VERSION ""

NS_ :

BS_:

BU_: HUA FLR2 DACU

BO_ 786 FLR_Obj03_Vic1: 48 FLR2
 SG_ FLRObj03_ObjClass : 216|4@1+ (1,0) [0|0] ""  VCM
 SG_ FLRObj03_LongAccVar : 88|8@1+ (0.01,0) [0|2.55] "NotApplicable"  VCM
 SG_ FLRObj03_LifeTime : 24|16@1+ (0.1,0) [0|6553.5] "s"  VCM
 SG_ FLRObj03_LatExtLeft : 266|7@1+ (0.05,0) [0|6.35] "m"  VCM
 SG_ FLRObj03_ObjDynClass : 278|2@1+ (1,0) [0|0] ""  VCM
 SG_ FLRObj03_LongVel : 240|13@1+ (0.032,-80) [-80|182.112] "m_per_s"  VCM
 SG_ FLRObj03_ObstacleConf : 297|7@1+ (0.01,0) [0|1.27] "NotApplicable"  VCM
 SG_ FLRObj03_LatExtRight : 193|7@1+ (0.05,-5) [-5|1.35] "m"  VCM
 SG_ FLRObj03_CRC : 0|16@1+ (1,0) [0|65535] "NotApplicable"  VCM
 SG_ FLRObj03_Height : 220|4@1+ (0.5,0) [0|7.5] "m"  VCM
 SG_ FLRObj03_LatExtRtVar : 64|8@1+ (0.01,0) [0|2.55] "NotApplicable"  VCM
 SG_ FLRObj03_AsilLvl : 304|2@1+ (1,0) [0|0] ""  VCM
 SG_ FLRObj03_TimeStamp : 200|16@1+ (0.1,0) [0|6553.5] "ms"  VCM
 SG_ FLRObj03_ExistConf : 290|7@1+ (0.01,0) [0|1.27] "NotApplicable"  VCM
 SG_ FLRObj03_LatExtLeftVar : 56|8@1+ (0.01,0) [0|2.55] "NotApplicable"  VCM
 SG_ FLRObj03_ObstacleConfRestricted : 308|7@1+ (0.01,0) [0|1.27] "NotApplicable"  VCM
 SG_ FLRObj03_Heading : 157|11@1+ (0.005818,-4.71) [-4.71|7.199446] "rad"  VCM
 SG_ FLRObj03_LatPosVar : 72|8@1+ (0.01,0) [0|2.55] "NotApplicable"  VCM
 SG_ FLRObj03_LatPos : 128|13@1+ (0.05,-180) [-180|229.55] "m"  VCM
 SG_ FLRObj03_LongExtBkVar : 96|8@1+ (0.01,0) [0|2.55] "NotApplicable"  VCM
 SG_ FLRObj03_CoastIndex : 273|5@1+ (1,0) [0|31] "NotApplicable"  VCM
 SG_ FLRObj03_LatAccVar : 48|8@1+ (0.1,0) [0|25.5] "NotApplicable"  VCM
 SG_ FLRObj03_LongAcc : 184|9@1+ (0.08,-20) [-20|20.88] "m_per_s_squared"  VCM
 SG_ FLRObj03_ObjDynClassRestricted : 306|2@1+ (1,0) [0|0] ""  VCM
 SG_ FLRObj03_ObjClassConf : 177|7@1+ (0.01,0) [0|1.27] "NotApplicable"  VCM
 SG_ FLRObj03_LatVel : 144|13@1+ (0.032,-80) [-80|182.112] "m_per_s"  VCM
 SG_ FLRObj03_LongExtFront : 224|10@1+ (0.05,0) [0|51.15] "m"  VCM
 SG_ FLRObj03_LongVelVar : 120|8@1+ (0.01,0) [0|2.55] "NotApplicable"  VCM
 SG_ FLRObj03_LatVelVar : 80|8@1+ (0.1,0) [0|25.5] "NotApplicable"  VCM
 SG_ FLRObj03_LongExtBack : 280|10@1+ (0.05,-50) [-50|1.15000000000001] "m"  VCM
 SG_ FLRObj03_LongPos : 253|13@1+ (0.05,-180) [-180|229.55] "m"  VCM
 SG_ FLRObj03_HeadingVar : 40|8@1+ (0.001,0) [0|0.255] "NotApplicable"  VCM
 SG_ FLRObj03_LongPosVar : 112|8@1+ (0.01,0) [0|2.55] "NotApplicable"  VCM
 SG_ FLRObj03_ObjID : 234|6@1+ (1,0) [0|63] "NotApplicable"  VCM
 SG_ FLRObj03_LongExtFrVar : 104|8@1+ (0.01,0) [0|2.55] "NotApplicable"  VCM
 SG_ FLRObj03_LatAcc : 168|9@1+ (0.08,-20) [-20|20.88] "m_per_s_squared"  VCM
 SG_ FLRObj03_Counter : 16|8@1+ (1,0) [0|255] "Count"  VCM
 SG_ FLRObj03_TrackStatus : 141|3@1+ (1,0) [0|0] ""  VCM

BO_ 785 FLR_Obj02_Vic1: 48 FLR2
 SG_ FLRObj02_CoastIndex : 273|5@1+ (1,0) [0|31] "NotApplicable"  VCM
 SG_ FLRObj02_LongExtBack : 280|10@1+ (0.05,-50) [-50|1.15000000000001] "m"  VCM
 SG_ FLRObj02_ObstacleConfRestricted : 308|7@1+ (0.01,0) [0|1.27] "NotApplicable"  VCM
 SG_ FLRObj02_LatVel : 144|13@1+ (0.032,-80) [-80|182.112] "m_per_s"  VCM
 SG_ FLRObj02_ObstacleConf : 297|7@1+ (0.01,0) [0|1.27] "NotApplicable"  VCM
 SG_ FLRObj02_AsilLvl : 304|2@1+ (1,0) [0|0] ""  VCM
 SG_ FLRObj02_LatExtLeft : 266|7@1+ (0.05,0) [0|6.35] "m"  VCM
 SG_ FLRObj02_CRC : 0|16@1+ (1,0) [0|65535] "NotApplicable"  VCM
 SG_ FLRObj02_LongVelVar : 120|8@1+ (0.01,0) [0|2.55] "NotApplicable"  VCM
 SG_ FLRObj02_Counter : 16|8@1+ (1,0) [0|255] "Count"  VCM
 SG_ FLRObj02_LongPos : 253|13@1+ (0.05,-180) [-180|229.55] "m"  VCM
 SG_ FLRObj02_LatExtLeftVar : 56|8@1+ (0.01,0) [0|2.55] "NotApplicable"  VCM
 SG_ FLRObj02_LongExtBkVar : 96|8@1+ (0.01,0) [0|2.55] "NotApplicable"  VCM
 SG_ FLRObj02_LongVel : 240|13@1+ (0.032,-80) [-80|182.112] "m_per_s"  VCM
 SG_ FLRObj02_ObjDynClassRestricted : 306|2@1+ (1,0) [0|0] ""  VCM
 SG_ FLRObj02_LongExtFront : 224|10@1+ (0.05,0) [0|51.15] "m"  VCM
 SG_ FLRObj02_LongAccVar : 88|8@1+ (0.01,0) [0|2.55] "NotApplicable"  VCM
 SG_ FLRObj02_LatAccVar : 48|8@1+ (0.1,0) [0|25.5] "NotApplicable"  VCM
 SG_ FLRObj02_LongPosVar : 112|8@1+ (0.01,0) [0|2.55] "NotApplicable"  VCM
 SG_ FLRObj02_LatExtRtVar : 64|8@1+ (0.01,0) [0|2.55] "NotApplicable"  VCM
 SG_ FLRObj02_LatPos : 128|13@1+ (0.05,-180) [-180|229.55] "m"  VCM
 SG_ FLRObj02_ExistConf : 290|7@1+ (0.01,0) [0|1.27] "NotApplicable"  VCM
 SG_ FLRObj02_LongExtFrVar : 104|8@1+ (0.01,0) [0|2.55] "NotApplicable"  VCM
 SG_ FLRObj02_ObjClass : 216|4@1+ (1,0) [0|0] ""  VCM
 SG_ FLRObj02_Heading : 157|11@1+ (0.005818,-4.71) [-4.71|7.199446] "rad"  VCM
 SG_ FLRObj02_TimeStamp : 200|16@1+ (0.1,0) [0|6553.5] "ms"  VCM
 SG_ FLRObj02_ObjClassConf : 177|7@1+ (0.01,0) [0|1.27] "NotApplicable"  VCM
 SG_ FLRObj02_Height : 220|4@1+ (0.5,0) [0|7.5] "m"  VCM
 SG_ FLRObj02_LifeTime : 24|16@1+ (0.1,0) [0|6553.5] "s"  VCM
 SG_ FLRObj02_TrackStatus : 141|3@1+ (1,0) [0|0] ""  VCM
 SG_ FLRObj02_LatAcc : 168|9@1+ (0.08,-20) [-20|20.88] "m_per_s_squared"  VCM
 SG_ FLRObj02_LatVelVar : 80|8@1+ (0.1,0) [0|25.5] "NotApplicable"  VCM
 SG_ FLRObj02_ObjDynClass : 278|2@1+ (1,0) [0|0] ""  VCM
 SG_ FLRObj02_ObjID : 234|6@1+ (1,0) [0|63] "NotApplicable"  VCM
 SG_ FLRObj02_LatExtRight : 193|7@1+ (0.05,-5) [-5|1.35] "m"  VCM
 SG_ FLRObj02_LatPosVar : 72|8@1+ (0.01,0) [0|2.55] "NotApplicable"  VCM
 SG_ FLRObj02_HeadingVar : 40|8@1+ (0.001,0) [0|0.255] "NotApplicable"  VCM
 SG_ FLRObj02_LongAcc : 184|9@1+ (0.08,-20) [-20|20.88] "m_per_s_squared"  VCM

BO_ 784 FLR_Obj01_Vic1: 48 FLR2
 SG_ FLRObj01_LatPos : 128|13@1+ (0.05,-180) [-180|229.55] "m"  VCM
 SG_ FLRObj01_LifeTime : 24|16@1+ (0.1,0) [0|6553.5] "s"  VCM
 SG_ FLRObj01_LongExtBack : 280|10@1+ (0.05,-50) [-50|1.15000000000001] "m"  VCM
 SG_ FLRObj01_TimeStamp : 200|16@1+ (0.1,0) [0|6553.5] "ms"  VCM
 SG_ FLRObj01_LongVelVar : 120|8@1+ (0.01,0) [0|2.55] "NotApplicable"  VCM
 SG_ FLRObj01_LatExtRight : 193|7@1+ (0.05,-5) [-5|1.35] "m"  VCM
 SG_ FLRObj01_ObstacleConfRestricted : 308|7@1+ (0.01,0) [0|1.27] "NotApplicable"  VCM
 SG_ FLRObj01_ObjID : 234|6@1+ (1,0) [0|63] "NotApplicable"  VCM
 SG_ FLRObj01_Counter : 16|8@1+ (1,0) [0|255] "Count"  VCM
 SG_ FLRObj01_LongExtBkVar : 96|8@1+ (0.01,0) [0|2.55] "NotApplicable"  VCM
 SG_ FLRObj01_CRC : 0|16@1+ (1,0) [0|65535] "NotApplicable"  VCM
 SG_ FLRObj01_AsilLvl : 304|2@1+ (1,0) [0|0] ""  VCM
 SG_ FLRObj01_HeadingVar : 40|8@1+ (0.001,0) [0|0.255] "NotApplicable"  VCM
 SG_ FLRObj01_Heading : 157|11@1+ (0.005818,-4.71) [-4.71|7.199446] "rad"  VCM
 SG_ FLRObj01_ObjClass : 216|4@1+ (1,0) [0|0] ""  VCM
 SG_ FLRObj01_LatVelVar : 80|8@1+ (0.1,0) [0|25.5] "NotApplicable"  VCM
 SG_ FLRObj01_LongPos : 253|13@1+ (0.05,-180) [-180|229.55] "m"  VCM
 SG_ FLRObj01_LongAcc : 184|9@1+ (0.08,-20) [-20|20.88] "m_per_s_squared"  VCM
 SG_ FLRObj01_LongPosVar : 112|8@1+ (0.01,0) [0|2.55] "NotApplicable"  VCM
 SG_ FLRObj01_ObjClassConf : 177|7@1+ (0.01,0) [0|1.27] "NotApplicable"  VCM
 SG_ FLRObj01_LatExtLeftVar : 56|8@1+ (0.01,0) [0|2.55] "NotApplicable"  VCM
 SG_ FLRObj01_LatAccVar : 48|8@1+ (0.1,0) [0|25.5] "NotApplicable"  VCM
 SG_ FLRObj01_ObjDynClassRestricted : 306|2@1+ (1,0) [0|0] ""  VCM
 SG_ FLRObj01_ExistConf : 290|7@1+ (0.01,0) [0|1.27] "NotApplicable"  VCM
 SG_ FLRObj01_LatAcc : 168|9@1+ (0.08,-20) [-20|20.88] "m_per_s_squared"  VCM
 SG_ FLRObj01_LongVel : 240|13@1+ (0.032,-80) [-80|182.112] "m_per_s"  VCM
 SG_ FLRObj01_CoastIndex : 273|5@1+ (1,0) [0|31] "NotApplicable"  VCM
 SG_ FLRObj01_LongExtFrVar : 104|8@1+ (0.01,0) [0|2.55] "NotApplicable"  VCM
 SG_ FLRObj01_LatExtRtVar : 64|8@1+ (0.01,0) [0|2.55] "NotApplicable"  VCM
 SG_ FLRObj01_LongExtFront : 224|10@1+ (0.05,0) [0|51.15] "m"  VCM
 SG_ FLRObj01_LatPosVar : 72|8@1+ (0.01,0) [0|2.55] "NotApplicable"  VCM
 SG_ FLRObj01_TrackStatus : 141|3@1+ (1,0) [0|0] ""  VCM
 SG_ FLRObj01_LatExtLeft : 266|7@1+ (0.05,0) [0|6.35] "m"  VCM
 SG_ FLRObj01_ObstacleConf : 297|7@1+ (0.01,0) [0|1.27] "NotApplicable"  VCM
 SG_ FLRObj01_ObjDynClass : 278|2@1+ (1,0) [0|0] ""  VCM
 SG_ FLRObj01_LatVel : 144|13@1+ (0.032,-80) [-80|182.112] "m_per_s"  VCM
 SG_ FLRObj01_Height : 220|4@1+ (0.5,0) [0|7.5] "m"  VCM
 SG_ FLRObj01_LongAccVar : 88|8@1+ (0.01,0) [0|2.55] "NotApplicable"  VCM

BO_ 783 FLR_Obj00_Vic1: 48 FLR2
 SG_ FLRObj00_LongVelVar : 120|8@1+ (0.01,0) [0|2.55] "NotApplicable"  VCM
 SG_ FLRObj00_LongPos : 253|13@1+ (0.05,-180) [-180|229.55] "m"  VCM
 SG_ FLRObj00_LongExtBack : 280|10@1+ (0.05,-50) [-50|1.15000000000001] "m"  VCM
 SG_ FLRObj00_LatPosVar : 72|8@1+ (0.01,0) [0|2.55] "NotApplicable"  VCM
 SG_ FLRObj00_LongExtFront : 224|10@1+ (0.05,0) [0|51.15] "m"  VCM
 SG_ FLRObj00_AsilLvl : 304|2@1+ (1,0) [0|0] ""  VCM
 SG_ FLRObj00_LatExtLeft : 266|7@1+ (0.05,0) [0|6.35] "m"  VCM
 SG_ FLRObj00_LongAccVar : 88|8@1+ (0.01,0) [0|2.55] "NotApplicable"  VCM
 SG_ FLRObj00_LifeTime : 24|16@1+ (0.1,0) [0|6553.5] "s"  VCM
 SG_ FLRObj00_LatExtRight : 193|7@1+ (0.05,-5) [-5|1.35] "m"  VCM
 SG_ FLRObj00_ObjDynClass : 278|2@1+ (1,0) [0|0] ""  VCM
 SG_ FLRObj00_LatAcc : 168|9@1+ (0.08,-20) [-20|20.88] "m_per_s_squared"  VCM
 SG_ FLRObj00_Height : 220|4@1+ (0.5,0) [0|7.5] "m"  VCM
 SG_ FLRObj00_LongExtFrVar : 104|8@1+ (0.01,0) [0|2.55] "NotApplicable"  VCM
 SG_ FLRObj00_LatPos : 128|13@1+ (0.05,-180) [-180|229.55] "m"  VCM
 SG_ FLRObj00_LongVel : 240|13@1+ (0.032,-80) [-80|182.112] "m_per_s"  VCM
 SG_ FLRObj00_ObjClassConf : 177|7@1+ (0.01,0) [0|1.27] "NotApplicable"  VCM
 SG_ FLRObj00_ObjID : 234|6@1+ (1,0) [0|63] "NotApplicable"  VCM
 SG_ FLRObj00_LongPosVar : 112|8@1+ (0.01,0) [0|2.55] "NotApplicable"  VCM
 SG_ FLRObj00_TimeStamp : 200|16@1+ (0.1,0) [0|6553.5] "ms"  VCM
 SG_ FLRObj00_ObstacleConf : 297|7@1+ (0.01,0) [0|1.27] "NotApplicable"  VCM
 SG_ FLRObj00_ObjClass : 216|4@1+ (1,0) [0|0] ""  VCM
 SG_ FLRObj00_LongExtBkVar : 96|8@1+ (0.01,0) [0|2.55] "NotApplicable"  VCM
 SG_ FLRObj00_ExistConf : 290|7@1+ (0.01,0) [0|1.27] "NotApplicable"  VCM
 SG_ FLRObj00_LatVelVar : 80|8@1+ (0.1,0) [0|25.5] "NotApplicable"  VCM
 SG_ FLRObj00_CoastIndex : 273|5@1+ (1,0) [0|31] "NotApplicable"  VCM
 SG_ FLRObj00_ObstacleConfRestricted : 308|7@1+ (0.01,0) [0|1.27] "NotApplicable"  VCM
 SG_ FLRObj00_TrackStatus : 141|3@1+ (1,0) [0|0] ""  VCM
 SG_ FLRObj00_LatVel : 144|13@1+ (0.032,-80) [-80|182.112] "m_per_s"  VCM
 SG_ FLRObj00_LongAcc : 184|9@1+ (0.08,-20) [-20|20.88] "m_per_s_squared"  VCM
 SG_ FLRObj00_CRC : 0|16@1+ (1,0) [0|65535] "NotApplicable"  VCM
 SG_ FLRObj00_Heading : 157|11@1+ (0.005818,-4.71) [-4.71|7.199446] "rad"  VCM
 SG_ FLRObj00_ObjDynClassRestricted : 306|2@1+ (1,0) [0|0] ""  VCM
 SG_ FLRObj00_HeadingVar : 40|8@1+ (0.001,0) [0|0.255] "NotApplicable"  VCM
 SG_ FLRObj00_LatAccVar : 48|8@1+ (0.1,0) [0|25.5] "NotApplicable"  VCM
 SG_ FLRObj00_LatExtRtVar : 64|8@1+ (0.01,0) [0|2.55] "NotApplicable"  VCM
 SG_ FLRObj00_LatExtLeftVar : 56|8@1+ (0.01,0) [0|2.55] "NotApplicable"  VCM
 SG_ FLRObj00_Counter : 16|8@1+ (1,0) [0|255] "Count"  VCM

BO_ 860 FLR_LeftRoadBoundary_Vic1: 20 FLR2
 SG_ LeftRoadBoundary_CoastIndex : 75|5@1+ (1,0) [0|31] "NotApplicable"  VCM
 SG_ LeftRoadBoundary_DxStart : 40|8@1+ (1,0) [0|255] "m"  VCM
 SG_ LeftRoadBoundary_LifeTime : 136|16@1+ (0.1,0) [0|6553.5] "s"  VCM
 SG_ LeftRoadBoundary_TimeStamp : 24|16@1+ (0.1,0) [0|6553.5] "ms"  VCM
 SG_ LeftRoadBoundary_HeadingAngle : 80|13@1+ (0.0005,-1.57) [-1.57|2.5255] "rad"  VCM
 SG_ LeftRoadBoundary_Curvature : 96|18@1+ (1E-006,-0.1310705) [-0.1310705|0.1310725] "per_meter"  VCM
 SG_ LeftRoadBoundary_CRC : 0|16@1+ (1,0) [0|65535] "NotApplicable"  VCM
 SG_ LeftRoadBoundary_CurvatureRate : 64|11@1+ (5.1E-007,-0.000516) [-0.000516|0.00052797] "per_meter_squared"  VCM
 SG_ LeftRoadBoundary_Type : 133|3@1+ (1,0) [0|0] ""  VCM
 SG_ LeftRoadBoundary_LatDistVar : 48|8@1+ (0.001,0) [0|0.255] "NotApplicable"  VCM
 SG_ LeftRoadBoundary_TrackStatus : 93|3@1+ (1,0) [0|0] ""  VCM
 SG_ LeftRoadBoundary_Counter : 16|8@1+ (1,0) [0|255] "Count"  VCM
 SG_ LeftRoadBoundary_LatDist : 114|12@1+ (0.005,-10) [-10|10.475] "m"  VCM
 SG_ LeftRoadBoundary_Confidence : 126|7@1+ (0.01,0) [0|1.27] "NotApplicable"  VCM
 SG_ LeftRoadBoundary_DxEnd : 56|8@1+ (1,0) [0|255] "m"  VCM

BO_ 858 FLR_EgoAssumpt_Vic1: 16 FLR2
 SG_ FLREgoAssumpt_EgoRoadEnd : 72|8@1+ (1,0) [0|255] "m"  VCM
 SG_ FLREgoAssumpt_EgoLongAcc : 16|16@1+ (0.00048828125,-15.6875) [-15.6875|16.31201171875] "m_per_s_squared"  VCM
 SG_ FLREgoAssumpt_VelCorrFactor : 64|8@1+ (0.002,0.75) [0.75|1.26] "NotApplicable"  VCM
 SG_ FLREgoAssumpt_EgoRoadCurvRate : 93|11@1+ (5.1E-007,-0.000516) [-0.000516|0.00052797] "per_meter_squared"  VCM
 SG_ FLREgoAssumpt_TimeStamp : 48|16@1+ (0.1,0) [0|6553.5] "ms"  VCM
 SG_ FLREgoAssumpt_EgoYawRate : 32|16@1+ (0.000122,-3.92) [-3.92|4.07527] "Rad_per_s"  VCM
 SG_ FLREgoAssumpt_EgoRoadHeading : 80|13@1+ (0.0005,-1.57) [-1.57|2.5255] "rad"  VCM
 SG_ FLREgoAssumpt_EgoRoadCurvature : 104|18@1+ (1E-006,-0.1310705) [-0.1310705|0.1310725] "per_meter"  VCM
 SG_ FLREgoAssumpt_EgoLongVel : 0|16@1+ (0.00108507,0) [0|71.11006245] "m_per_s"  VCM

BO_ 512 FLR_01P_Vic1: 12 FLR2
 SG_ FwdSensingRadarStat_CRC : 0|16@1+ (1,0) [0|65535] "NotApplicable"  VCM
 SG_ FwdSensingRadarStat_TimeSynch : 24|8@1+ (1,0) [0|0] ""  VCM
 SG_ FwdRdr_CalibPausedYaw : 57|1@1+ (1,0) [0|0] ""  VCM
 SG_ FwdRadarStatus : 60|4@1+ (1,0) [0|0] ""  VCM
 SG_ FwdRdr_CalibState : 58|2@1+ (1,0) [0|0] ""  VCM
 SG_ FwdRdr_CalibPausedAcc : 55|1@1+ (1,0) [0|0] ""  VCM
 SG_ FwdSensingRadarStat_Counter : 16|8@1+ (1,0) [0|255] "Count"  VCM
 SG_ FwdRadarStatus2_CRC : 64|16@1+ (1,0) [0|65535] "NotApplicable"  VCM
 SG_ FwdRdr_CalibPausedSpeed : 56|1@1+ (1,0) [0|0] ""  VCM
 SG_ FwdRadarStatus2_Status : 88|4@1+ (1,0) [0|0] ""  VCM
 SG_ FwdSensingRadarStat_DecalDetect : 38|3@1+ (1,0) [0|0] ""  VCM
 SG_ FwdRdr_CalibProgress : 48|7@1+ (1,0) [0|127] "Percent"  VCM
 SG_ FwdRadarStatus2_SqC : 80|8@1+ (1,0) [0|255] "NotApplicable"  VCM
 SG_ FwdSensingRadarStat_TargetDetect : 35|3@1+ (1,0) [0|0] ""  VCM
 SG_ FwdSensingRadarStat_BarrierDetec : 32|3@1+ (1,0) [0|0] ""  VCM

BO_ 1959 FLR2_Debug07_Vic1: 64 FLR2
 SG_ Debug_07_FLR2 : 0|512@1+ (1,0) [0|0] "" Vector__XXX

BO_ 1958 FLR2_Debug06_Vic1: 64 FLR2
 SG_ Debug_06_FLR2 : 0|512@1+ (1,0) [0|0] "" Vector__XXX

BO_ 1957 FLR2_Debug05_Vic1: 64 FLR2
 SG_ Debug_05_FLR2 : 0|512@1+ (1,0) [0|0] "" Vector__XXX

BO_ 1956 FLR2_Debug04_Vic1: 64 FLR2
 SG_ Debug_04_FLR2 : 0|512@1+ (1,0) [0|0] "" Vector__XXX

BO_ 1955 FLR2_Debug03_Vic1: 64 FLR2
 SG_ Debug_03_FLR2 : 0|512@1+ (1,0) [0|0] "" Vector__XXX

BO_ 1954 FLR2_Debug02_Vic1: 64 Vector__XXX
 SG_ Debug_02_FLR2 : 0|512@1+ (1,0) [0|0] ""  FLR2

BO_ 1953 FLR2_Debug01_Vic1: 64 Vector__XXX
 SG_ Debug_01_FLR2 : 0|512@1+ (1,0) [0|0] ""  FLR2

BO_ 2671964754 DiagUUDTRespMsg1_F2_52_Vic1: 8 FLR2
 SG_ DiagUUDTRespSig_F2_52 : 0|64@1+ (1,0) [0|0] ""  VCM

BO_ 2671834194 DiagRespMsgIntTGW2_F4_52_Vic1: 8 FLR2
 SG_ InternalTesterDiagSig_F4_52 : 0|64@1+ (1,0) [0|0] ""  VCM

BO_ 2671833938 DiagRespMsgIntHMIIOM_F3_52_Vic1: 8 FLR2
 SG_ InternalTesterDiagSig_F3_52 : 0|64@1+ (1,0) [0|0] ""  VCM

BO_ 2671792884 DiagReqMsgIntTGW2_52_F4_Vic1: 8 DACU
 SG_ InternalTesterDiagSig_52_F4 : 0|64@1+ (1,0) [0|0] ""  FLR2

BO_ 2671792883 DiagReqMsgIntHMIIOM_52_F3_Vic1: 8 DACU
 SG_ InternalTesterDiagSig_52_F3 : 0|64@1+ (1,0) [0|0] ""  FLR2

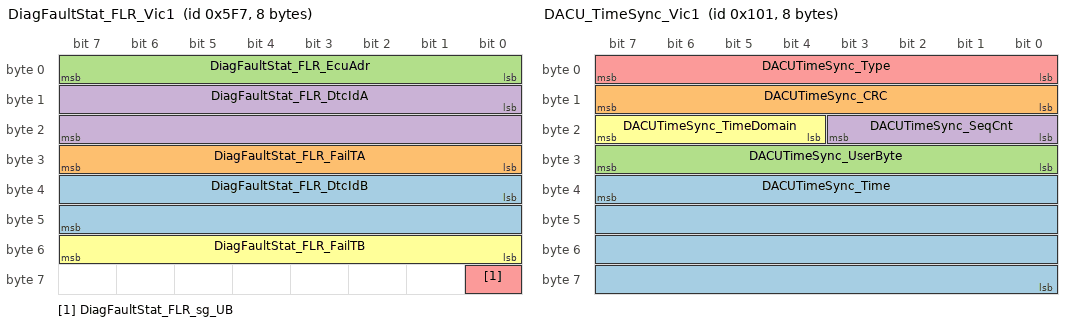
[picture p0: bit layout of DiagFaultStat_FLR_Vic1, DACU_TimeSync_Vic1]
BO_ 1527 DiagFaultStat_FLR_Vic1: 8 FLR2
 SG_ DiagFaultStat_FLR_DtcIdB : 32|16@1+ (1,0) [0|65535] ""  VCM
 SG_ DiagFaultStat_FLR_FailTA : 24|8@1+ (1,0) [0|255] ""  VCM
 SG_ DiagFaultStat_FLR_EcuAdr : 0|8@1+ (1,0) [0|255] ""  VCM
 SG_ DiagFaultStat_FLR_DtcIdA : 8|16@1+ (1,0) [0|65535] ""  VCM
 SG_ DiagFaultStat_FLR_sg_UB : 56|1@1+ (1,0) [0|0] ""  VCM
 SG_ DiagFaultStat_FLR_FailTB : 48|8@1+ (1,0) [0|255] ""  VCM

BO_ 257 DACU_TimeSync_Vic1: 8 DACU
 SG_ DACUTimeSync_Time : 39|32@0+ (1,0) [0|0] ""  FLR2
 SG_ DACUTimeSync_CRC : 15|8@0+ (1,0) [0|0] ""  FLR2
 SG_ DACUTimeSync_UserByte : 31|8@0+ (1,0) [0|0] ""  FLR2
 SG_ DACUTimeSync_SeqCnt : 19|4@0+ (1,0) [0|15] "Count"  FLR2
 SG_ DACUTimeSync_Type : 7|8@0+ (1,0) [0|0] ""  FLR2
 SG_ DACUTimeSync_TimeDomain : 23|4@0+ (1,0) [0|15] "Count"  FLR2

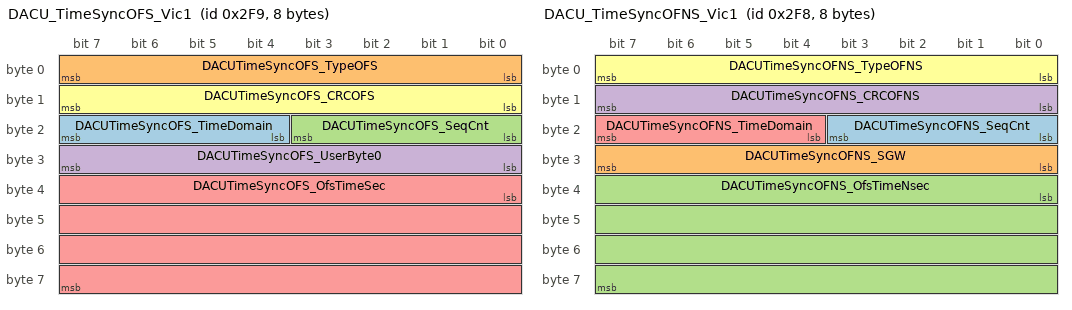
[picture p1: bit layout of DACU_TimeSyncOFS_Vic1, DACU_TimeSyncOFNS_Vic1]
BO_ 761 DACU_TimeSyncOFS_Vic1: 8 DACU
 SG_ DACUTimeSyncOFS_TimeDomain : 20|4@1+ (1,16) [16|31] "NotApplicable"  FLR2
 SG_ DACUTimeSyncOFS_TypeOFS : 0|8@1+ (1,0) [0|0] ""  FLR2
 SG_ DACUTimeSyncOFS_SeqCnt : 16|4@1+ (1,0) [0|15] "Count"  FLR2
 SG_ DACUTimeSyncOFS_UserByte0 : 24|8@1+ (1,0) [0|0] ""  FLR2
 SG_ DACUTimeSyncOFS_OfsTimeSec : 32|32@1+ (1,0) [0|0] ""  FLR2
 SG_ DACUTimeSyncOFS_CRCOFS : 8|8@1+ (1,0) [0|0] ""  FLR2

BO_ 760 DACU_TimeSyncOFNS_Vic1: 8 DACU
 SG_ DACUTimeSyncOFNS_SeqCnt : 16|4@1+ (1,0) [0|15] "Count"  FLR2
 SG_ DACUTimeSyncOFNS_SGW : 24|8@1+ (1,0) [0|0] ""  FLR2
 SG_ DACUTimeSyncOFNS_OfsTimeNsec : 32|32@1+ (1,0) [0|0] ""  FLR2
 SG_ DACUTimeSyncOFNS_CRCOFNS : 8|8@1+ (1,0) [0|0] ""  FLR2
 SG_ DACUTimeSyncOFNS_TimeDomain : 20|4@1+ (1,16) [16|31] "NotApplicable"  FLR2
 SG_ DACUTimeSyncOFNS_TypeOFNS : 0|8@1+ (1,0) [0|0] ""  FLR2

BO_ 279 DACU_EgoPathPrediction_Vic1: 16 DACU
 SG_ EgoPathPrediction_Curvature : 96|18@1+ (1E-006,-0.1310705) [-0.1310705|0.1310725] "per_meter"  FLR2
 SG_ EgoPathPrediction_HeadingAngle : 72|13@1+ (0.0005,-1.57) [-1.57|2.5255] "rad"  FLR2
 SG_ EgoPathPrediction_CurvatureRate : 85|11@1+ (5.1E-007,-0.000516) [-0.000516|0.00052797] "per_meter_squared"  FLR2
 SG_ EgoPathPrediction_ConfCoeffA1 : 40|16@1+ (0.001,-30) [-30|35.535] "NotApplicable"  FLR2
 SG_ EgoPathPrediction_DxEnd : 0|8@1+ (1,-126) [-126|129] "m"  FLR2
 SG_ EgoPathPrediction_ConfCoeffA3 : 56|16@1+ (0.001,-30) [-30|35.535] "NotApplicable"  FLR2
 SG_ EgoPathPrediction_ConfCoeffA0 : 8|16@1+ (0.001,-30) [-30|35.535] "NotApplicable"  FLR2
 SG_ EgoPathPrediction_ConfCoeffA2 : 24|16@1+ (0.001,-30) [-30|35.535] "NotApplicable"  FLR2

BO_ 275 DACU_EgoMotion_Vic1: 32 DACU
 SG_ EgoMotionXYplane_LongMotDirConf : 190|4@1+ (1,0) [0|0] ""  FLR2
 SG_ EgoMotionXYplane_LongSpeed : 104|16@1+ (0.00108507,0) [0|71.11006245] "m_per_s"  FLR2
 SG_ EgoMotionXYplane_EffectiveWheelB : 224|10@1+ (10,2000) [2000|12230] "mm"  FLR2
 SG_ EgoMotionXYplane_LatAccVariance : 194|6@1+ (0.1,0) [0|6.3] "NotApplicable"  FLR2
 SG_ EgoMotionXYplane_YawRateVariance : 120|16@1+ (3.846154E-005,0) [0|2.5205770239] "NotApplicable"  FLR2
 SG_ EgoMotionXYplane_LateralSpeed : 152|16@1+ (0.00108507,-35) [-35|36.11006245] "m_per_s"  FLR2
 SG_ EgoMotionXYplane_LongSpeedVar : 72|16@1+ (0.00115384616,0) [0|75.6173080956] "NotApplicable"  FLR2
 SG_ EgoMotionXYplane_LateralAcc : 56|16@1+ (0.00048828125,-15.687) [-15.687|16.31251171875] "m_per_s_squared"  FLR2
 SG_ EgoMotionXYplane_LongMotionDir : 221|3@1+ (1,0) [0|0] ""  FLR2
 SG_ EgoMotionXYplane_LatencyEst : 176|8@1+ (1,0) [0|255] "ms"  FLR2
 SG_ EgoMotionXYplane_LongAcc : 24|16@1+ (0.00048828125,-15.687) [-15.687|16.31251171875] "m_per_s_squared"  FLR2
 SG_ EgoMotionXYplane_Counter : 16|8@1+ (1,0) [0|255] "Count"  FLR2
 SG_ EgoMotionXYplane_Curvature : 200|21@1+ (1E-006,-1.0486) [-1.0486|1.048551] "per_meter"  FLR2
 SG_ EgoMotionXYplane_CRC : 0|16@1+ (1,0) [0|65535] "NotApplicable"  FLR2
 SG_ EgoMotionXYplane_ReferencePointX : 40|16@1+ (0.001,-32) [-32|33.535] "m"  FLR2
 SG_ EgoMotionXYplane_LongAccVariance : 184|6@1+ (0.1,0) [0|6.3] "NotApplicable"  FLR2
 SG_ EgoMotionXYplane_YawRateComp : 136|16@1+ (0.000122,-3.92) [-3.92|4.07527] "Rad_per_s"  FLR2
 SG_ EgoMotionXYplane_ChassisDynPitch : 168|8@1+ (0.001,-0.126) [-0.126|0.129] "rad"  FLR2
 SG_ EgoMotionXYplane_LatSpeedVar : 88|16@1+ (0.00153846154,0) [0|100.8230770239] "NotApplicable"  FLR2

BO_ 277 DACU_EgoMotionRaw_Vic1: 32 DACU
 SG_ EgoMotionRaw_YCEngineActive : 142|2@1+ (1,0) [0|0] ""  FLR2
 SG_ EgoMotionRaw_ASREngineA : 152|2@1+ (1,0) [0|0] ""  FLR2
 SG_ EgoMotionRaw_ASRBrakeA : 156|2@1+ (1,0) [0|0] ""  FLR2
 SG_ EgoMotionRaw_RelLvlRrAxleRight : 176|16@1+ (0.1,-3200) [-3200|3353.5] "mm"  FLR2
 SG_ EgoMotionRaw_ROPBrakeActive : 150|2@1+ (1,0) [0|0] ""  FLR2
 SG_ EgoMotionRaw_Counter : 16|8@1+ (1,0) [0|255] "Count"  FLR2
 SG_ EgoMotionRaw_RelLvlRrAxleLeft : 160|16@1+ (0.1,-3200) [-3200|3353.5] "mm"  FLR2
 SG_ EgoMotionRaw_AccKckDwn : 158|2@1+ (1,0) [0|0] ""  FLR2
 SG_ EgoMotionRaw_VDCFullyOperational : 146|2@1+ (1,0) [0|0] ""  FLR2
 SG_ EgoMotionRaw_FrontWheelAngle : 56|16@1+ (5E-005,-1.6) [-1.6|1.67675] "rad"  FLR2
 SG_ EgoMotionRaw_BrakePedalPosition : 120|8@1+ (0.4,0) [0|102] "Percent"  FLR2
 SG_ EgoMotionRaw_ABSOp : 244|2@1+ (1,0) [0|0] ""  FLR2
 SG_ EgoMotionRaw_RAxleRightWSpeed : 88|16@1+ (0.00390625,0) [0|255.99609375] "Km_per_h"  FLR2
 SG_ EgoMotionRaw_GrossCombVehWeight : 224|16@1+ (10,0) [0|655350] "kg"  FLR2
 SG_ EgoMotionRaw_CRC : 0|16@1+ (1,0) [0|65535] "NotApplicable"  FLR2
 SG_ EgoMotionRaw_FrAxleRightWSpeed : 40|16@1+ (0.00390625,0) [0|255.99609375] "Km_per_h"  FLR2
 SG_ EgoMotionRaw_ABSActive : 144|2@1+ (1,0) [0|0] ""  FLR2
 SG_ EgoMotionRaw_SteeringWheelAngle : 104|16@1+ (0.0009765625,-31.374) [-31.374|32.6250234375] "rad"  FLR2
 SG_ EgoMotionRaw_RelLvlFrAxleLeft : 192|16@1+ (0.1,-3200) [-3200|3353.5] "mm"  FLR2
 SG_ EgoMotionRaw_ROPEngineActive : 148|2@1+ (1,0) [0|0] ""  FLR2
 SG_ EgoMotionRaw_FrAxleLeftWSpeed : 24|16@1+ (0.00390625,0) [0|255.99609375] "Km_per_h"  FLR2
 SG_ EgoMotionRaw_YCBrakeActive : 154|2@1+ (1,0) [0|0] ""  FLR2
 SG_ EgoMotionRaw_SteeringWheelRatio : 136|6@1+ (1,0) [0|63] "NotApplicable"  FLR2
 SG_ EgoMotionRaw_AccPedalPos : 128|8@1+ (0.4,0) [0|102] "Percent"  FLR2
 SG_ EgoMotionRaw_RelLvlFrAxleRight : 208|16@1+ (0.1,-3200) [-3200|3353.5] "mm"  FLR2
 SG_ EgoMotionRaw_RAxleLeftWSpeed : 72|16@1+ (0.00390625,0) [0|255.99609375] "Km_per_h"  FLR2
 SG_ EgoMotionRaw_TrailerConStatus : 240|4@1+ (1,0) [0|0] ""  FLR2

BO_ 1976 DACU_Debug21_Vic1: 64 DACU
 SG_ Debug_21_DACU : 0|512@1+ (1,0) [0|0] "" Vector__XXX

BO_ 1975 DACU_Debug20_Vic1: 64 DACU
 SG_ Debug_20_DACU : 0|512@1+ (1,0) [0|0] "" Vector__XXX

BO_ 1974 DACU_Debug19_Vic1: 64 DACU
 SG_ Debug_19_DACU : 0|512@1+ (1,0) [0|0] "" Vector__XXX

BO_ 1973 DACU_Debug18_Vic1: 64 DACU
 SG_ Debug_18_DACU : 0|512@1+ (1,0) [0|0] "" Vector__XXX

BO_ 1972 DACU_Debug17_Vic1: 64 DACU
 SG_ Debug_17_DACU : 0|512@1+ (1,0) [0|0] "" Vector__XXX

BO_ 1971 DACU_Debug16_Vic1: 64 DACU
 SG_ Debug_16_DACU : 0|512@1+ (1,0) [0|0] "" Vector__XXX

BO_ 1970 DACU_Debug15_Vic1: 64 DACU
 SG_ Debug_15_DACU : 0|512@1+ (1,0) [0|0] "" Vector__XXX

BO_ 1969 DACU_Debug14_Vic1: 64 DACU
 SG_ Debug_14_DACU : 0|512@1+ (1,0) [0|0] "" Vector__XXX

BO_ 333 DACU_06P_Vic1: 20 DACU
 SG_ HUALEDCtrl06_Orange : 104|8@1+ (1,0) [0|0] ""  HUA
 SG_ HUALEDCtrl04_Orange : 72|8@1+ (1,0) [0|0] ""  HUA
 SG_ HUALEDCtrl04_Red : 64|8@1+ (1,0) [0|0] ""  HUA
 SG_ HUALEDCtrl03_Orange : 56|8@1+ (1,0) [0|0] ""  HUA
 SG_ HUASelfTestCtrl : 141|2@1+ (1,0) [0|0] ""  HUA
 SG_ HUALEDCtrl03_Red : 48|8@1+ (1,0) [0|0] ""  HUA
 SG_ HUALEDCtrl02_Orange : 40|8@1+ (1,0) [0|0] ""  HUA
 SG_ HUALEDCtrl02_Red : 32|8@1+ (1,0) [0|0] ""  HUA
 SG_ HUALEDCtrl01_Orange : 24|8@1+ (1,0) [0|0] ""  HUA
 SG_ HUALEDCtrl00_Red : 0|8@1+ (1,0) [0|0] ""  HUA
 SG_ HUALEDCtrl00_Orange : 8|8@1+ (1,0) [0|0] ""  HUA
 SG_ HUALEDCtrl01_Red : 16|8@1+ (1,0) [0|0] ""  HUA
 SG_ HUAFading_Fadingtime : 128|8@1+ (10,0) [0|2550] "ms"  HUA
 SG_ HUAFlashingFrequency : 137|4@1+ (1,0) [0|0] ""  HUA
 SG_ HUABrightnessMode : 143|4@1+ (1,0) [0|15] ""  HUA
 SG_ HUAFading_FadingCtrl : 136|1@1+ (1,0) [0|0] ""  HUA
 SG_ HUALEDCtrl05_Red : 80|8@1+ (1,0) [0|0] ""  HUA
 SG_ HUALEDCtrl05_Orange : 88|8@1+ (1,0) [0|0] ""  HUA
 SG_ HUALEDCtrl06_Red : 96|8@1+ (1,0) [0|0] ""  HUA

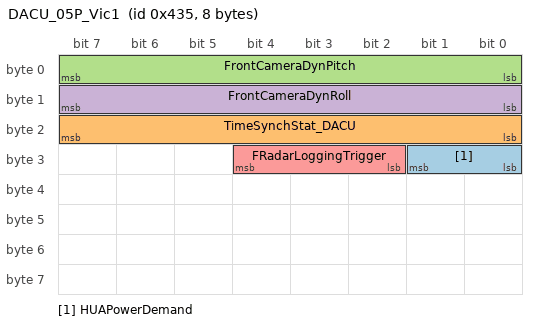
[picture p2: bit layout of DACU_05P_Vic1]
BO_ 1077 DACU_05P_Vic1: 8 DACU
 SG_ HUAPowerDemand : 24|2@1+ (1,0) [0|0] ""  HUA
 SG_ TimeSynchStat_DACU : 16|8@1+ (1,0) [0|0] ""  FLR2
 SG_ FrontCameraDynPitch : 0|8@1+ (0.0013,-0.12) [-0.12|0.2115] "rad"  FLR2
 SG_ FrontCameraDynRoll : 8|8@1+ (0.0013,-0.12) [-0.12|0.2115] "rad"  FLR2
 SG_ FRadarLoggingTrigger : 26|3@1+ (1,0) [0|0] ""  FLR2

BO_ 1543 DACU_04P_Vic1: 20 DACU
 SG_ VIN_DACU_Byte02 : 16|8@1+ (1,0) [0|0] ""  FLR2
 SG_ VIN_DACU_Byte09 : 72|8@1+ (1,0) [0|0] ""  FLR2
 SG_ VIN_DACU_Byte04 : 32|8@1+ (1,0) [0|0] ""  FLR2
 SG_ VIN_DACU_Byte07 : 56|8@1+ (1,0) [0|0] ""  FLR2
 SG_ VIN_DACU_Byte11 : 88|8@1+ (1,0) [0|0] ""  FLR2
 SG_ VIN_DACU_Byte06 : 48|8@1+ (1,0) [0|0] ""  FLR2
 SG_ VIN_DACU_Byte08 : 64|8@1+ (1,0) [0|0] ""  FLR2
 SG_ VIN_DACU_Byte15 : 120|8@1+ (1,0) [0|0] ""  FLR2
 SG_ VIN_DACU_Byte14 : 112|8@1+ (1,0) [0|0] ""  FLR2
 SG_ VIN_DACU_Byte16 : 128|8@1+ (1,0) [0|0] ""  FLR2
 SG_ VIN_DACU_Byte12 : 96|8@1+ (1,0) [0|0] ""  FLR2
 SG_ VIN_DACU_Byte01 : 8|8@1+ (1,0) [0|0] ""  FLR2
 SG_ VIN_DACU_Byte10 : 80|8@1+ (1,0) [0|0] ""  FLR2
 SG_ VIN_DACU_Byte03 : 24|8@1+ (1,0) [0|0] ""  FLR2
 SG_ VIN_DACU_Byte00 : 0|8@1+ (1,0) [0|0] ""  FLR2
 SG_ VIN_DACU_Byte05 : 40|8@1+ (1,0) [0|0] ""  FLR2
 SG_ VIN_DACU_Byte13 : 104|8@1+ (1,0) [0|0] ""  FLR2

BO_ 1265 DACU_03P_Vic1: 20 DACU
 SG_ TachographLocalHourOffset : 19|8@1+ (1,-125) [-125|130] "h"  FLR2
 SG_ VehicleMode : 4|4@1+ (1,0) [0|0] ""  HUA,FLR2
 SG_ AmbientAirTemperature : 107|16@1+ (0.03125,-273) [-273|1774.96875] "DegreeC"  FLR2
 SG_ DayUTC : 43|8@1+ (0.25,0) [0|63.75] "Days"  FLR2
 SG_ TotalVehicleDistanceHighRes : 75|32@1+ (5,0) [0|21474836475] "m"  FLR2
 SG_ TachographLocalMinuteOffset : 67|8@1+ (1,-125) [-125|130] "min"  FLR2
 SG_ VehicleMode_UB : 18|1@1+ (1,0) [0|0] ""  HUA,FLR2
 SG_ SecondsUTC : 59|8@1+ (0.25,0) [0|63.75] "s"  FLR2
 SG_ YearUTC : 27|8@1+ (1,1985) [1985|2240] "Years"  FLR2
 SG_ TrailerConnected : 16|2@1+ (1,0) [0|0] ""  FLR2
 SG_ MonthUTC : 51|8@1+ (1,0) [0|255] "Months"  FLR2
 SG_ HoursUTC : 123|8@1+ (1,0) [0|255] "h"  FLR2
 SG_ PloughLampModeStatus : 14|2@1+ (1,0) [0|0] ""  FLR2
 SG_ LaneChangeStatus : 0|4@1+ (1,0) [0|0] ""  FLR2
 SG_ WiperModeStatus : 8|3@1+ (1,0) [0|0] ""  FLR2
 SG_ MinutesUTC : 35|8@1+ (1,0) [0|255] "min"  FLR2
 SG_ FLRPowerDemand : 11|2@1+ (1,0) [0|0] ""  FLR2

BO_ 1552 DACUSwVersion_Vic1: 64 DACU
 SG_ DACUSwVersion_Substring0 : 0|64@1+ (1,0) [0|0] ""  FLR2
 SG_ DACUSwVersion_Substring6 : 384|64@1+ (1,0) [0|0] ""  FLR2
 SG_ DACUSwVersion_Substring2 : 128|64@1+ (1,0) [0|0] ""  FLR2
 SG_ DACUSwVersion_Substring5 : 320|64@1+ (1,0) [0|0] ""  FLR2
 SG_ DACUSwVersion_Substring7 : 448|64@1+ (1,0) [0|0] ""  FLR2
 SG_ DACUSwVersion_Substring1 : 64|64@1+ (1,0) [0|0] ""  FLR2
 SG_ DACUSwVersion_Substring3 : 192|64@1+ (1,0) [0|0] ""  FLR2
 SG_ DACUSwVersion_Substring4 : 256|64@1+ (1,0) [0|0] ""  FLR2

CM_ BO_ 275 "Default 20 msec. TriggeredBy Application";
CM_ BO_ 277 "Default 20 msec. TriggeredBy Application";
CM_ SG_ 1265 TachographLocalHourOffset "254 Error ; 255 Not available";
CM_ SG_ 1265 AmbientAirTemperature "65024 - 65279 Error ; 65280 - 65535 Not available";
CM_ SG_ 1265 DayUTC "254 Error ; 255 Not available";
CM_ SG_ 1265 TotalVehicleDistanceHighRes "4261412864 - 4278190079 Error ; 4278190080 - 4294967295 Not available";
CM_ SG_ 1265 TachographLocalMinuteOffset "254 Error ; 255 Not available";
CM_ SG_ 1265 SecondsUTC "254 Error ; 255 Not available";
CM_ SG_ 1265 YearUTC "254 Error ; 255 Not available";
CM_ SG_ 1265 MonthUTC "254 Error ; 255 Not available";
CM_ SG_ 1265 HoursUTC "254 Error ; 255 Not available";
CM_ SG_ 1265 MinutesUTC "254 Error ; 255 Not available";
BA_DEF_ BO_  "GenMsgStartDelayTime" INT 0 0;
BA_DEF_ BO_  "GenMsgDelayTime" INT 0 0;
BA_DEF_ BO_  "GenMsgCycleTime" INT 0 0;
BA_DEF_ BO_  "GenMsgSendType" ENUM  "Cyclic","NotUsed","NotUsed","NotUsed","NotUsed","NotUsed","NotUsed","IfActive","NoMsgSendType","NotUsed";
BA_DEF_ SG_  "GenSigStartValue" INT 0 0;
BA_DEF_ SG_  "GenSigCycleTimeActive" INT 0 0;
BA_DEF_ SG_  "GenSigCycleTime" INT 0 0;
BA_DEF_ SG_  "GenSigSendType" ENUM  "Cyclic","OnWrite","OnWriteWithRepetition","OnChange","OnChangeWithRepetition","IfActive","IfActiveWithRepetition","NoSigSendType","NotUsed","NotUsed","NotUsed","NotUsed","NotUsed";
BA_DEF_ BO_  "VFrameFormat" ENUM  "StandardCAN","ExtendedCAN","reserved","J1939PG","reserved","reserved","reserved","reserved","reserved","reserved","reserved","reserved","reserved","reserved","StandardCAN_FD","ExtendedCAN_FD";
BA_DEF_ SG_  "SigType" ENUM  "Default","Range","RangeSigned","ASCII","Discrete","Control","ReferencePGN","DTC","StringDelimiter","StringLength","StringLengthControl";
BA_DEF_ SG_  "SeToolVersion_SIGNAL" STRING ;
BA_DEF_ SG_  "SeToolUniqueID_SIGNAL" STRING ;
BA_DEF_ SG_  "SeToolName_SIGNAL" STRING ;
BA_DEF_ SG_  "SeToolItemID_SIGNAL" STRING ;
BA_DEF_ SG_  "SeToolAncestorID_SIGNAL" STRING ;
BA_DEF_ SG_  "NeedsUpdateBit" ENUM  "No","Yes";
BA_DEF_ SG_  "GenSigILSupport" ENUM  "Yes","No";
BA_DEF_ BO_  "GenMsgILSupport" ENUM  "No","Yes";
BA_DEF_ SG_  "E2EProfile" STRING ;
BA_DEF_ SG_  "E2EDataLength" INT 0 65535;
BA_DEF_ SG_  "E2EDataId" INT 0 65535;
BA_DEF_ BO_  "DiagUUDTResponse" ENUM  "No","Yes";
BA_DEF_ BO_  "DiagState" ENUM  "No","Yes";
BA_DEF_ BO_  "DiagResponse" ENUM  "No","Yes";
BA_DEF_ BO_  "DiagRequest" ENUM  "No","Yes";
BA_DEF_ BO_  "DiagConnection" HEX 0 65535;
BA_DEF_ BO_  "CanTpFcFrameId" HEX 0 2147483647;
BA_DEF_ BO_  "CanTpBs" INT 0 255;
BA_DEF_ BO_  "CANFD_BRS" ENUM  "0","1";
BA_DEF_REL_ BU_SG_REL_  "GenSigTimeoutTime" INT 0 65535;
BA_DEF_REL_ BU_SG_REL_  "GenSigFirstTimeoutTime" INT 0 65535;
BA_DEF_DEF_  "GenMsgStartDelayTime" 0;
BA_DEF_DEF_  "GenMsgDelayTime" 0;
BA_DEF_DEF_  "GenMsgCycleTime" 0;
BA_DEF_DEF_  "GenMsgSendType" "Cyclic";
BA_DEF_DEF_  "GenSigStartValue" 0;
BA_DEF_DEF_  "GenSigCycleTimeActive" 0;
BA_DEF_DEF_  "GenSigCycleTime" 0;
BA_DEF_DEF_  "GenSigSendType" "Cyclic";
BA_DEF_DEF_  "VFrameFormat" "ExtendedCAN";
BA_DEF_DEF_  "SigType" "Default";
BA_DEF_DEF_  "SeToolVersion_SIGNAL" "";
BA_DEF_DEF_  "SeToolUniqueID_SIGNAL" "";
BA_DEF_DEF_  "SeToolName_SIGNAL" "";
BA_DEF_DEF_  "SeToolItemID_SIGNAL" "";
BA_DEF_DEF_  "SeToolAncestorID_SIGNAL" "";
BA_DEF_DEF_  "NeedsUpdateBit" "No";
BA_DEF_DEF_  "GenSigILSupport" "Yes";
BA_DEF_DEF_  "GenMsgILSupport" "Yes";
BA_DEF_DEF_  "E2EProfile" "none";
BA_DEF_DEF_  "E2EDataLength" 0;
BA_DEF_DEF_  "E2EDataId" 0;
BA_DEF_DEF_  "DiagUUDTResponse" "No";
BA_DEF_DEF_  "DiagState" "No";
BA_DEF_DEF_  "DiagResponse" "No";
BA_DEF_DEF_  "DiagRequest" "No";
BA_DEF_DEF_  "DiagConnection" 0;
BA_DEF_DEF_  "CanTpFcFrameId" 2147483647;
BA_DEF_DEF_  "CanTpBs" 255;
BA_DEF_DEF_  "CANFD_BRS" "0";
BA_DEF_DEF_REL_ "GenSigTimeoutTime" 0;
BA_DEF_DEF_REL_ "GenSigFirstTimeoutTime" 0;
BA_ "CANFD_BRS" BO_ 786 1;
BA_ "GenMsgSendType" BO_ 786 8;
BA_ "VFrameFormat" BO_ 786 14;
BA_ "CANFD_BRS" BO_ 785 1;
BA_ "GenMsgSendType" BO_ 785 8;
BA_ "VFrameFormat" BO_ 785 14;
BA_ "CANFD_BRS" BO_ 784 1;
BA_ "GenMsgSendType" BO_ 784 8;
BA_ "VFrameFormat" BO_ 784 14;
BA_ "CANFD_BRS" BO_ 783 1;
BA_ "GenMsgSendType" BO_ 783 8;
BA_ "VFrameFormat" BO_ 783 14;
BA_ "CANFD_BRS" BO_ 860 1;
BA_ "GenMsgSendType" BO_ 860 8;
BA_ "VFrameFormat" BO_ 860 14;
BA_ "CANFD_BRS" BO_ 858 1;
BA_ "GenMsgCycleTime" BO_ 858 100;
BA_ "VFrameFormat" BO_ 858 14;
BA_ "CANFD_BRS" BO_ 512 1;
BA_ "GenMsgCycleTime" BO_ 512 200;
BA_ "VFrameFormat" BO_ 512 14;
BA_ "CANFD_BRS" BO_ 1959 1;
BA_ "GenMsgSendType" BO_ 1959 8;
BA_ "GenMsgDelayTime" BO_ 1959 10;
BA_ "VFrameFormat" BO_ 1959 14;
BA_ "CANFD_BRS" BO_ 1958 1;
BA_ "GenMsgSendType" BO_ 1958 8;
BA_ "GenMsgDelayTime" BO_ 1958 10;
BA_ "VFrameFormat" BO_ 1958 14;
BA_ "CANFD_BRS" BO_ 1957 1;
BA_ "GenMsgSendType" BO_ 1957 8;
BA_ "GenMsgDelayTime" BO_ 1957 10;
BA_ "VFrameFormat" BO_ 1957 14;
BA_ "CANFD_BRS" BO_ 1956 1;
BA_ "GenMsgSendType" BO_ 1956 8;
BA_ "GenMsgDelayTime" BO_ 1956 10;
BA_ "VFrameFormat" BO_ 1956 14;
BA_ "CANFD_BRS" BO_ 1955 1;
BA_ "GenMsgSendType" BO_ 1955 8;
BA_ "GenMsgDelayTime" BO_ 1955 10;
BA_ "VFrameFormat" BO_ 1955 14;
BA_ "CANFD_BRS" BO_ 1954 1;
BA_ "VFrameFormat" BO_ 1954 14;
BA_ "CANFD_BRS" BO_ 1953 1;
BA_ "VFrameFormat" BO_ 1953 14;
BA_ "DiagConnection" BO_ 2671964754 62034;
BA_ "DiagUUDTResponse" BO_ 2671964754 1;
BA_ "GenMsgILSupport" BO_ 2671964754 0;
BA_ "GenMsgSendType" BO_ 2671964754 8;
BA_ "DiagConnection" BO_ 2671834194 62546;
BA_ "DiagResponse" BO_ 2671834194 1;
BA_ "GenMsgILSupport" BO_ 2671834194 0;
BA_ "GenMsgSendType" BO_ 2671834194 8;
BA_ "DiagConnection" BO_ 2671833938 62290;
BA_ "DiagResponse" BO_ 2671833938 1;
BA_ "GenMsgILSupport" BO_ 2671833938 0;
BA_ "GenMsgSendType" BO_ 2671833938 8;
BA_ "DiagConnection" BO_ 2671792884 62546;
BA_ "DiagRequest" BO_ 2671792884 1;
BA_ "GenMsgILSupport" BO_ 2671792884 0;
BA_ "GenMsgSendType" BO_ 2671792884 8;
BA_ "DiagConnection" BO_ 2671792883 62290;
BA_ "DiagRequest" BO_ 2671792883 1;
BA_ "GenMsgILSupport" BO_ 2671792883 0;
BA_ "GenMsgSendType" BO_ 2671792883 8;
BA_ "CANFD_BRS" BO_ 1527 1;
BA_ "GenMsgCycleTime" BO_ 1527 1000;
BA_ "GenMsgDelayTime" BO_ 1527 80;
BA_ "VFrameFormat" BO_ 1527 14;
BA_ "CANFD_BRS" BO_ 257 1;
BA_ "GenMsgSendType" BO_ 257 8;
BA_ "VFrameFormat" BO_ 257 14;
BA_ "CANFD_BRS" BO_ 761 1;
BA_ "GenMsgSendType" BO_ 761 8;
BA_ "VFrameFormat" BO_ 761 14;
BA_ "CANFD_BRS" BO_ 760 1;
BA_ "GenMsgSendType" BO_ 760 8;
BA_ "VFrameFormat" BO_ 760 14;
BA_ "CANFD_BRS" BO_ 279 1;
BA_ "GenMsgCycleTime" BO_ 279 20;
BA_ "GenMsgStartDelayTime" BO_ 279 15;
BA_ "VFrameFormat" BO_ 279 14;
BA_ "CANFD_BRS" BO_ 275 1;
BA_ "GenMsgSendType" BO_ 275 8;
BA_ "VFrameFormat" BO_ 275 14;
BA_ "CANFD_BRS" BO_ 277 1;
BA_ "GenMsgSendType" BO_ 277 8;
BA_ "GenMsgStartDelayTime" BO_ 277 5;
BA_ "VFrameFormat" BO_ 277 14;
BA_ "CANFD_BRS" BO_ 1976 1;
BA_ "GenMsgSendType" BO_ 1976 8;
BA_ "GenMsgDelayTime" BO_ 1976 10;
BA_ "VFrameFormat" BO_ 1976 14;
BA_ "CANFD_BRS" BO_ 1975 1;
BA_ "GenMsgSendType" BO_ 1975 8;
BA_ "GenMsgDelayTime" BO_ 1975 10;
BA_ "VFrameFormat" BO_ 1975 14;
BA_ "CANFD_BRS" BO_ 1974 1;
BA_ "GenMsgSendType" BO_ 1974 8;
BA_ "GenMsgDelayTime" BO_ 1974 10;
BA_ "VFrameFormat" BO_ 1974 14;
BA_ "CANFD_BRS" BO_ 1973 1;
BA_ "GenMsgSendType" BO_ 1973 8;
BA_ "GenMsgDelayTime" BO_ 1973 10;
BA_ "VFrameFormat" BO_ 1973 14;
BA_ "CANFD_BRS" BO_ 1972 1;
BA_ "GenMsgSendType" BO_ 1972 8;
BA_ "GenMsgDelayTime" BO_ 1972 10;
BA_ "VFrameFormat" BO_ 1972 14;
BA_ "CANFD_BRS" BO_ 1971 1;
BA_ "GenMsgSendType" BO_ 1971 8;
BA_ "GenMsgDelayTime" BO_ 1971 10;
BA_ "VFrameFormat" BO_ 1971 14;
BA_ "CANFD_BRS" BO_ 1970 1;
BA_ "GenMsgSendType" BO_ 1970 8;
BA_ "GenMsgDelayTime" BO_ 1970 10;
BA_ "VFrameFormat" BO_ 1970 14;
BA_ "CANFD_BRS" BO_ 1969 1;
BA_ "GenMsgSendType" BO_ 1969 8;
BA_ "GenMsgDelayTime" BO_ 1969 10;
BA_ "VFrameFormat" BO_ 1969 14;
BA_ "CANFD_BRS" BO_ 333 1;
BA_ "GenMsgCycleTime" BO_ 333 10;
BA_ "GenMsgStartDelayTime" BO_ 333 5;
BA_ "VFrameFormat" BO_ 333 14;
BA_ "CANFD_BRS" BO_ 1077 1;
BA_ "GenMsgCycleTime" BO_ 1077 50;
BA_ "GenMsgStartDelayTime" BO_ 1077 10;
BA_ "VFrameFormat" BO_ 1077 14;
BA_ "CANFD_BRS" BO_ 1543 1;
BA_ "GenMsgCycleTime" BO_ 1543 5000;
BA_ "GenMsgStartDelayTime" BO_ 1543 115;
BA_ "VFrameFormat" BO_ 1543 14;
BA_ "CANFD_BRS" BO_ 1265 1;
BA_ "GenMsgCycleTime" BO_ 1265 250;
BA_ "GenMsgStartDelayTime" BO_ 1265 30;
BA_ "VFrameFormat" BO_ 1265 14;
BA_ "CANFD_BRS" BO_ 1552 1;
BA_ "GenMsgCycleTime" BO_ 1552 10000;
BA_ "GenMsgStartDelayTime" BO_ 1552 220;
BA_ "VFrameFormat" BO_ 1552 14;
BA_ "GenSigSendType" SG_ 786 FLRObj03_ObjClass 1;
BA_ "GenSigStartValue" SG_ 786 FLRObj03_ObjClass 15;
BA_ "GenSigSendType" SG_ 786 FLRObj03_LongAccVar 1;
BA_ "GenSigStartValue" SG_ 786 FLRObj03_LongAccVar 255;
BA_ "GenSigSendType" SG_ 786 FLRObj03_LifeTime 1;
BA_ "GenSigStartValue" SG_ 786 FLRObj03_LifeTime 65535;
BA_ "GenSigSendType" SG_ 786 FLRObj03_LatExtLeft 1;
BA_ "GenSigStartValue" SG_ 786 FLRObj03_LatExtLeft 127;
BA_ "GenSigSendType" SG_ 786 FLRObj03_ObjDynClass 1;
BA_ "GenSigStartValue" SG_ 786 FLRObj03_ObjDynClass 3;
BA_ "GenSigSendType" SG_ 786 FLRObj03_LongVel 1;
BA_ "GenSigStartValue" SG_ 786 FLRObj03_LongVel 8191;
BA_ "GenSigSendType" SG_ 786 FLRObj03_ObstacleConf 1;
BA_ "GenSigStartValue" SG_ 786 FLRObj03_ObstacleConf 127;
BA_ "GenSigSendType" SG_ 786 FLRObj03_LatExtRight 1;
BA_ "GenSigStartValue" SG_ 786 FLRObj03_LatExtRight 127;
BA_ "GenSigSendType" SG_ 786 FLRObj03_CRC 1;
BA_ "GenSigStartValue" SG_ 786 FLRObj03_CRC 65535;
BA_ "E2EDataId" SG_ 786 FLRObj03_CRC 94;
BA_ "E2EDataLength" SG_ 786 FLRObj03_CRC 320;
BA_ "E2EProfile" SG_ 786 FLRObj03_CRC "P05";
BA_ "GenSigSendType" SG_ 786 FLRObj03_Height 1;
BA_ "GenSigStartValue" SG_ 786 FLRObj03_Height 15;
BA_ "GenSigSendType" SG_ 786 FLRObj03_LatExtRtVar 1;
BA_ "GenSigStartValue" SG_ 786 FLRObj03_LatExtRtVar 255;
BA_ "GenSigSendType" SG_ 786 FLRObj03_AsilLvl 1;
BA_ "GenSigStartValue" SG_ 786 FLRObj03_AsilLvl 3;
BA_ "GenSigSendType" SG_ 786 FLRObj03_TimeStamp 1;
BA_ "GenSigStartValue" SG_ 786 FLRObj03_TimeStamp 65535;
BA_ "GenSigSendType" SG_ 786 FLRObj03_ExistConf 1;
BA_ "GenSigStartValue" SG_ 786 FLRObj03_ExistConf 127;
BA_ "GenSigSendType" SG_ 786 FLRObj03_LatExtLeftVar 1;
BA_ "GenSigStartValue" SG_ 786 FLRObj03_LatExtLeftVar 255;
BA_ "GenSigSendType" SG_ 786 FLRObj03_ObstacleConfRestricted 1;
BA_ "GenSigStartValue" SG_ 786 FLRObj03_ObstacleConfRestricted 127;
BA_ "GenSigSendType" SG_ 786 FLRObj03_Heading 1;
BA_ "GenSigStartValue" SG_ 786 FLRObj03_Heading 2047;
BA_ "GenSigSendType" SG_ 786 FLRObj03_LatPosVar 1;
BA_ "GenSigStartValue" SG_ 786 FLRObj03_LatPosVar 255;
BA_ "GenSigSendType" SG_ 786 FLRObj03_LatPos 1;
BA_ "GenSigStartValue" SG_ 786 FLRObj03_LatPos 8191;
BA_ "GenSigSendType" SG_ 786 FLRObj03_LongExtBkVar 1;
BA_ "GenSigStartValue" SG_ 786 FLRObj03_LongExtBkVar 255;
BA_ "GenSigSendType" SG_ 786 FLRObj03_CoastIndex 1;
BA_ "GenSigStartValue" SG_ 786 FLRObj03_CoastIndex 31;
BA_ "GenSigSendType" SG_ 786 FLRObj03_LatAccVar 1;
BA_ "GenSigStartValue" SG_ 786 FLRObj03_LatAccVar 255;
BA_ "GenSigSendType" SG_ 786 FLRObj03_LongAcc 1;
BA_ "GenSigStartValue" SG_ 786 FLRObj03_LongAcc 511;
BA_ "GenSigSendType" SG_ 786 FLRObj03_ObjDynClassRestricted 1;
BA_ "GenSigStartValue" SG_ 786 FLRObj03_ObjDynClassRestricted 3;
BA_ "GenSigSendType" SG_ 786 FLRObj03_ObjClassConf 1;
BA_ "GenSigStartValue" SG_ 786 FLRObj03_ObjClassConf 127;
BA_ "GenSigSendType" SG_ 786 FLRObj03_LatVel 1;
BA_ "GenSigStartValue" SG_ 786 FLRObj03_LatVel 8191;
BA_ "GenSigSendType" SG_ 786 FLRObj03_LongExtFront 1;
BA_ "GenSigStartValue" SG_ 786 FLRObj03_LongExtFront 1023;
BA_ "GenSigSendType" SG_ 786 FLRObj03_LongVelVar 1;
BA_ "GenSigStartValue" SG_ 786 FLRObj03_LongVelVar 255;
BA_ "GenSigSendType" SG_ 786 FLRObj03_LatVelVar 1;
BA_ "GenSigStartValue" SG_ 786 FLRObj03_LatVelVar 255;
BA_ "GenSigSendType" SG_ 786 FLRObj03_LongExtBack 1;
BA_ "GenSigStartValue" SG_ 786 FLRObj03_LongExtBack 1023;
BA_ "GenSigSendType" SG_ 786 FLRObj03_LongPos 1;
BA_ "GenSigStartValue" SG_ 786 FLRObj03_LongPos 8191;
BA_ "GenSigSendType" SG_ 786 FLRObj03_HeadingVar 1;
BA_ "GenSigStartValue" SG_ 786 FLRObj03_HeadingVar 255;
BA_ "GenSigSendType" SG_ 786 FLRObj03_LongPosVar 1;
BA_ "GenSigStartValue" SG_ 786 FLRObj03_LongPosVar 255;
BA_ "GenSigSendType" SG_ 786 FLRObj03_ObjID 1;
BA_ "GenSigStartValue" SG_ 786 FLRObj03_ObjID 63;
BA_ "GenSigSendType" SG_ 786 FLRObj03_LongExtFrVar 1;
BA_ "GenSigStartValue" SG_ 786 FLRObj03_LongExtFrVar 255;
BA_ "GenSigSendType" SG_ 786 FLRObj03_LatAcc 1;
BA_ "GenSigStartValue" SG_ 786 FLRObj03_LatAcc 511;
BA_ "GenSigSendType" SG_ 786 FLRObj03_Counter 1;
BA_ "GenSigStartValue" SG_ 786 FLRObj03_Counter 255;
BA_ "GenSigSendType" SG_ 786 FLRObj03_TrackStatus 1;
BA_ "GenSigStartValue" SG_ 786 FLRObj03_TrackStatus 7;
BA_ "GenSigSendType" SG_ 785 FLRObj02_CoastIndex 1;
BA_ "GenSigStartValue" SG_ 785 FLRObj02_CoastIndex 31;
BA_ "GenSigSendType" SG_ 785 FLRObj02_LongExtBack 1;
BA_ "GenSigStartValue" SG_ 785 FLRObj02_LongExtBack 1023;
BA_ "GenSigSendType" SG_ 785 FLRObj02_ObstacleConfRestricted 1;
BA_ "GenSigStartValue" SG_ 785 FLRObj02_ObstacleConfRestricted 127;
BA_ "GenSigSendType" SG_ 785 FLRObj02_LatVel 1;
BA_ "GenSigStartValue" SG_ 785 FLRObj02_LatVel 8191;
BA_ "GenSigSendType" SG_ 785 FLRObj02_ObstacleConf 1;
BA_ "GenSigStartValue" SG_ 785 FLRObj02_ObstacleConf 127;
BA_ "GenSigSendType" SG_ 785 FLRObj02_AsilLvl 1;
BA_ "GenSigStartValue" SG_ 785 FLRObj02_AsilLvl 3;
BA_ "GenSigSendType" SG_ 785 FLRObj02_LatExtLeft 1;
BA_ "GenSigStartValue" SG_ 785 FLRObj02_LatExtLeft 127;
BA_ "GenSigSendType" SG_ 785 FLRObj02_CRC 1;
BA_ "GenSigStartValue" SG_ 785 FLRObj02_CRC 65535;
BA_ "E2EDataId" SG_ 785 FLRObj02_CRC 93;
BA_ "E2EDataLength" SG_ 785 FLRObj02_CRC 320;
BA_ "E2EProfile" SG_ 785 FLRObj02_CRC "P05";
BA_ "GenSigSendType" SG_ 785 FLRObj02_LongVelVar 1;
BA_ "GenSigStartValue" SG_ 785 FLRObj02_LongVelVar 255;
BA_ "GenSigSendType" SG_ 785 FLRObj02_Counter 1;
BA_ "GenSigStartValue" SG_ 785 FLRObj02_Counter 255;
BA_ "GenSigSendType" SG_ 785 FLRObj02_LongPos 1;
BA_ "GenSigStartValue" SG_ 785 FLRObj02_LongPos 8191;
BA_ "GenSigSendType" SG_ 785 FLRObj02_LatExtLeftVar 1;
BA_ "GenSigStartValue" SG_ 785 FLRObj02_LatExtLeftVar 255;
BA_ "GenSigSendType" SG_ 785 FLRObj02_LongExtBkVar 1;
BA_ "GenSigStartValue" SG_ 785 FLRObj02_LongExtBkVar 255;
BA_ "GenSigSendType" SG_ 785 FLRObj02_LongVel 1;
BA_ "GenSigStartValue" SG_ 785 FLRObj02_LongVel 8191;
BA_ "GenSigSendType" SG_ 785 FLRObj02_ObjDynClassRestricted 1;
BA_ "GenSigStartValue" SG_ 785 FLRObj02_ObjDynClassRestricted 3;
BA_ "GenSigSendType" SG_ 785 FLRObj02_LongExtFront 1;
BA_ "GenSigStartValue" SG_ 785 FLRObj02_LongExtFront 1023;
BA_ "GenSigSendType" SG_ 785 FLRObj02_LongAccVar 1;
BA_ "GenSigStartValue" SG_ 785 FLRObj02_LongAccVar 255;
BA_ "GenSigSendType" SG_ 785 FLRObj02_LatAccVar 1;
BA_ "GenSigStartValue" SG_ 785 FLRObj02_LatAccVar 255;
BA_ "GenSigSendType" SG_ 785 FLRObj02_LongPosVar 1;
BA_ "GenSigStartValue" SG_ 785 FLRObj02_LongPosVar 255;
BA_ "GenSigSendType" SG_ 785 FLRObj02_LatExtRtVar 1;
BA_ "GenSigStartValue" SG_ 785 FLRObj02_LatExtRtVar 255;
BA_ "GenSigSendType" SG_ 785 FLRObj02_LatPos 1;
BA_ "GenSigStartValue" SG_ 785 FLRObj02_LatPos 8191;
BA_ "GenSigSendType" SG_ 785 FLRObj02_ExistConf 1;
BA_ "GenSigStartValue" SG_ 785 FLRObj02_ExistConf 127;
BA_ "GenSigSendType" SG_ 785 FLRObj02_LongExtFrVar 1;
BA_ "GenSigStartValue" SG_ 785 FLRObj02_LongExtFrVar 255;
BA_ "GenSigSendType" SG_ 785 FLRObj02_ObjClass 1;
BA_ "GenSigStartValue" SG_ 785 FLRObj02_ObjClass 15;
BA_ "GenSigSendType" SG_ 785 FLRObj02_Heading 1;
BA_ "GenSigStartValue" SG_ 785 FLRObj02_Heading 2047;
BA_ "GenSigSendType" SG_ 785 FLRObj02_TimeStamp 1;
BA_ "GenSigStartValue" SG_ 785 FLRObj02_TimeStamp 65535;
BA_ "GenSigSendType" SG_ 785 FLRObj02_ObjClassConf 1;
BA_ "GenSigStartValue" SG_ 785 FLRObj02_ObjClassConf 127;
BA_ "GenSigSendType" SG_ 785 FLRObj02_Height 1;
BA_ "GenSigStartValue" SG_ 785 FLRObj02_Height 15;
BA_ "GenSigSendType" SG_ 785 FLRObj02_LifeTime 1;
BA_ "GenSigStartValue" SG_ 785 FLRObj02_LifeTime 65535;
BA_ "GenSigSendType" SG_ 785 FLRObj02_TrackStatus 1;
BA_ "GenSigStartValue" SG_ 785 FLRObj02_TrackStatus 7;
BA_ "GenSigSendType" SG_ 785 FLRObj02_LatAcc 1;
BA_ "GenSigStartValue" SG_ 785 FLRObj02_LatAcc 511;
BA_ "GenSigSendType" SG_ 785 FLRObj02_LatVelVar 1;
BA_ "GenSigStartValue" SG_ 785 FLRObj02_LatVelVar 255;
BA_ "GenSigSendType" SG_ 785 FLRObj02_ObjDynClass 1;
BA_ "GenSigStartValue" SG_ 785 FLRObj02_ObjDynClass 3;
BA_ "GenSigSendType" SG_ 785 FLRObj02_ObjID 1;
BA_ "GenSigStartValue" SG_ 785 FLRObj02_ObjID 63;
BA_ "GenSigSendType" SG_ 785 FLRObj02_LatExtRight 1;
BA_ "GenSigStartValue" SG_ 785 FLRObj02_LatExtRight 127;
BA_ "GenSigSendType" SG_ 785 FLRObj02_LatPosVar 1;
BA_ "GenSigStartValue" SG_ 785 FLRObj02_LatPosVar 255;
BA_ "GenSigSendType" SG_ 785 FLRObj02_HeadingVar 1;
BA_ "GenSigStartValue" SG_ 785 FLRObj02_HeadingVar 255;
BA_ "GenSigSendType" SG_ 785 FLRObj02_LongAcc 1;
BA_ "GenSigStartValue" SG_ 785 FLRObj02_LongAcc 511;
BA_ "GenSigSendType" SG_ 784 FLRObj01_LatPos 1;
BA_ "GenSigStartValue" SG_ 784 FLRObj01_LatPos 8191;
BA_ "GenSigSendType" SG_ 784 FLRObj01_LifeTime 1;
BA_ "GenSigStartValue" SG_ 784 FLRObj01_LifeTime 65535;
BA_ "GenSigSendType" SG_ 784 FLRObj01_LongExtBack 1;
BA_ "GenSigStartValue" SG_ 784 FLRObj01_LongExtBack 1023;
BA_ "GenSigSendType" SG_ 784 FLRObj01_TimeStamp 1;
BA_ "GenSigStartValue" SG_ 784 FLRObj01_TimeStamp 65535;
BA_ "GenSigSendType" SG_ 784 FLRObj01_LongVelVar 1;
BA_ "GenSigStartValue" SG_ 784 FLRObj01_LongVelVar 255;
BA_ "GenSigSendType" SG_ 784 FLRObj01_LatExtRight 1;
BA_ "GenSigStartValue" SG_ 784 FLRObj01_LatExtRight 127;
BA_ "GenSigSendType" SG_ 784 FLRObj01_ObstacleConfRestricted 1;
BA_ "GenSigStartValue" SG_ 784 FLRObj01_ObstacleConfRestricted 127;
BA_ "GenSigSendType" SG_ 784 FLRObj01_ObjID 1;
BA_ "GenSigStartValue" SG_ 784 FLRObj01_ObjID 63;
BA_ "GenSigSendType" SG_ 784 FLRObj01_Counter 1;
BA_ "GenSigStartValue" SG_ 784 FLRObj01_Counter 255;
BA_ "GenSigSendType" SG_ 784 FLRObj01_LongExtBkVar 1;
BA_ "GenSigStartValue" SG_ 784 FLRObj01_LongExtBkVar 255;
BA_ "GenSigSendType" SG_ 784 FLRObj01_CRC 1;
BA_ "GenSigStartValue" SG_ 784 FLRObj01_CRC 65535;
BA_ "E2EDataId" SG_ 784 FLRObj01_CRC 92;
BA_ "E2EDataLength" SG_ 784 FLRObj01_CRC 320;
BA_ "E2EProfile" SG_ 784 FLRObj01_CRC "P05";
BA_ "GenSigSendType" SG_ 784 FLRObj01_AsilLvl 1;
BA_ "GenSigStartValue" SG_ 784 FLRObj01_AsilLvl 3;
BA_ "GenSigSendType" SG_ 784 FLRObj01_HeadingVar 1;
BA_ "GenSigStartValue" SG_ 784 FLRObj01_HeadingVar 255;
BA_ "GenSigSendType" SG_ 784 FLRObj01_Heading 1;
BA_ "GenSigStartValue" SG_ 784 FLRObj01_Heading 2047;
BA_ "GenSigSendType" SG_ 784 FLRObj01_ObjClass 1;
BA_ "GenSigStartValue" SG_ 784 FLRObj01_ObjClass 15;
BA_ "GenSigSendType" SG_ 784 FLRObj01_LatVelVar 1;
BA_ "GenSigStartValue" SG_ 784 FLRObj01_LatVelVar 255;
BA_ "GenSigSendType" SG_ 784 FLRObj01_LongPos 1;
BA_ "GenSigStartValue" SG_ 784 FLRObj01_LongPos 8191;
BA_ "GenSigSendType" SG_ 784 FLRObj01_LongAcc 1;
BA_ "GenSigStartValue" SG_ 784 FLRObj01_LongAcc 511;
BA_ "GenSigSendType" SG_ 784 FLRObj01_LongPosVar 1;
BA_ "GenSigStartValue" SG_ 784 FLRObj01_LongPosVar 255;
BA_ "GenSigSendType" SG_ 784 FLRObj01_ObjClassConf 1;
BA_ "GenSigStartValue" SG_ 784 FLRObj01_ObjClassConf 127;
BA_ "GenSigSendType" SG_ 784 FLRObj01_LatExtLeftVar 1;
BA_ "GenSigStartValue" SG_ 784 FLRObj01_LatExtLeftVar 255;
BA_ "GenSigSendType" SG_ 784 FLRObj01_LatAccVar 1;
BA_ "GenSigStartValue" SG_ 784 FLRObj01_LatAccVar 255;
BA_ "GenSigSendType" SG_ 784 FLRObj01_ObjDynClassRestricted 1;
BA_ "GenSigStartValue" SG_ 784 FLRObj01_ObjDynClassRestricted 3;
BA_ "GenSigSendType" SG_ 784 FLRObj01_ExistConf 1;
BA_ "GenSigStartValue" SG_ 784 FLRObj01_ExistConf 127;
BA_ "GenSigSendType" SG_ 784 FLRObj01_LatAcc 1;
BA_ "GenSigStartValue" SG_ 784 FLRObj01_LatAcc 511;
BA_ "GenSigSendType" SG_ 784 FLRObj01_LongVel 1;
BA_ "GenSigStartValue" SG_ 784 FLRObj01_LongVel 8191;
BA_ "GenSigSendType" SG_ 784 FLRObj01_CoastIndex 1;
BA_ "GenSigStartValue" SG_ 784 FLRObj01_CoastIndex 31;
BA_ "GenSigSendType" SG_ 784 FLRObj01_LongExtFrVar 1;
BA_ "GenSigStartValue" SG_ 784 FLRObj01_LongExtFrVar 255;
BA_ "GenSigSendType" SG_ 784 FLRObj01_LatExtRtVar 1;
BA_ "GenSigStartValue" SG_ 784 FLRObj01_LatExtRtVar 255;
BA_ "GenSigSendType" SG_ 784 FLRObj01_LongExtFront 1;
BA_ "GenSigStartValue" SG_ 784 FLRObj01_LongExtFront 1023;
BA_ "GenSigSendType" SG_ 784 FLRObj01_LatPosVar 1;
BA_ "GenSigStartValue" SG_ 784 FLRObj01_LatPosVar 255;
BA_ "GenSigSendType" SG_ 784 FLRObj01_TrackStatus 1;
BA_ "GenSigStartValue" SG_ 784 FLRObj01_TrackStatus 7;
BA_ "GenSigSendType" SG_ 784 FLRObj01_LatExtLeft 1;
BA_ "GenSigStartValue" SG_ 784 FLRObj01_LatExtLeft 127;
BA_ "GenSigSendType" SG_ 784 FLRObj01_ObstacleConf 1;
BA_ "GenSigStartValue" SG_ 784 FLRObj01_ObstacleConf 127;
BA_ "GenSigSendType" SG_ 784 FLRObj01_ObjDynClass 1;
BA_ "GenSigStartValue" SG_ 784 FLRObj01_ObjDynClass 3;
BA_ "GenSigSendType" SG_ 784 FLRObj01_LatVel 1;
BA_ "GenSigStartValue" SG_ 784 FLRObj01_LatVel 8191;
BA_ "GenSigSendType" SG_ 784 FLRObj01_Height 1;
BA_ "GenSigStartValue" SG_ 784 FLRObj01_Height 15;
BA_ "GenSigSendType" SG_ 784 FLRObj01_LongAccVar 1;
BA_ "GenSigStartValue" SG_ 784 FLRObj01_LongAccVar 255;
BA_ "GenSigSendType" SG_ 783 FLRObj00_LongVelVar 1;
BA_ "GenSigStartValue" SG_ 783 FLRObj00_LongVelVar 255;
BA_ "GenSigSendType" SG_ 783 FLRObj00_LongPos 1;
BA_ "GenSigStartValue" SG_ 783 FLRObj00_LongPos 8191;
BA_ "GenSigSendType" SG_ 783 FLRObj00_LongExtBack 1;
BA_ "GenSigStartValue" SG_ 783 FLRObj00_LongExtBack 1023;
BA_ "GenSigSendType" SG_ 783 FLRObj00_LatPosVar 1;
BA_ "GenSigStartValue" SG_ 783 FLRObj00_LatPosVar 255;
BA_ "GenSigSendType" SG_ 783 FLRObj00_LongExtFront 1;
BA_ "GenSigStartValue" SG_ 783 FLRObj00_LongExtFront 1023;
BA_ "GenSigSendType" SG_ 783 FLRObj00_AsilLvl 1;
BA_ "GenSigStartValue" SG_ 783 FLRObj00_AsilLvl 3;
BA_ "GenSigSendType" SG_ 783 FLRObj00_LatExtLeft 1;
BA_ "GenSigStartValue" SG_ 783 FLRObj00_LatExtLeft 127;
BA_ "GenSigSendType" SG_ 783 FLRObj00_LongAccVar 1;
BA_ "GenSigStartValue" SG_ 783 FLRObj00_LongAccVar 255;
BA_ "GenSigSendType" SG_ 783 FLRObj00_LifeTime 1;
BA_ "GenSigStartValue" SG_ 783 FLRObj00_LifeTime 65535;
BA_ "GenSigSendType" SG_ 783 FLRObj00_LatExtRight 1;
BA_ "GenSigStartValue" SG_ 783 FLRObj00_LatExtRight 127;
BA_ "GenSigSendType" SG_ 783 FLRObj00_ObjDynClass 1;
BA_ "GenSigStartValue" SG_ 783 FLRObj00_ObjDynClass 3;
BA_ "GenSigSendType" SG_ 783 FLRObj00_LatAcc 1;
BA_ "GenSigStartValue" SG_ 783 FLRObj00_LatAcc 511;
BA_ "GenSigSendType" SG_ 783 FLRObj00_Height 1;
BA_ "GenSigStartValue" SG_ 783 FLRObj00_Height 15;
BA_ "GenSigSendType" SG_ 783 FLRObj00_LongExtFrVar 1;
BA_ "GenSigStartValue" SG_ 783 FLRObj00_LongExtFrVar 255;
BA_ "GenSigSendType" SG_ 783 FLRObj00_LatPos 1;
BA_ "GenSigStartValue" SG_ 783 FLRObj00_LatPos 8191;
BA_ "GenSigSendType" SG_ 783 FLRObj00_LongVel 1;
BA_ "GenSigStartValue" SG_ 783 FLRObj00_LongVel 8191;
BA_ "GenSigSendType" SG_ 783 FLRObj00_ObjClassConf 1;
BA_ "GenSigStartValue" SG_ 783 FLRObj00_ObjClassConf 127;
BA_ "GenSigSendType" SG_ 783 FLRObj00_ObjID 1;
BA_ "GenSigStartValue" SG_ 783 FLRObj00_ObjID 63;
BA_ "GenSigSendType" SG_ 783 FLRObj00_LongPosVar 1;
BA_ "GenSigStartValue" SG_ 783 FLRObj00_LongPosVar 255;
BA_ "GenSigSendType" SG_ 783 FLRObj00_TimeStamp 1;
BA_ "GenSigStartValue" SG_ 783 FLRObj00_TimeStamp 65535;
BA_ "GenSigSendType" SG_ 783 FLRObj00_ObstacleConf 1;
BA_ "GenSigStartValue" SG_ 783 FLRObj00_ObstacleConf 127;
BA_ "GenSigSendType" SG_ 783 FLRObj00_ObjClass 1;
BA_ "GenSigStartValue" SG_ 783 FLRObj00_ObjClass 15;
BA_ "GenSigSendType" SG_ 783 FLRObj00_LongExtBkVar 1;
BA_ "GenSigStartValue" SG_ 783 FLRObj00_LongExtBkVar 255;
BA_ "GenSigSendType" SG_ 783 FLRObj00_ExistConf 1;
BA_ "GenSigStartValue" SG_ 783 FLRObj00_ExistConf 127;
BA_ "GenSigSendType" SG_ 783 FLRObj00_LatVelVar 1;
BA_ "GenSigStartValue" SG_ 783 FLRObj00_LatVelVar 255;
BA_ "GenSigSendType" SG_ 783 FLRObj00_CoastIndex 1;
BA_ "GenSigStartValue" SG_ 783 FLRObj00_CoastIndex 31;
BA_ "GenSigSendType" SG_ 783 FLRObj00_ObstacleConfRestricted 1;
BA_ "GenSigStartValue" SG_ 783 FLRObj00_ObstacleConfRestricted 127;
BA_ "GenSigSendType" SG_ 783 FLRObj00_TrackStatus 1;
BA_ "GenSigStartValue" SG_ 783 FLRObj00_TrackStatus 7;
BA_ "GenSigSendType" SG_ 783 FLRObj00_LatVel 1;
BA_ "GenSigStartValue" SG_ 783 FLRObj00_LatVel 8191;
BA_ "GenSigSendType" SG_ 783 FLRObj00_LongAcc 1;
BA_ "GenSigStartValue" SG_ 783 FLRObj00_LongAcc 511;
BA_ "GenSigSendType" SG_ 783 FLRObj00_CRC 1;
BA_ "GenSigStartValue" SG_ 783 FLRObj00_CRC 65535;
BA_ "E2EDataId" SG_ 783 FLRObj00_CRC 91;
BA_ "E2EDataLength" SG_ 783 FLRObj00_CRC 320;
BA_ "E2EProfile" SG_ 783 FLRObj00_CRC "P05";
BA_ "GenSigSendType" SG_ 783 FLRObj00_Heading 1;
BA_ "GenSigStartValue" SG_ 783 FLRObj00_Heading 2047;
BA_ "GenSigSendType" SG_ 783 FLRObj00_ObjDynClassRestricted 1;
BA_ "GenSigStartValue" SG_ 783 FLRObj00_ObjDynClassRestricted 3;
BA_ "GenSigSendType" SG_ 783 FLRObj00_HeadingVar 1;
BA_ "GenSigStartValue" SG_ 783 FLRObj00_HeadingVar 255;
BA_ "GenSigSendType" SG_ 783 FLRObj00_LatAccVar 1;
BA_ "GenSigStartValue" SG_ 783 FLRObj00_LatAccVar 255;
BA_ "GenSigSendType" SG_ 783 FLRObj00_LatExtRtVar 1;
BA_ "GenSigStartValue" SG_ 783 FLRObj00_LatExtRtVar 255;
BA_ "GenSigSendType" SG_ 783 FLRObj00_LatExtLeftVar 1;
BA_ "GenSigStartValue" SG_ 783 FLRObj00_LatExtLeftVar 255;
BA_ "GenSigSendType" SG_ 783 FLRObj00_Counter 1;
BA_ "GenSigStartValue" SG_ 783 FLRObj00_Counter 255;
BA_ "GenSigSendType" SG_ 860 LeftRoadBoundary_CoastIndex 1;
BA_ "GenSigStartValue" SG_ 860 LeftRoadBoundary_CoastIndex 31;
BA_ "GenSigSendType" SG_ 860 LeftRoadBoundary_DxStart 1;
BA_ "GenSigStartValue" SG_ 860 LeftRoadBoundary_DxStart 255;
BA_ "GenSigSendType" SG_ 860 LeftRoadBoundary_LifeTime 1;
BA_ "GenSigStartValue" SG_ 860 LeftRoadBoundary_LifeTime 65535;
BA_ "GenSigSendType" SG_ 860 LeftRoadBoundary_TimeStamp 1;
BA_ "GenSigStartValue" SG_ 860 LeftRoadBoundary_TimeStamp 65535;
BA_ "GenSigSendType" SG_ 860 LeftRoadBoundary_HeadingAngle 1;
BA_ "GenSigStartValue" SG_ 860 LeftRoadBoundary_HeadingAngle 8191;
BA_ "GenSigSendType" SG_ 860 LeftRoadBoundary_Curvature 1;
BA_ "GenSigStartValue" SG_ 860 LeftRoadBoundary_Curvature 262143;
BA_ "GenSigSendType" SG_ 860 LeftRoadBoundary_CRC 1;
BA_ "GenSigStartValue" SG_ 860 LeftRoadBoundary_CRC 65535;
BA_ "E2EDataId" SG_ 860 LeftRoadBoundary_CRC 110;
BA_ "E2EDataLength" SG_ 860 LeftRoadBoundary_CRC 152;
BA_ "E2EProfile" SG_ 860 LeftRoadBoundary_CRC "P05";
BA_ "GenSigSendType" SG_ 860 LeftRoadBoundary_CurvatureRate 1;
BA_ "GenSigStartValue" SG_ 860 LeftRoadBoundary_CurvatureRate 2047;
BA_ "GenSigSendType" SG_ 860 LeftRoadBoundary_Type 1;
BA_ "GenSigStartValue" SG_ 860 LeftRoadBoundary_Type 7;
BA_ "GenSigSendType" SG_ 860 LeftRoadBoundary_LatDistVar 1;
BA_ "GenSigStartValue" SG_ 860 LeftRoadBoundary_LatDistVar 255;
BA_ "GenSigSendType" SG_ 860 LeftRoadBoundary_TrackStatus 1;
BA_ "GenSigStartValue" SG_ 860 LeftRoadBoundary_TrackStatus 7;
BA_ "GenSigSendType" SG_ 860 LeftRoadBoundary_Counter 1;
BA_ "GenSigStartValue" SG_ 860 LeftRoadBoundary_Counter 255;
BA_ "GenSigSendType" SG_ 860 LeftRoadBoundary_LatDist 1;
BA_ "GenSigStartValue" SG_ 860 LeftRoadBoundary_LatDist 4095;
BA_ "GenSigSendType" SG_ 860 LeftRoadBoundary_Confidence 1;
BA_ "GenSigStartValue" SG_ 860 LeftRoadBoundary_Confidence 127;
BA_ "GenSigSendType" SG_ 860 LeftRoadBoundary_DxEnd 1;
BA_ "GenSigStartValue" SG_ 860 LeftRoadBoundary_DxEnd 255;
BA_ "GenSigSendType" SG_ 858 FLREgoAssumpt_EgoRoadEnd 1;
BA_ "GenSigStartValue" SG_ 858 FLREgoAssumpt_EgoRoadEnd 255;
BA_ "GenSigSendType" SG_ 858 FLREgoAssumpt_EgoLongAcc 1;
BA_ "GenSigStartValue" SG_ 858 FLREgoAssumpt_EgoLongAcc 65535;
BA_ "GenSigSendType" SG_ 858 FLREgoAssumpt_VelCorrFactor 1;
BA_ "GenSigStartValue" SG_ 858 FLREgoAssumpt_VelCorrFactor 255;
BA_ "GenSigSendType" SG_ 858 FLREgoAssumpt_EgoRoadCurvRate 1;
BA_ "GenSigStartValue" SG_ 858 FLREgoAssumpt_EgoRoadCurvRate 2047;
BA_ "GenSigSendType" SG_ 858 FLREgoAssumpt_TimeStamp 1;
BA_ "GenSigStartValue" SG_ 858 FLREgoAssumpt_TimeStamp 65535;
BA_ "GenSigSendType" SG_ 858 FLREgoAssumpt_EgoYawRate 1;
BA_ "GenSigStartValue" SG_ 858 FLREgoAssumpt_EgoYawRate 65535;
BA_ "GenSigSendType" SG_ 858 FLREgoAssumpt_EgoRoadHeading 1;
BA_ "GenSigStartValue" SG_ 858 FLREgoAssumpt_EgoRoadHeading 8191;
BA_ "GenSigSendType" SG_ 858 FLREgoAssumpt_EgoRoadCurvature 1;
BA_ "GenSigStartValue" SG_ 858 FLREgoAssumpt_EgoRoadCurvature 262143;
BA_ "GenSigSendType" SG_ 858 FLREgoAssumpt_EgoLongVel 1;
BA_ "GenSigStartValue" SG_ 858 FLREgoAssumpt_EgoLongVel 65535;
BA_ "GenSigSendType" SG_ 512 FwdSensingRadarStat_CRC 1;
BA_ "GenSigStartValue" SG_ 512 FwdSensingRadarStat_CRC 65535;
BA_ "E2EDataId" SG_ 512 FwdSensingRadarStat_CRC 148;
BA_ "E2EDataLength" SG_ 512 FwdSensingRadarStat_CRC 48;
BA_ "E2EProfile" SG_ 512 FwdSensingRadarStat_CRC "P05";
BA_ "GenSigSendType" SG_ 512 FwdSensingRadarStat_TimeSynch 1;
BA_ "GenSigCycleTime" SG_ 512 FwdRdr_CalibPausedYaw 100;
BA_ "GenSigCycleTimeActive" SG_ 512 FwdRdr_CalibPausedYaw 100;
BA_ "GenSigSendType" SG_ 512 FwdRadarStatus 1;
BA_ "GenSigStartValue" SG_ 512 FwdRadarStatus 15;
BA_ "GenSigCycleTime" SG_ 512 FwdRdr_CalibState 100;
BA_ "GenSigCycleTimeActive" SG_ 512 FwdRdr_CalibState 100;
BA_ "GenSigStartValue" SG_ 512 FwdRdr_CalibState 3;
BA_ "GenSigCycleTime" SG_ 512 FwdRdr_CalibPausedAcc 100;
BA_ "GenSigCycleTimeActive" SG_ 512 FwdRdr_CalibPausedAcc 100;
BA_ "GenSigSendType" SG_ 512 FwdSensingRadarStat_Counter 1;
BA_ "GenSigStartValue" SG_ 512 FwdSensingRadarStat_Counter 255;
BA_ "GenSigSendType" SG_ 512 FwdRadarStatus2_CRC 1;
BA_ "E2EDataId" SG_ 512 FwdRadarStatus2_CRC 262;
BA_ "E2EDataLength" SG_ 512 FwdRadarStatus2_CRC 32;
BA_ "E2EProfile" SG_ 512 FwdRadarStatus2_CRC "P05";
BA_ "GenSigCycleTime" SG_ 512 FwdRdr_CalibPausedSpeed 100;
BA_ "GenSigCycleTimeActive" SG_ 512 FwdRdr_CalibPausedSpeed 100;
BA_ "GenSigSendType" SG_ 512 FwdRadarStatus2_Status 1;
BA_ "GenSigStartValue" SG_ 512 FwdRadarStatus2_Status 15;
BA_ "GenSigSendType" SG_ 512 FwdSensingRadarStat_DecalDetect 1;
BA_ "GenSigStartValue" SG_ 512 FwdSensingRadarStat_DecalDetect 7;
BA_ "GenSigCycleTime" SG_ 512 FwdRdr_CalibProgress 100;
BA_ "GenSigCycleTimeActive" SG_ 512 FwdRdr_CalibProgress 100;
BA_ "GenSigStartValue" SG_ 512 FwdRdr_CalibProgress 127;
BA_ "GenSigSendType" SG_ 512 FwdRadarStatus2_SqC 1;
BA_ "GenSigSendType" SG_ 512 FwdSensingRadarStat_TargetDetect 1;
BA_ "GenSigStartValue" SG_ 512 FwdSensingRadarStat_TargetDetect 7;
BA_ "GenSigSendType" SG_ 512 FwdSensingRadarStat_BarrierDetec 1;
BA_ "GenSigStartValue" SG_ 512 FwdSensingRadarStat_BarrierDetec 7;
BA_ "GenSigSendType" SG_ 1959 Debug_07_FLR2 1;
BA_ "GenSigSendType" SG_ 1958 Debug_06_FLR2 1;
BA_ "GenSigSendType" SG_ 1957 Debug_05_FLR2 1;
BA_ "GenSigSendType" SG_ 1956 Debug_04_FLR2 1;
BA_ "GenSigSendType" SG_ 1955 Debug_03_FLR2 1;
BA_ "GenSigSendType" SG_ 1954 Debug_02_FLR2 1;
BA_ "GenSigSendType" SG_ 1953 Debug_01_FLR2 1;
BA_ "GenSigSendType" SG_ 2671964754 DiagUUDTRespSig_F2_52 7;
BA_ "GenSigSendType" SG_ 2671834194 InternalTesterDiagSig_F4_52 7;
BA_ "GenSigSendType" SG_ 2671833938 InternalTesterDiagSig_F3_52 7;
BA_ "GenSigSendType" SG_ 2671792884 InternalTesterDiagSig_52_F4 7;
BA_ "GenSigSendType" SG_ 2671792883 InternalTesterDiagSig_52_F3 7;
BA_ "GenSigSendType" SG_ 1527 DiagFaultStat_FLR_DtcIdB 3;
BA_ "NeedsUpdateBit" SG_ 1527 DiagFaultStat_FLR_DtcIdB 1;
BA_ "GenSigSendType" SG_ 1527 DiagFaultStat_FLR_FailTA 3;
BA_ "NeedsUpdateBit" SG_ 1527 DiagFaultStat_FLR_FailTA 1;
BA_ "GenSigSendType" SG_ 1527 DiagFaultStat_FLR_EcuAdr 3;
BA_ "GenSigStartValue" SG_ 1527 DiagFaultStat_FLR_EcuAdr 255;
BA_ "NeedsUpdateBit" SG_ 1527 DiagFaultStat_FLR_EcuAdr 1;
BA_ "GenSigSendType" SG_ 1527 DiagFaultStat_FLR_DtcIdA 3;
BA_ "NeedsUpdateBit" SG_ 1527 DiagFaultStat_FLR_DtcIdA 1;
BA_ "GenSigSendType" SG_ 1527 DiagFaultStat_FLR_sg_UB 7;
BA_ "GenSigSendType" SG_ 1527 DiagFaultStat_FLR_FailTB 3;
BA_ "NeedsUpdateBit" SG_ 1527 DiagFaultStat_FLR_FailTB 1;
BA_ "GenSigSendType" SG_ 257 DACUTimeSync_Time 1;
BA_ "GenSigSendType" SG_ 257 DACUTimeSync_CRC 1;
BA_ "GenSigSendType" SG_ 257 DACUTimeSync_UserByte 1;
BA_ "GenSigSendType" SG_ 257 DACUTimeSync_SeqCnt 1;
BA_ "GenSigStartValue" SG_ 257 DACUTimeSync_SeqCnt 15;
BA_ "GenSigSendType" SG_ 257 DACUTimeSync_Type 1;
BA_ "GenSigSendType" SG_ 257 DACUTimeSync_TimeDomain 1;
BA_ "GenSigStartValue" SG_ 257 DACUTimeSync_TimeDomain 15;
BA_ "GenSigSendType" SG_ 761 DACUTimeSyncOFS_TimeDomain 1;
BA_ "GenSigStartValue" SG_ 761 DACUTimeSyncOFS_TimeDomain 15;
BA_ "GenSigSendType" SG_ 761 DACUTimeSyncOFS_TypeOFS 1;
BA_ "GenSigSendType" SG_ 761 DACUTimeSyncOFS_SeqCnt 1;
BA_ "GenSigStartValue" SG_ 761 DACUTimeSyncOFS_SeqCnt 15;
BA_ "GenSigSendType" SG_ 761 DACUTimeSyncOFS_UserByte0 1;
BA_ "GenSigSendType" SG_ 761 DACUTimeSyncOFS_OfsTimeSec 1;
BA_ "GenSigSendType" SG_ 761 DACUTimeSyncOFS_CRCOFS 1;
BA_ "GenSigSendType" SG_ 760 DACUTimeSyncOFNS_SeqCnt 1;
BA_ "GenSigStartValue" SG_ 760 DACUTimeSyncOFNS_SeqCnt 15;
BA_ "GenSigSendType" SG_ 760 DACUTimeSyncOFNS_SGW 1;
BA_ "GenSigSendType" SG_ 760 DACUTimeSyncOFNS_OfsTimeNsec 1;
BA_ "GenSigSendType" SG_ 760 DACUTimeSyncOFNS_CRCOFNS 1;
BA_ "GenSigSendType" SG_ 760 DACUTimeSyncOFNS_TimeDomain 1;
BA_ "GenSigStartValue" SG_ 760 DACUTimeSyncOFNS_TimeDomain 15;
BA_ "GenSigSendType" SG_ 760 DACUTimeSyncOFNS_TypeOFNS 1;
BA_ "GenSigCycleTime" SG_ 279 EgoPathPrediction_Curvature 100;
BA_ "GenSigCycleTimeActive" SG_ 279 EgoPathPrediction_Curvature 100;
BA_ "GenSigStartValue" SG_ 279 EgoPathPrediction_Curvature 262143;
BA_ "GenSigCycleTime" SG_ 279 EgoPathPrediction_HeadingAngle 100;
BA_ "GenSigCycleTimeActive" SG_ 279 EgoPathPrediction_HeadingAngle 100;
BA_ "GenSigStartValue" SG_ 279 EgoPathPrediction_HeadingAngle 8191;
BA_ "GenSigCycleTime" SG_ 279 EgoPathPrediction_CurvatureRate 100;
BA_ "GenSigCycleTimeActive" SG_ 279 EgoPathPrediction_CurvatureRate 100;
BA_ "GenSigStartValue" SG_ 279 EgoPathPrediction_CurvatureRate 2047;
BA_ "GenSigCycleTime" SG_ 279 EgoPathPrediction_ConfCoeffA1 100;
BA_ "GenSigCycleTimeActive" SG_ 279 EgoPathPrediction_ConfCoeffA1 100;
BA_ "GenSigStartValue" SG_ 279 EgoPathPrediction_ConfCoeffA1 65535;
BA_ "GenSigCycleTime" SG_ 279 EgoPathPrediction_DxEnd 100;
BA_ "GenSigCycleTimeActive" SG_ 279 EgoPathPrediction_DxEnd 100;
BA_ "GenSigStartValue" SG_ 279 EgoPathPrediction_DxEnd 255;
BA_ "GenSigCycleTime" SG_ 279 EgoPathPrediction_ConfCoeffA3 100;
BA_ "GenSigCycleTimeActive" SG_ 279 EgoPathPrediction_ConfCoeffA3 100;
BA_ "GenSigStartValue" SG_ 279 EgoPathPrediction_ConfCoeffA3 65535;
BA_ "GenSigCycleTime" SG_ 279 EgoPathPrediction_ConfCoeffA0 100;
BA_ "GenSigCycleTimeActive" SG_ 279 EgoPathPrediction_ConfCoeffA0 100;
BA_ "GenSigStartValue" SG_ 279 EgoPathPrediction_ConfCoeffA0 65535;
BA_ "GenSigCycleTime" SG_ 279 EgoPathPrediction_ConfCoeffA2 100;
BA_ "GenSigCycleTimeActive" SG_ 279 EgoPathPrediction_ConfCoeffA2 100;
BA_ "GenSigStartValue" SG_ 279 EgoPathPrediction_ConfCoeffA2 65535;
BA_ "GenSigSendType" SG_ 275 EgoMotionXYplane_LongMotDirConf 1;
BA_ "GenSigStartValue" SG_ 275 EgoMotionXYplane_LongMotDirConf 15;
BA_ "GenSigSendType" SG_ 275 EgoMotionXYplane_LongSpeed 1;
BA_ "GenSigStartValue" SG_ 275 EgoMotionXYplane_LongSpeed 65535;
BA_ "GenSigSendType" SG_ 275 EgoMotionXYplane_EffectiveWheelB 1;
BA_ "GenSigStartValue" SG_ 275 EgoMotionXYplane_EffectiveWheelB 1023;
BA_ "GenSigSendType" SG_ 275 EgoMotionXYplane_LatAccVariance 1;
BA_ "GenSigStartValue" SG_ 275 EgoMotionXYplane_LatAccVariance 63;
BA_ "GenSigSendType" SG_ 275 EgoMotionXYplane_YawRateVariance 1;
BA_ "GenSigStartValue" SG_ 275 EgoMotionXYplane_YawRateVariance 65535;
BA_ "GenSigSendType" SG_ 275 EgoMotionXYplane_LateralSpeed 1;
BA_ "GenSigStartValue" SG_ 275 EgoMotionXYplane_LateralSpeed 65535;
BA_ "GenSigSendType" SG_ 275 EgoMotionXYplane_LongSpeedVar 1;
BA_ "GenSigStartValue" SG_ 275 EgoMotionXYplane_LongSpeedVar 65535;
BA_ "GenSigSendType" SG_ 275 EgoMotionXYplane_LateralAcc 1;
BA_ "GenSigStartValue" SG_ 275 EgoMotionXYplane_LateralAcc 65535;
BA_ "GenSigSendType" SG_ 275 EgoMotionXYplane_LongMotionDir 1;
BA_ "GenSigStartValue" SG_ 275 EgoMotionXYplane_LongMotionDir 7;
BA_ "GenSigSendType" SG_ 275 EgoMotionXYplane_LatencyEst 1;
BA_ "GenSigStartValue" SG_ 275 EgoMotionXYplane_LatencyEst 255;
BA_ "GenSigSendType" SG_ 275 EgoMotionXYplane_LongAcc 1;
BA_ "GenSigStartValue" SG_ 275 EgoMotionXYplane_LongAcc 65535;
BA_ "GenSigSendType" SG_ 275 EgoMotionXYplane_Counter 1;
BA_ "GenSigStartValue" SG_ 275 EgoMotionXYplane_Counter 255;
BA_ "GenSigSendType" SG_ 275 EgoMotionXYplane_Curvature 1;
BA_ "GenSigStartValue" SG_ 275 EgoMotionXYplane_Curvature 2097151;
BA_ "GenSigSendType" SG_ 275 EgoMotionXYplane_CRC 1;
BA_ "GenSigStartValue" SG_ 275 EgoMotionXYplane_CRC 65535;
BA_ "E2EDataId" SG_ 275 EgoMotionXYplane_CRC 17;
BA_ "E2EDataLength" SG_ 275 EgoMotionXYplane_CRC 240;
BA_ "E2EProfile" SG_ 275 EgoMotionXYplane_CRC "P05";
BA_ "GenSigSendType" SG_ 275 EgoMotionXYplane_ReferencePointX 1;
BA_ "GenSigStartValue" SG_ 275 EgoMotionXYplane_ReferencePointX 65535;
BA_ "GenSigSendType" SG_ 275 EgoMotionXYplane_LongAccVariance 1;
BA_ "GenSigStartValue" SG_ 275 EgoMotionXYplane_LongAccVariance 63;
BA_ "GenSigSendType" SG_ 275 EgoMotionXYplane_YawRateComp 1;
BA_ "GenSigStartValue" SG_ 275 EgoMotionXYplane_YawRateComp 65535;
BA_ "GenSigSendType" SG_ 275 EgoMotionXYplane_ChassisDynPitch 1;
BA_ "GenSigStartValue" SG_ 275 EgoMotionXYplane_ChassisDynPitch 255;
BA_ "GenSigSendType" SG_ 275 EgoMotionXYplane_LatSpeedVar 1;
BA_ "GenSigStartValue" SG_ 275 EgoMotionXYplane_LatSpeedVar 65535;
BA_ "GenSigSendType" SG_ 277 EgoMotionRaw_YCEngineActive 1;
BA_ "GenSigStartValue" SG_ 277 EgoMotionRaw_YCEngineActive 3;
BA_ "GenSigSendType" SG_ 277 EgoMotionRaw_ASREngineA 1;
BA_ "GenSigStartValue" SG_ 277 EgoMotionRaw_ASREngineA 3;
BA_ "GenSigSendType" SG_ 277 EgoMotionRaw_ASRBrakeA 1;
BA_ "GenSigStartValue" SG_ 277 EgoMotionRaw_ASRBrakeA 3;
BA_ "GenSigSendType" SG_ 277 EgoMotionRaw_RelLvlRrAxleRight 1;
BA_ "GenSigStartValue" SG_ 277 EgoMotionRaw_RelLvlRrAxleRight 65535;
BA_ "GenSigSendType" SG_ 277 EgoMotionRaw_ROPBrakeActive 1;
BA_ "GenSigStartValue" SG_ 277 EgoMotionRaw_ROPBrakeActive 3;
BA_ "GenSigSendType" SG_ 277 EgoMotionRaw_Counter 1;
BA_ "GenSigStartValue" SG_ 277 EgoMotionRaw_Counter 255;
BA_ "GenSigSendType" SG_ 277 EgoMotionRaw_RelLvlRrAxleLeft 1;
BA_ "GenSigStartValue" SG_ 277 EgoMotionRaw_RelLvlRrAxleLeft 65535;
BA_ "GenSigSendType" SG_ 277 EgoMotionRaw_AccKckDwn 1;
BA_ "GenSigStartValue" SG_ 277 EgoMotionRaw_AccKckDwn 3;
BA_ "GenSigSendType" SG_ 277 EgoMotionRaw_VDCFullyOperational 1;
BA_ "GenSigStartValue" SG_ 277 EgoMotionRaw_VDCFullyOperational 3;
BA_ "GenSigSendType" SG_ 277 EgoMotionRaw_FrontWheelAngle 1;
BA_ "GenSigStartValue" SG_ 277 EgoMotionRaw_FrontWheelAngle 65535;
BA_ "GenSigSendType" SG_ 277 EgoMotionRaw_BrakePedalPosition 1;
BA_ "GenSigStartValue" SG_ 277 EgoMotionRaw_BrakePedalPosition 255;
BA_ "GenSigSendType" SG_ 277 EgoMotionRaw_ABSOp 1;
BA_ "GenSigStartValue" SG_ 277 EgoMotionRaw_ABSOp 3;
BA_ "GenSigSendType" SG_ 277 EgoMotionRaw_RAxleRightWSpeed 1;
BA_ "GenSigStartValue" SG_ 277 EgoMotionRaw_RAxleRightWSpeed 65535;
BA_ "GenSigSendType" SG_ 277 EgoMotionRaw_GrossCombVehWeight 1;
BA_ "GenSigStartValue" SG_ 277 EgoMotionRaw_GrossCombVehWeight 65535;
BA_ "GenSigSendType" SG_ 277 EgoMotionRaw_CRC 1;
BA_ "GenSigStartValue" SG_ 277 EgoMotionRaw_CRC 65535;
BA_ "E2EDataId" SG_ 277 EgoMotionRaw_CRC 74;
BA_ "E2EDataLength" SG_ 277 EgoMotionRaw_CRC 248;
BA_ "E2EProfile" SG_ 277 EgoMotionRaw_CRC "P05";
BA_ "GenSigSendType" SG_ 277 EgoMotionRaw_FrAxleRightWSpeed 1;
BA_ "GenSigStartValue" SG_ 277 EgoMotionRaw_FrAxleRightWSpeed 65535;
BA_ "GenSigSendType" SG_ 277 EgoMotionRaw_ABSActive 1;
BA_ "GenSigStartValue" SG_ 277 EgoMotionRaw_ABSActive 3;
BA_ "GenSigSendType" SG_ 277 EgoMotionRaw_SteeringWheelAngle 1;
BA_ "GenSigStartValue" SG_ 277 EgoMotionRaw_SteeringWheelAngle 65535;
BA_ "GenSigSendType" SG_ 277 EgoMotionRaw_RelLvlFrAxleLeft 1;
BA_ "GenSigStartValue" SG_ 277 EgoMotionRaw_RelLvlFrAxleLeft 65535;
BA_ "GenSigSendType" SG_ 277 EgoMotionRaw_ROPEngineActive 1;
BA_ "GenSigStartValue" SG_ 277 EgoMotionRaw_ROPEngineActive 3;
BA_ "GenSigSendType" SG_ 277 EgoMotionRaw_FrAxleLeftWSpeed 1;
BA_ "GenSigStartValue" SG_ 277 EgoMotionRaw_FrAxleLeftWSpeed 65535;
BA_ "GenSigSendType" SG_ 277 EgoMotionRaw_YCBrakeActive 1;
BA_ "GenSigStartValue" SG_ 277 EgoMotionRaw_YCBrakeActive 3;
BA_ "GenSigSendType" SG_ 277 EgoMotionRaw_SteeringWheelRatio 1;
BA_ "GenSigStartValue" SG_ 277 EgoMotionRaw_SteeringWheelRatio 63;
BA_ "GenSigSendType" SG_ 277 EgoMotionRaw_AccPedalPos 1;
BA_ "GenSigStartValue" SG_ 277 EgoMotionRaw_AccPedalPos 255;
BA_ "GenSigSendType" SG_ 277 EgoMotionRaw_RelLvlFrAxleRight 1;
BA_ "GenSigStartValue" SG_ 277 EgoMotionRaw_RelLvlFrAxleRight 65535;
BA_ "GenSigSendType" SG_ 277 EgoMotionRaw_RAxleLeftWSpeed 1;
BA_ "GenSigStartValue" SG_ 277 EgoMotionRaw_RAxleLeftWSpeed 65535;
BA_ "GenSigSendType" SG_ 277 EgoMotionRaw_TrailerConStatus 1;
BA_ "GenSigStartValue" SG_ 277 EgoMotionRaw_TrailerConStatus 15;
BA_ "GenSigSendType" SG_ 1976 Debug_21_DACU 1;
BA_ "GenSigSendType" SG_ 1975 Debug_20_DACU 1;
BA_ "GenSigSendType" SG_ 1974 Debug_19_DACU 1;
BA_ "GenSigSendType" SG_ 1973 Debug_18_DACU 1;
BA_ "GenSigSendType" SG_ 1972 Debug_17_DACU 1;
BA_ "GenSigSendType" SG_ 1971 Debug_16_DACU 1;
BA_ "GenSigSendType" SG_ 1970 Debug_15_DACU 1;
BA_ "GenSigSendType" SG_ 1969 Debug_14_DACU 1;
BA_ "GenSigCycleTime" SG_ 333 HUALEDCtrl06_Orange 100;
BA_ "GenSigCycleTimeActive" SG_ 333 HUALEDCtrl06_Orange 100;
BA_ "GenSigStartValue" SG_ 333 HUALEDCtrl06_Orange 255;
BA_ "GenSigCycleTime" SG_ 333 HUALEDCtrl04_Orange 100;
BA_ "GenSigCycleTimeActive" SG_ 333 HUALEDCtrl04_Orange 100;
BA_ "GenSigStartValue" SG_ 333 HUALEDCtrl04_Orange 255;
BA_ "GenSigCycleTime" SG_ 333 HUALEDCtrl04_Red 100;
BA_ "GenSigCycleTimeActive" SG_ 333 HUALEDCtrl04_Red 100;
BA_ "GenSigStartValue" SG_ 333 HUALEDCtrl04_Red 255;
BA_ "GenSigCycleTime" SG_ 333 HUALEDCtrl03_Orange 100;
BA_ "GenSigCycleTimeActive" SG_ 333 HUALEDCtrl03_Orange 100;
BA_ "GenSigStartValue" SG_ 333 HUALEDCtrl03_Orange 255;
BA_ "GenSigCycleTime" SG_ 333 HUASelfTestCtrl 100;
BA_ "GenSigCycleTimeActive" SG_ 333 HUASelfTestCtrl 100;
BA_ "GenSigStartValue" SG_ 333 HUASelfTestCtrl 3;
BA_ "GenSigCycleTime" SG_ 333 HUALEDCtrl03_Red 100;
BA_ "GenSigCycleTimeActive" SG_ 333 HUALEDCtrl03_Red 100;
BA_ "GenSigStartValue" SG_ 333 HUALEDCtrl03_Red 255;
BA_ "GenSigCycleTime" SG_ 333 HUALEDCtrl02_Orange 100;
BA_ "GenSigCycleTimeActive" SG_ 333 HUALEDCtrl02_Orange 100;
BA_ "GenSigStartValue" SG_ 333 HUALEDCtrl02_Orange 255;
BA_ "GenSigCycleTime" SG_ 333 HUALEDCtrl02_Red 100;
BA_ "GenSigCycleTimeActive" SG_ 333 HUALEDCtrl02_Red 100;
BA_ "GenSigStartValue" SG_ 333 HUALEDCtrl02_Red 255;
BA_ "GenSigCycleTime" SG_ 333 HUALEDCtrl01_Orange 100;
BA_ "GenSigCycleTimeActive" SG_ 333 HUALEDCtrl01_Orange 100;
BA_ "GenSigStartValue" SG_ 333 HUALEDCtrl01_Orange 255;
BA_ "GenSigCycleTime" SG_ 333 HUALEDCtrl00_Red 100;
BA_ "GenSigCycleTimeActive" SG_ 333 HUALEDCtrl00_Red 100;
BA_ "GenSigStartValue" SG_ 333 HUALEDCtrl00_Red 255;
BA_ "GenSigCycleTime" SG_ 333 HUALEDCtrl00_Orange 100;
BA_ "GenSigCycleTimeActive" SG_ 333 HUALEDCtrl00_Orange 100;
BA_ "GenSigStartValue" SG_ 333 HUALEDCtrl00_Orange 255;
BA_ "GenSigCycleTime" SG_ 333 HUALEDCtrl01_Red 100;
BA_ "GenSigCycleTimeActive" SG_ 333 HUALEDCtrl01_Red 100;
BA_ "GenSigStartValue" SG_ 333 HUALEDCtrl01_Red 255;
BA_ "GenSigCycleTime" SG_ 333 HUAFading_Fadingtime 100;
BA_ "GenSigCycleTimeActive" SG_ 333 HUAFading_Fadingtime 100;
BA_ "GenSigStartValue" SG_ 333 HUAFading_Fadingtime 255;
BA_ "GenSigCycleTime" SG_ 333 HUAFlashingFrequency 100;
BA_ "GenSigCycleTimeActive" SG_ 333 HUAFlashingFrequency 100;
BA_ "GenSigStartValue" SG_ 333 HUAFlashingFrequency 15;
BA_ "GenSigCycleTime" SG_ 333 HUABrightnessMode 100;
BA_ "GenSigCycleTimeActive" SG_ 333 HUABrightnessMode 100;
BA_ "GenSigStartValue" SG_ 333 HUABrightnessMode 15;
BA_ "GenSigCycleTime" SG_ 333 HUAFading_FadingCtrl 100;
BA_ "GenSigCycleTimeActive" SG_ 333 HUAFading_FadingCtrl 100;
BA_ "GenSigCycleTime" SG_ 333 HUALEDCtrl05_Red 100;
BA_ "GenSigCycleTimeActive" SG_ 333 HUALEDCtrl05_Red 100;
BA_ "GenSigStartValue" SG_ 333 HUALEDCtrl05_Red 255;
BA_ "GenSigCycleTime" SG_ 333 HUALEDCtrl05_Orange 100;
BA_ "GenSigCycleTimeActive" SG_ 333 HUALEDCtrl05_Orange 100;
BA_ "GenSigStartValue" SG_ 333 HUALEDCtrl05_Orange 255;
BA_ "GenSigCycleTime" SG_ 333 HUALEDCtrl06_Red 100;
BA_ "GenSigCycleTimeActive" SG_ 333 HUALEDCtrl06_Red 100;
BA_ "GenSigStartValue" SG_ 333 HUALEDCtrl06_Red 255;
BA_ "GenSigCycleTime" SG_ 1077 HUAPowerDemand 100;
BA_ "GenSigCycleTimeActive" SG_ 1077 HUAPowerDemand 100;
BA_ "GenSigStartValue" SG_ 1077 HUAPowerDemand 3;
BA_ "GenSigCycleTime" SG_ 1077 TimeSynchStat_DACU 100;
BA_ "GenSigCycleTimeActive" SG_ 1077 TimeSynchStat_DACU 100;
BA_ "GenSigCycleTime" SG_ 1077 FrontCameraDynPitch 100;
BA_ "GenSigCycleTimeActive" SG_ 1077 FrontCameraDynPitch 100;
BA_ "GenSigStartValue" SG_ 1077 FrontCameraDynPitch 255;
BA_ "GenSigCycleTime" SG_ 1077 FrontCameraDynRoll 100;
BA_ "GenSigCycleTimeActive" SG_ 1077 FrontCameraDynRoll 100;
BA_ "GenSigStartValue" SG_ 1077 FrontCameraDynRoll 255;
BA_ "GenSigCycleTime" SG_ 1077 FRadarLoggingTrigger 100;
BA_ "GenSigCycleTimeActive" SG_ 1077 FRadarLoggingTrigger 100;
BA_ "GenSigStartValue" SG_ 1077 FRadarLoggingTrigger 7;
BA_ "GenSigCycleTime" SG_ 1543 VIN_DACU_Byte02 100;
BA_ "GenSigCycleTimeActive" SG_ 1543 VIN_DACU_Byte02 100;
BA_ "GenSigCycleTime" SG_ 1543 VIN_DACU_Byte09 100;
BA_ "GenSigCycleTimeActive" SG_ 1543 VIN_DACU_Byte09 100;
BA_ "GenSigCycleTime" SG_ 1543 VIN_DACU_Byte04 100;
BA_ "GenSigCycleTimeActive" SG_ 1543 VIN_DACU_Byte04 100;
BA_ "GenSigCycleTime" SG_ 1543 VIN_DACU_Byte07 100;
BA_ "GenSigCycleTimeActive" SG_ 1543 VIN_DACU_Byte07 100;
BA_ "GenSigCycleTime" SG_ 1543 VIN_DACU_Byte11 100;
BA_ "GenSigCycleTimeActive" SG_ 1543 VIN_DACU_Byte11 100;
BA_ "GenSigCycleTime" SG_ 1543 VIN_DACU_Byte06 100;
BA_ "GenSigCycleTimeActive" SG_ 1543 VIN_DACU_Byte06 100;
BA_ "GenSigCycleTime" SG_ 1543 VIN_DACU_Byte08 100;
BA_ "GenSigCycleTimeActive" SG_ 1543 VIN_DACU_Byte08 100;
BA_ "GenSigCycleTime" SG_ 1543 VIN_DACU_Byte15 100;
BA_ "GenSigCycleTimeActive" SG_ 1543 VIN_DACU_Byte15 100;
BA_ "GenSigCycleTime" SG_ 1543 VIN_DACU_Byte14 100;
BA_ "GenSigCycleTimeActive" SG_ 1543 VIN_DACU_Byte14 100;
BA_ "GenSigCycleTime" SG_ 1543 VIN_DACU_Byte16 100;
BA_ "GenSigCycleTimeActive" SG_ 1543 VIN_DACU_Byte16 100;
BA_ "GenSigCycleTime" SG_ 1543 VIN_DACU_Byte12 100;
BA_ "GenSigCycleTimeActive" SG_ 1543 VIN_DACU_Byte12 100;
BA_ "GenSigCycleTime" SG_ 1543 VIN_DACU_Byte01 100;
BA_ "GenSigCycleTimeActive" SG_ 1543 VIN_DACU_Byte01 100;
BA_ "GenSigCycleTime" SG_ 1543 VIN_DACU_Byte10 100;
BA_ "GenSigCycleTimeActive" SG_ 1543 VIN_DACU_Byte10 100;
BA_ "GenSigCycleTime" SG_ 1543 VIN_DACU_Byte03 100;
BA_ "GenSigCycleTimeActive" SG_ 1543 VIN_DACU_Byte03 100;
BA_ "GenSigCycleTime" SG_ 1543 VIN_DACU_Byte00 100;
BA_ "GenSigCycleTimeActive" SG_ 1543 VIN_DACU_Byte00 100;
BA_ "GenSigCycleTime" SG_ 1543 VIN_DACU_Byte05 100;
BA_ "GenSigCycleTimeActive" SG_ 1543 VIN_DACU_Byte05 100;
BA_ "GenSigCycleTime" SG_ 1543 VIN_DACU_Byte13 100;
BA_ "GenSigCycleTimeActive" SG_ 1543 VIN_DACU_Byte13 100;
BA_ "GenSigCycleTime" SG_ 1265 TachographLocalHourOffset 100;
BA_ "GenSigCycleTimeActive" SG_ 1265 TachographLocalHourOffset 100;
BA_ "GenSigStartValue" SG_ 1265 TachographLocalHourOffset 255;
BA_ "GenSigCycleTime" SG_ 1265 VehicleMode 100;
BA_ "GenSigCycleTimeActive" SG_ 1265 VehicleMode 100;
BA_ "GenSigStartValue" SG_ 1265 VehicleMode 15;
BA_ "NeedsUpdateBit" SG_ 1265 VehicleMode 1;
BA_ "GenSigCycleTime" SG_ 1265 AmbientAirTemperature 100;
BA_ "GenSigCycleTimeActive" SG_ 1265 AmbientAirTemperature 100;
BA_ "GenSigStartValue" SG_ 1265 AmbientAirTemperature 65535;
BA_ "SeToolAncestorID_SIGNAL" SG_ 1265 AmbientAirTemperature "x0000001D040FEBC8";
BA_ "SeToolItemID_SIGNAL" SG_ 1265 AmbientAirTemperature "x0000001D040FEBC8";
BA_ "SeToolName_SIGNAL" SG_ 1265 AmbientAirTemperature "AmbientAirTemperature";
BA_ "SeToolVersion_SIGNAL" SG_ 1265 AmbientAirTemperature "1";
BA_ "GenSigCycleTime" SG_ 1265 DayUTC 100;
BA_ "GenSigCycleTimeActive" SG_ 1265 DayUTC 100;
BA_ "GenSigStartValue" SG_ 1265 DayUTC 255;
BA_ "SeToolAncestorID_SIGNAL" SG_ 1265 DayUTC "x0000001D0412FAC4";
BA_ "SeToolItemID_SIGNAL" SG_ 1265 DayUTC "x0000001D041EBD81";
BA_ "SeToolName_SIGNAL" SG_ 1265 DayUTC "DayUTC";
BA_ "SeToolVersion_SIGNAL" SG_ 1265 DayUTC "2";
BA_ "GenSigCycleTime" SG_ 1265 TotalVehicleDistanceHighRes 100;
BA_ "GenSigCycleTimeActive" SG_ 1265 TotalVehicleDistanceHighRes 100;
BA_ "GenSigStartValue" SG_ 1265 TotalVehicleDistanceHighRes 4294967295;
BA_ "SeToolAncestorID_SIGNAL" SG_ 1265 TotalVehicleDistanceHighRes "x0000001D04109E2B";
BA_ "SeToolItemID_SIGNAL" SG_ 1265 TotalVehicleDistanceHighRes "x0000001D04109E2B";
BA_ "SeToolName_SIGNAL" SG_ 1265 TotalVehicleDistanceHighRes "HighResolutionTotalVehicleDistance";
BA_ "SeToolVersion_SIGNAL" SG_ 1265 TotalVehicleDistanceHighRes "1";
BA_ "GenSigCycleTime" SG_ 1265 TachographLocalMinuteOffset 100;
BA_ "GenSigCycleTimeActive" SG_ 1265 TachographLocalMinuteOffset 100;
BA_ "GenSigStartValue" SG_ 1265 TachographLocalMinuteOffset 255;
BA_ "GenSigSendType" SG_ 1265 VehicleMode_UB 7;
BA_ "GenSigCycleTime" SG_ 1265 SecondsUTC 100;
BA_ "GenSigCycleTimeActive" SG_ 1265 SecondsUTC 100;
BA_ "GenSigStartValue" SG_ 1265 SecondsUTC 255;
BA_ "SeToolAncestorID_SIGNAL" SG_ 1265 SecondsUTC "x0000001D0412FABE";
BA_ "SeToolItemID_SIGNAL" SG_ 1265 SecondsUTC "x0000001D041EBD32";
BA_ "SeToolName_SIGNAL" SG_ 1265 SecondsUTC "SecondsUTC";
BA_ "SeToolVersion_SIGNAL" SG_ 1265 SecondsUTC "2";
BA_ "GenSigCycleTime" SG_ 1265 YearUTC 100;
BA_ "GenSigCycleTimeActive" SG_ 1265 YearUTC 100;
BA_ "GenSigStartValue" SG_ 1265 YearUTC 255;
BA_ "SeToolAncestorID_SIGNAL" SG_ 1265 YearUTC "x0000001D0412FACB";
BA_ "SeToolItemID_SIGNAL" SG_ 1265 YearUTC "x0000001D041EBCEF";
BA_ "SeToolName_SIGNAL" SG_ 1265 YearUTC "YearUTC";
BA_ "SeToolVersion_SIGNAL" SG_ 1265 YearUTC "2";
BA_ "GenSigCycleTime" SG_ 1265 TrailerConnected 100;
BA_ "GenSigCycleTimeActive" SG_ 1265 TrailerConnected 100;
BA_ "GenSigStartValue" SG_ 1265 TrailerConnected 3;
BA_ "GenSigCycleTime" SG_ 1265 MonthUTC 100;
BA_ "GenSigCycleTimeActive" SG_ 1265 MonthUTC 100;
BA_ "GenSigStartValue" SG_ 1265 MonthUTC 255;
BA_ "SeToolAncestorID_SIGNAL" SG_ 1265 MonthUTC "x0000001D0412FAC9";
BA_ "SeToolItemID_SIGNAL" SG_ 1265 MonthUTC "x0000001D041EBD16";
BA_ "SeToolName_SIGNAL" SG_ 1265 MonthUTC "MonthUTC";
BA_ "SeToolVersion_SIGNAL" SG_ 1265 MonthUTC "2";
BA_ "GenSigCycleTime" SG_ 1265 HoursUTC 100;
BA_ "GenSigCycleTimeActive" SG_ 1265 HoursUTC 100;
BA_ "GenSigStartValue" SG_ 1265 HoursUTC 255;
BA_ "SeToolAncestorID_SIGNAL" SG_ 1265 HoursUTC "x0000001D0412FAC2";
BA_ "SeToolItemID_SIGNAL" SG_ 1265 HoursUTC "x0000001D041EBD20";
BA_ "SeToolName_SIGNAL" SG_ 1265 HoursUTC "HoursUTC";
BA_ "SeToolVersion_SIGNAL" SG_ 1265 HoursUTC "2";
BA_ "GenSigCycleTime" SG_ 1265 PloughLampModeStatus 100;
BA_ "GenSigCycleTimeActive" SG_ 1265 PloughLampModeStatus 100;
BA_ "GenSigStartValue" SG_ 1265 PloughLampModeStatus 3;
BA_ "GenSigCycleTime" SG_ 1265 LaneChangeStatus 100;
BA_ "GenSigCycleTimeActive" SG_ 1265 LaneChangeStatus 100;
BA_ "GenSigStartValue" SG_ 1265 LaneChangeStatus 15;
BA_ "GenSigCycleTime" SG_ 1265 WiperModeStatus 100;
BA_ "GenSigCycleTimeActive" SG_ 1265 WiperModeStatus 100;
BA_ "GenSigStartValue" SG_ 1265 WiperModeStatus 7;
BA_ "SeToolAncestorID_SIGNAL" SG_ 1265 WiperModeStatus "x0000001D0410D271";
BA_ "SeToolItemID_SIGNAL" SG_ 1265 WiperModeStatus "x0000001D0410D271";
BA_ "SeToolName_SIGNAL" SG_ 1265 WiperModeStatus "WiperModeStatus";
BA_ "SeToolVersion_SIGNAL" SG_ 1265 WiperModeStatus "1";
BA_ "GenSigCycleTime" SG_ 1265 MinutesUTC 100;
BA_ "GenSigCycleTimeActive" SG_ 1265 MinutesUTC 100;
BA_ "GenSigStartValue" SG_ 1265 MinutesUTC 255;
BA_ "SeToolAncestorID_SIGNAL" SG_ 1265 MinutesUTC "x0000001D0412FAC0";
BA_ "SeToolItemID_SIGNAL" SG_ 1265 MinutesUTC "x0000001D041EBD29";
BA_ "SeToolName_SIGNAL" SG_ 1265 MinutesUTC "MinutesUTC";
BA_ "SeToolVersion_SIGNAL" SG_ 1265 MinutesUTC "2";
BA_ "GenSigCycleTime" SG_ 1265 FLRPowerDemand 100;
BA_ "GenSigCycleTimeActive" SG_ 1265 FLRPowerDemand 100;
BA_ "GenSigStartValue" SG_ 1265 FLRPowerDemand 3;
BA_ "GenSigCycleTime" SG_ 1552 DACUSwVersion_Substring0 100;
BA_ "GenSigCycleTimeActive" SG_ 1552 DACUSwVersion_Substring0 100;
BA_ "GenSigCycleTime" SG_ 1552 DACUSwVersion_Substring6 100;
BA_ "GenSigCycleTimeActive" SG_ 1552 DACUSwVersion_Substring6 100;
BA_ "GenSigCycleTime" SG_ 1552 DACUSwVersion_Substring2 100;
BA_ "GenSigCycleTimeActive" SG_ 1552 DACUSwVersion_Substring2 100;
BA_ "GenSigCycleTime" SG_ 1552 DACUSwVersion_Substring5 100;
BA_ "GenSigCycleTimeActive" SG_ 1552 DACUSwVersion_Substring5 100;
BA_ "GenSigCycleTime" SG_ 1552 DACUSwVersion_Substring7 100;
BA_ "GenSigCycleTimeActive" SG_ 1552 DACUSwVersion_Substring7 100;
BA_ "GenSigCycleTime" SG_ 1552 DACUSwVersion_Substring1 100;
BA_ "GenSigCycleTimeActive" SG_ 1552 DACUSwVersion_Substring1 100;
BA_ "GenSigCycleTime" SG_ 1552 DACUSwVersion_Substring3 100;
BA_ "GenSigCycleTimeActive" SG_ 1552 DACUSwVersion_Substring3 100;
BA_ "GenSigCycleTime" SG_ 1552 DACUSwVersion_Substring4 100;
BA_ "GenSigCycleTimeActive" SG_ 1552 DACUSwVersion_Substring4 100;
BA_REL_ "GenSigFirstTimeoutTime" BU_SG_REL_ DACU SG_ 786 FLRObj03_ObjClass 3000;
BA_REL_ "GenSigTimeoutTime" BU_SG_REL_ DACU SG_ 786 FLRObj03_ObjClass 100;
BA_REL_ "GenSigFirstTimeoutTime" BU_SG_REL_ DACU SG_ 786 FLRObj03_LongAccVar 3000;
BA_REL_ "GenSigTimeoutTime" BU_SG_REL_ DACU SG_ 786 FLRObj03_LongAccVar 100;
BA_REL_ "GenSigFirstTimeoutTime" BU_SG_REL_ DACU SG_ 786 FLRObj03_LifeTime 3000;
BA_REL_ "GenSigTimeoutTime" BU_SG_REL_ DACU SG_ 786 FLRObj03_LifeTime 100;
BA_REL_ "GenSigFirstTimeoutTime" BU_SG_REL_ DACU SG_ 786 FLRObj03_LatExtLeft 3000;
BA_REL_ "GenSigTimeoutTime" BU_SG_REL_ DACU SG_ 786 FLRObj03_LatExtLeft 100;
BA_REL_ "GenSigFirstTimeoutTime" BU_SG_REL_ DACU SG_ 786 FLRObj03_ObjDynClass 3000;
BA_REL_ "GenSigTimeoutTime" BU_SG_REL_ DACU SG_ 786 FLRObj03_ObjDynClass 100;
BA_REL_ "GenSigFirstTimeoutTime" BU_SG_REL_ DACU SG_ 786 FLRObj03_LongVel 3000;
BA_REL_ "GenSigTimeoutTime" BU_SG_REL_ DACU SG_ 786 FLRObj03_LongVel 100;
BA_REL_ "GenSigFirstTimeoutTime" BU_SG_REL_ DACU SG_ 786 FLRObj03_ObstacleConf 3000;
BA_REL_ "GenSigTimeoutTime" BU_SG_REL_ DACU SG_ 786 FLRObj03_ObstacleConf 100;
BA_REL_ "GenSigFirstTimeoutTime" BU_SG_REL_ DACU SG_ 786 FLRObj03_LatExtRight 3000;
BA_REL_ "GenSigTimeoutTime" BU_SG_REL_ DACU SG_ 786 FLRObj03_LatExtRight 100;
BA_REL_ "GenSigFirstTimeoutTime" BU_SG_REL_ DACU SG_ 786 FLRObj03_CRC 3000;
BA_REL_ "GenSigTimeoutTime" BU_SG_REL_ DACU SG_ 786 FLRObj03_CRC 100;
BA_REL_ "GenSigFirstTimeoutTime" BU_SG_REL_ DACU SG_ 786 FLRObj03_Height 3000;
BA_REL_ "GenSigTimeoutTime" BU_SG_REL_ DACU SG_ 786 FLRObj03_Height 100;
BA_REL_ "GenSigFirstTimeoutTime" BU_SG_REL_ DACU SG_ 786 FLRObj03_LatExtRtVar 3000;
BA_REL_ "GenSigTimeoutTime" BU_SG_REL_ DACU SG_ 786 FLRObj03_LatExtRtVar 100;
BA_REL_ "GenSigFirstTimeoutTime" BU_SG_REL_ DACU SG_ 786 FLRObj03_AsilLvl 3000;
BA_REL_ "GenSigTimeoutTime" BU_SG_REL_ DACU SG_ 786 FLRObj03_AsilLvl 100;
BA_REL_ "GenSigFirstTimeoutTime" BU_SG_REL_ DACU SG_ 786 FLRObj03_TimeStamp 3000;
BA_REL_ "GenSigTimeoutTime" BU_SG_REL_ DACU SG_ 786 FLRObj03_TimeStamp 100;
BA_REL_ "GenSigFirstTimeoutTime" BU_SG_REL_ DACU SG_ 786 FLRObj03_ExistConf 3000;
BA_REL_ "GenSigTimeoutTime" BU_SG_REL_ DACU SG_ 786 FLRObj03_ExistConf 100;
BA_REL_ "GenSigFirstTimeoutTime" BU_SG_REL_ DACU SG_ 786 FLRObj03_LatExtLeftVar 3000;
BA_REL_ "GenSigTimeoutTime" BU_SG_REL_ DACU SG_ 786 FLRObj03_LatExtLeftVar 100;
BA_REL_ "GenSigFirstTimeoutTime" BU_SG_REL_ DACU SG_ 786 FLRObj03_ObstacleConfRestricted 3000;
BA_REL_ "GenSigTimeoutTime" BU_SG_REL_ DACU SG_ 786 FLRObj03_ObstacleConfRestricted 100;
BA_REL_ "GenSigFirstTimeoutTime" BU_SG_REL_ DACU SG_ 786 FLRObj03_Heading 3000;
BA_REL_ "GenSigTimeoutTime" BU_SG_REL_ DACU SG_ 786 FLRObj03_Heading 100;
BA_REL_ "GenSigFirstTimeoutTime" BU_SG_REL_ DACU SG_ 786 FLRObj03_LatPosVar 3000;
BA_REL_ "GenSigTimeoutTime" BU_SG_REL_ DACU SG_ 786 FLRObj03_LatPosVar 100;
BA_REL_ "GenSigFirstTimeoutTime" BU_SG_REL_ DACU SG_ 786 FLRObj03_LatPos 3000;
BA_REL_ "GenSigTimeoutTime" BU_SG_REL_ DACU SG_ 786 FLRObj03_LatPos 100;
BA_REL_ "GenSigFirstTimeoutTime" BU_SG_REL_ DACU SG_ 786 FLRObj03_LongExtBkVar 3000;
BA_REL_ "GenSigTimeoutTime" BU_SG_REL_ DACU SG_ 786 FLRObj03_LongExtBkVar 100;
BA_REL_ "GenSigFirstTimeoutTime" BU_SG_REL_ DACU SG_ 786 FLRObj03_CoastIndex 3000;
BA_REL_ "GenSigTimeoutTime" BU_SG_REL_ DACU SG_ 786 FLRObj03_CoastIndex 100;
BA_REL_ "GenSigFirstTimeoutTime" BU_SG_REL_ DACU SG_ 786 FLRObj03_LatAccVar 3000;
BA_REL_ "GenSigTimeoutTime" BU_SG_REL_ DACU SG_ 786 FLRObj03_LatAccVar 100;
BA_REL_ "GenSigFirstTimeoutTime" BU_SG_REL_ DACU SG_ 786 FLRObj03_LongAcc 3000;
BA_REL_ "GenSigTimeoutTime" BU_SG_REL_ DACU SG_ 786 FLRObj03_LongAcc 100;
BA_REL_ "GenSigFirstTimeoutTime" BU_SG_REL_ DACU SG_ 786 FLRObj03_ObjDynClassRestricted 3000;
BA_REL_ "GenSigTimeoutTime" BU_SG_REL_ DACU SG_ 786 FLRObj03_ObjDynClassRestricted 100;
BA_REL_ "GenSigFirstTimeoutTime" BU_SG_REL_ DACU SG_ 786 FLRObj03_ObjClassConf 3000;
BA_REL_ "GenSigTimeoutTime" BU_SG_REL_ DACU SG_ 786 FLRObj03_ObjClassConf 100;
BA_REL_ "GenSigFirstTimeoutTime" BU_SG_REL_ DACU SG_ 786 FLRObj03_LatVel 3000;
BA_REL_ "GenSigTimeoutTime" BU_SG_REL_ DACU SG_ 786 FLRObj03_LatVel 100;
BA_REL_ "GenSigFirstTimeoutTime" BU_SG_REL_ DACU SG_ 786 FLRObj03_LongExtFront 3000;
BA_REL_ "GenSigTimeoutTime" BU_SG_REL_ DACU SG_ 786 FLRObj03_LongExtFront 100;
BA_REL_ "GenSigFirstTimeoutTime" BU_SG_REL_ DACU SG_ 786 FLRObj03_LongVelVar 3000;
BA_REL_ "GenSigTimeoutTime" BU_SG_REL_ DACU SG_ 786 FLRObj03_LongVelVar 100;
BA_REL_ "GenSigFirstTimeoutTime" BU_SG_REL_ DACU SG_ 786 FLRObj03_LatVelVar 3000;
BA_REL_ "GenSigTimeoutTime" BU_SG_REL_ DACU SG_ 786 FLRObj03_LatVelVar 100;
BA_REL_ "GenSigFirstTimeoutTime" BU_SG_REL_ DACU SG_ 786 FLRObj03_LongExtBack 3000;
BA_REL_ "GenSigTimeoutTime" BU_SG_REL_ DACU SG_ 786 FLRObj03_LongExtBack 100;
BA_REL_ "GenSigFirstTimeoutTime" BU_SG_REL_ DACU SG_ 786 FLRObj03_LongPos 3000;
BA_REL_ "GenSigTimeoutTime" BU_SG_REL_ DACU SG_ 786 FLRObj03_LongPos 100;
BA_REL_ "GenSigFirstTimeoutTime" BU_SG_REL_ DACU SG_ 786 FLRObj03_HeadingVar 3000;
BA_REL_ "GenSigTimeoutTime" BU_SG_REL_ DACU SG_ 786 FLRObj03_HeadingVar 100;
BA_REL_ "GenSigFirstTimeoutTime" BU_SG_REL_ DACU SG_ 786 FLRObj03_LongPosVar 3000;
BA_REL_ "GenSigTimeoutTime" BU_SG_REL_ DACU SG_ 786 FLRObj03_LongPosVar 100;
BA_REL_ "GenSigFirstTimeoutTime" BU_SG_REL_ DACU SG_ 786 FLRObj03_ObjID 3000;
BA_REL_ "GenSigTimeoutTime" BU_SG_REL_ DACU SG_ 786 FLRObj03_ObjID 100;
BA_REL_ "GenSigFirstTimeoutTime" BU_SG_REL_ DACU SG_ 786 FLRObj03_LongExtFrVar 3000;
BA_REL_ "GenSigTimeoutTime" BU_SG_REL_ DACU SG_ 786 FLRObj03_LongExtFrVar 100;
BA_REL_ "GenSigFirstTimeoutTime" BU_SG_REL_ DACU SG_ 786 FLRObj03_LatAcc 3000;
BA_REL_ "GenSigTimeoutTime" BU_SG_REL_ DACU SG_ 786 FLRObj03_LatAcc 100;
BA_REL_ "GenSigFirstTimeoutTime" BU_SG_REL_ DACU SG_ 786 FLRObj03_Counter 3000;
BA_REL_ "GenSigTimeoutTime" BU_SG_REL_ DACU SG_ 786 FLRObj03_Counter 100;
BA_REL_ "GenSigFirstTimeoutTime" BU_SG_REL_ DACU SG_ 786 FLRObj03_TrackStatus 3000;
BA_REL_ "GenSigTimeoutTime" BU_SG_REL_ DACU SG_ 786 FLRObj03_TrackStatus 100;
BA_REL_ "GenSigFirstTimeoutTime" BU_SG_REL_ DACU SG_ 785 FLRObj02_CoastIndex 3000;
BA_REL_ "GenSigTimeoutTime" BU_SG_REL_ DACU SG_ 785 FLRObj02_CoastIndex 100;
BA_REL_ "GenSigFirstTimeoutTime" BU_SG_REL_ DACU SG_ 785 FLRObj02_LongExtBack 3000;
BA_REL_ "GenSigTimeoutTime" BU_SG_REL_ DACU SG_ 785 FLRObj02_LongExtBack 100;
BA_REL_ "GenSigFirstTimeoutTime" BU_SG_REL_ DACU SG_ 785 FLRObj02_ObstacleConfRestricted 3000;
BA_REL_ "GenSigTimeoutTime" BU_SG_REL_ DACU SG_ 785 FLRObj02_ObstacleConfRestricted 100;
BA_REL_ "GenSigFirstTimeoutTime" BU_SG_REL_ DACU SG_ 785 FLRObj02_LatVel 3000;
BA_REL_ "GenSigTimeoutTime" BU_SG_REL_ DACU SG_ 785 FLRObj02_LatVel 100;
BA_REL_ "GenSigFirstTimeoutTime" BU_SG_REL_ DACU SG_ 785 FLRObj02_ObstacleConf 3000;
BA_REL_ "GenSigTimeoutTime" BU_SG_REL_ DACU SG_ 785 FLRObj02_ObstacleConf 100;
BA_REL_ "GenSigFirstTimeoutTime" BU_SG_REL_ DACU SG_ 785 FLRObj02_AsilLvl 3000;
BA_REL_ "GenSigTimeoutTime" BU_SG_REL_ DACU SG_ 785 FLRObj02_AsilLvl 100;
BA_REL_ "GenSigFirstTimeoutTime" BU_SG_REL_ DACU SG_ 785 FLRObj02_LatExtLeft 3000;
BA_REL_ "GenSigTimeoutTime" BU_SG_REL_ DACU SG_ 785 FLRObj02_LatExtLeft 100;
BA_REL_ "GenSigFirstTimeoutTime" BU_SG_REL_ DACU SG_ 785 FLRObj02_CRC 3000;
BA_REL_ "GenSigTimeoutTime" BU_SG_REL_ DACU SG_ 785 FLRObj02_CRC 100;
BA_REL_ "GenSigFirstTimeoutTime" BU_SG_REL_ DACU SG_ 785 FLRObj02_LongVelVar 3000;
BA_REL_ "GenSigTimeoutTime" BU_SG_REL_ DACU SG_ 785 FLRObj02_LongVelVar 100;
BA_REL_ "GenSigFirstTimeoutTime" BU_SG_REL_ DACU SG_ 785 FLRObj02_Counter 3000;
BA_REL_ "GenSigTimeoutTime" BU_SG_REL_ DACU SG_ 785 FLRObj02_Counter 100;
BA_REL_ "GenSigFirstTimeoutTime" BU_SG_REL_ DACU SG_ 785 FLRObj02_LongPos 3000;
BA_REL_ "GenSigTimeoutTime" BU_SG_REL_ DACU SG_ 785 FLRObj02_LongPos 100;
BA_REL_ "GenSigFirstTimeoutTime" BU_SG_REL_ DACU SG_ 785 FLRObj02_LatExtLeftVar 3000;
BA_REL_ "GenSigTimeoutTime" BU_SG_REL_ DACU SG_ 785 FLRObj02_LatExtLeftVar 100;
BA_REL_ "GenSigFirstTimeoutTime" BU_SG_REL_ DACU SG_ 785 FLRObj02_LongExtBkVar 3000;
BA_REL_ "GenSigTimeoutTime" BU_SG_REL_ DACU SG_ 785 FLRObj02_LongExtBkVar 100;
BA_REL_ "GenSigFirstTimeoutTime" BU_SG_REL_ DACU SG_ 785 FLRObj02_LongVel 3000;
BA_REL_ "GenSigTimeoutTime" BU_SG_REL_ DACU SG_ 785 FLRObj02_LongVel 100;
BA_REL_ "GenSigFirstTimeoutTime" BU_SG_REL_ DACU SG_ 785 FLRObj02_ObjDynClassRestricted 3000;
BA_REL_ "GenSigTimeoutTime" BU_SG_REL_ DACU SG_ 785 FLRObj02_ObjDynClassRestricted 100;
BA_REL_ "GenSigFirstTimeoutTime" BU_SG_REL_ DACU SG_ 785 FLRObj02_LongExtFront 3000;
BA_REL_ "GenSigTimeoutTime" BU_SG_REL_ DACU SG_ 785 FLRObj02_LongExtFront 100;
BA_REL_ "GenSigFirstTimeoutTime" BU_SG_REL_ DACU SG_ 785 FLRObj02_LongAccVar 3000;
BA_REL_ "GenSigTimeoutTime" BU_SG_REL_ DACU SG_ 785 FLRObj02_LongAccVar 100;
BA_REL_ "GenSigFirstTimeoutTime" BU_SG_REL_ DACU SG_ 785 FLRObj02_LatAccVar 3000;
BA_REL_ "GenSigTimeoutTime" BU_SG_REL_ DACU SG_ 785 FLRObj02_LatAccVar 100;
BA_REL_ "GenSigFirstTimeoutTime" BU_SG_REL_ DACU SG_ 785 FLRObj02_LongPosVar 3000;
BA_REL_ "GenSigTimeoutTime" BU_SG_REL_ DACU SG_ 785 FLRObj02_LongPosVar 100;
BA_REL_ "GenSigFirstTimeoutTime" BU_SG_REL_ DACU SG_ 785 FLRObj02_LatExtRtVar 3000;
BA_REL_ "GenSigTimeoutTime" BU_SG_REL_ DACU SG_ 785 FLRObj02_LatExtRtVar 100;
BA_REL_ "GenSigFirstTimeoutTime" BU_SG_REL_ DACU SG_ 785 FLRObj02_LatPos 3000;
BA_REL_ "GenSigTimeoutTime" BU_SG_REL_ DACU SG_ 785 FLRObj02_LatPos 100;
BA_REL_ "GenSigFirstTimeoutTime" BU_SG_REL_ DACU SG_ 785 FLRObj02_ExistConf 3000;
BA_REL_ "GenSigTimeoutTime" BU_SG_REL_ DACU SG_ 785 FLRObj02_ExistConf 100;
BA_REL_ "GenSigFirstTimeoutTime" BU_SG_REL_ DACU SG_ 785 FLRObj02_LongExtFrVar 3000;
BA_REL_ "GenSigTimeoutTime" BU_SG_REL_ DACU SG_ 785 FLRObj02_LongExtFrVar 100;
BA_REL_ "GenSigFirstTimeoutTime" BU_SG_REL_ DACU SG_ 785 FLRObj02_ObjClass 3000;
BA_REL_ "GenSigTimeoutTime" BU_SG_REL_ DACU SG_ 785 FLRObj02_ObjClass 100;
BA_REL_ "GenSigFirstTimeoutTime" BU_SG_REL_ DACU SG_ 785 FLRObj02_Heading 3000;
BA_REL_ "GenSigTimeoutTime" BU_SG_REL_ DACU SG_ 785 FLRObj02_Heading 100;
BA_REL_ "GenSigFirstTimeoutTime" BU_SG_REL_ DACU SG_ 785 FLRObj02_TimeStamp 3000;
BA_REL_ "GenSigTimeoutTime" BU_SG_REL_ DACU SG_ 785 FLRObj02_TimeStamp 100;
BA_REL_ "GenSigFirstTimeoutTime" BU_SG_REL_ DACU SG_ 785 FLRObj02_ObjClassConf 3000;
BA_REL_ "GenSigTimeoutTime" BU_SG_REL_ DACU SG_ 785 FLRObj02_ObjClassConf 100;
BA_REL_ "GenSigFirstTimeoutTime" BU_SG_REL_ DACU SG_ 785 FLRObj02_Height 3000;
BA_REL_ "GenSigTimeoutTime" BU_SG_REL_ DACU SG_ 785 FLRObj02_Height 100;
BA_REL_ "GenSigFirstTimeoutTime" BU_SG_REL_ DACU SG_ 785 FLRObj02_LifeTime 3000;
BA_REL_ "GenSigTimeoutTime" BU_SG_REL_ DACU SG_ 785 FLRObj02_LifeTime 100;
BA_REL_ "GenSigFirstTimeoutTime" BU_SG_REL_ DACU SG_ 785 FLRObj02_TrackStatus 3000;
BA_REL_ "GenSigTimeoutTime" BU_SG_REL_ DACU SG_ 785 FLRObj02_TrackStatus 100;
BA_REL_ "GenSigFirstTimeoutTime" BU_SG_REL_ DACU SG_ 785 FLRObj02_LatAcc 3000;
BA_REL_ "GenSigTimeoutTime" BU_SG_REL_ DACU SG_ 785 FLRObj02_LatAcc 100;
BA_REL_ "GenSigFirstTimeoutTime" BU_SG_REL_ DACU SG_ 785 FLRObj02_LatVelVar 3000;
BA_REL_ "GenSigTimeoutTime" BU_SG_REL_ DACU SG_ 785 FLRObj02_LatVelVar 100;
BA_REL_ "GenSigFirstTimeoutTime" BU_SG_REL_ DACU SG_ 785 FLRObj02_ObjDynClass 3000;
BA_REL_ "GenSigTimeoutTime" BU_SG_REL_ DACU SG_ 785 FLRObj02_ObjDynClass 100;
BA_REL_ "GenSigFirstTimeoutTime" BU_SG_REL_ DACU SG_ 785 FLRObj02_ObjID 3000;
BA_REL_ "GenSigTimeoutTime" BU_SG_REL_ DACU SG_ 785 FLRObj02_ObjID 100;
BA_REL_ "GenSigFirstTimeoutTime" BU_SG_REL_ DACU SG_ 785 FLRObj02_LatExtRight 3000;
BA_REL_ "GenSigTimeoutTime" BU_SG_REL_ DACU SG_ 785 FLRObj02_LatExtRight 100;
BA_REL_ "GenSigFirstTimeoutTime" BU_SG_REL_ DACU SG_ 785 FLRObj02_LatPosVar 3000;
BA_REL_ "GenSigTimeoutTime" BU_SG_REL_ DACU SG_ 785 FLRObj02_LatPosVar 100;
BA_REL_ "GenSigFirstTimeoutTime" BU_SG_REL_ DACU SG_ 785 FLRObj02_HeadingVar 3000;
BA_REL_ "GenSigTimeoutTime" BU_SG_REL_ DACU SG_ 785 FLRObj02_HeadingVar 100;
BA_REL_ "GenSigFirstTimeoutTime" BU_SG_REL_ DACU SG_ 785 FLRObj02_LongAcc 3000;
BA_REL_ "GenSigTimeoutTime" BU_SG_REL_ DACU SG_ 785 FLRObj02_LongAcc 100;
BA_REL_ "GenSigFirstTimeoutTime" BU_SG_REL_ DACU SG_ 784 FLRObj01_LatPos 3000;
BA_REL_ "GenSigTimeoutTime" BU_SG_REL_ DACU SG_ 784 FLRObj01_LatPos 100;
BA_REL_ "GenSigFirstTimeoutTime" BU_SG_REL_ DACU SG_ 784 FLRObj01_LifeTime 3000;
BA_REL_ "GenSigTimeoutTime" BU_SG_REL_ DACU SG_ 784 FLRObj01_LifeTime 100;
BA_REL_ "GenSigFirstTimeoutTime" BU_SG_REL_ DACU SG_ 784 FLRObj01_LongExtBack 3000;
BA_REL_ "GenSigTimeoutTime" BU_SG_REL_ DACU SG_ 784 FLRObj01_LongExtBack 100;
BA_REL_ "GenSigFirstTimeoutTime" BU_SG_REL_ DACU SG_ 784 FLRObj01_TimeStamp 3000;
BA_REL_ "GenSigTimeoutTime" BU_SG_REL_ DACU SG_ 784 FLRObj01_TimeStamp 100;
BA_REL_ "GenSigFirstTimeoutTime" BU_SG_REL_ DACU SG_ 784 FLRObj01_LongVelVar 3000;
BA_REL_ "GenSigTimeoutTime" BU_SG_REL_ DACU SG_ 784 FLRObj01_LongVelVar 100;
BA_REL_ "GenSigFirstTimeoutTime" BU_SG_REL_ DACU SG_ 784 FLRObj01_LatExtRight 3000;
BA_REL_ "GenSigTimeoutTime" BU_SG_REL_ DACU SG_ 784 FLRObj01_LatExtRight 100;
BA_REL_ "GenSigFirstTimeoutTime" BU_SG_REL_ DACU SG_ 784 FLRObj01_ObstacleConfRestricted 3000;
BA_REL_ "GenSigTimeoutTime" BU_SG_REL_ DACU SG_ 784 FLRObj01_ObstacleConfRestricted 100;
BA_REL_ "GenSigFirstTimeoutTime" BU_SG_REL_ DACU SG_ 784 FLRObj01_ObjID 3000;
BA_REL_ "GenSigTimeoutTime" BU_SG_REL_ DACU SG_ 784 FLRObj01_ObjID 100;
BA_REL_ "GenSigFirstTimeoutTime" BU_SG_REL_ DACU SG_ 784 FLRObj01_Counter 3000;
BA_REL_ "GenSigTimeoutTime" BU_SG_REL_ DACU SG_ 784 FLRObj01_Counter 100;
BA_REL_ "GenSigFirstTimeoutTime" BU_SG_REL_ DACU SG_ 784 FLRObj01_LongExtBkVar 3000;
BA_REL_ "GenSigTimeoutTime" BU_SG_REL_ DACU SG_ 784 FLRObj01_LongExtBkVar 100;
BA_REL_ "GenSigFirstTimeoutTime" BU_SG_REL_ DACU SG_ 784 FLRObj01_CRC 3000;
BA_REL_ "GenSigTimeoutTime" BU_SG_REL_ DACU SG_ 784 FLRObj01_CRC 100;
BA_REL_ "GenSigFirstTimeoutTime" BU_SG_REL_ DACU SG_ 784 FLRObj01_AsilLvl 3000;
BA_REL_ "GenSigTimeoutTime" BU_SG_REL_ DACU SG_ 784 FLRObj01_AsilLvl 100;
BA_REL_ "GenSigFirstTimeoutTime" BU_SG_REL_ DACU SG_ 784 FLRObj01_HeadingVar 3000;
BA_REL_ "GenSigTimeoutTime" BU_SG_REL_ DACU SG_ 784 FLRObj01_HeadingVar 100;
BA_REL_ "GenSigFirstTimeoutTime" BU_SG_REL_ DACU SG_ 784 FLRObj01_Heading 3000;
BA_REL_ "GenSigTimeoutTime" BU_SG_REL_ DACU SG_ 784 FLRObj01_Heading 100;
BA_REL_ "GenSigFirstTimeoutTime" BU_SG_REL_ DACU SG_ 784 FLRObj01_ObjClass 3000;
BA_REL_ "GenSigTimeoutTime" BU_SG_REL_ DACU SG_ 784 FLRObj01_ObjClass 100;
BA_REL_ "GenSigFirstTimeoutTime" BU_SG_REL_ DACU SG_ 784 FLRObj01_LatVelVar 3000;
BA_REL_ "GenSigTimeoutTime" BU_SG_REL_ DACU SG_ 784 FLRObj01_LatVelVar 100;
BA_REL_ "GenSigFirstTimeoutTime" BU_SG_REL_ DACU SG_ 784 FLRObj01_LongPos 3000;
BA_REL_ "GenSigTimeoutTime" BU_SG_REL_ DACU SG_ 784 FLRObj01_LongPos 100;
BA_REL_ "GenSigFirstTimeoutTime" BU_SG_REL_ DACU SG_ 784 FLRObj01_LongAcc 3000;
BA_REL_ "GenSigTimeoutTime" BU_SG_REL_ DACU SG_ 784 FLRObj01_LongAcc 100;
BA_REL_ "GenSigFirstTimeoutTime" BU_SG_REL_ DACU SG_ 784 FLRObj01_LongPosVar 3000;
BA_REL_ "GenSigTimeoutTime" BU_SG_REL_ DACU SG_ 784 FLRObj01_LongPosVar 100;
BA_REL_ "GenSigFirstTimeoutTime" BU_SG_REL_ DACU SG_ 784 FLRObj01_ObjClassConf 3000;
BA_REL_ "GenSigTimeoutTime" BU_SG_REL_ DACU SG_ 784 FLRObj01_ObjClassConf 100;
BA_REL_ "GenSigFirstTimeoutTime" BU_SG_REL_ DACU SG_ 784 FLRObj01_LatExtLeftVar 3000;
BA_REL_ "GenSigTimeoutTime" BU_SG_REL_ DACU SG_ 784 FLRObj01_LatExtLeftVar 100;
BA_REL_ "GenSigFirstTimeoutTime" BU_SG_REL_ DACU SG_ 784 FLRObj01_LatAccVar 3000;
BA_REL_ "GenSigTimeoutTime" BU_SG_REL_ DACU SG_ 784 FLRObj01_LatAccVar 100;
BA_REL_ "GenSigFirstTimeoutTime" BU_SG_REL_ DACU SG_ 784 FLRObj01_ObjDynClassRestricted 3000;
BA_REL_ "GenSigTimeoutTime" BU_SG_REL_ DACU SG_ 784 FLRObj01_ObjDynClassRestricted 100;
BA_REL_ "GenSigFirstTimeoutTime" BU_SG_REL_ DACU SG_ 784 FLRObj01_ExistConf 3000;
BA_REL_ "GenSigTimeoutTime" BU_SG_REL_ DACU SG_ 784 FLRObj01_ExistConf 100;
BA_REL_ "GenSigFirstTimeoutTime" BU_SG_REL_ DACU SG_ 784 FLRObj01_LatAcc 3000;
BA_REL_ "GenSigTimeoutTime" BU_SG_REL_ DACU SG_ 784 FLRObj01_LatAcc 100;
BA_REL_ "GenSigFirstTimeoutTime" BU_SG_REL_ DACU SG_ 784 FLRObj01_LongVel 3000;
BA_REL_ "GenSigTimeoutTime" BU_SG_REL_ DACU SG_ 784 FLRObj01_LongVel 100;
BA_REL_ "GenSigFirstTimeoutTime" BU_SG_REL_ DACU SG_ 784 FLRObj01_CoastIndex 3000;
BA_REL_ "GenSigTimeoutTime" BU_SG_REL_ DACU SG_ 784 FLRObj01_CoastIndex 100;
BA_REL_ "GenSigFirstTimeoutTime" BU_SG_REL_ DACU SG_ 784 FLRObj01_LongExtFrVar 3000;
BA_REL_ "GenSigTimeoutTime" BU_SG_REL_ DACU SG_ 784 FLRObj01_LongExtFrVar 100;
BA_REL_ "GenSigFirstTimeoutTime" BU_SG_REL_ DACU SG_ 784 FLRObj01_LatExtRtVar 3000;
BA_REL_ "GenSigTimeoutTime" BU_SG_REL_ DACU SG_ 784 FLRObj01_LatExtRtVar 100;
BA_REL_ "GenSigFirstTimeoutTime" BU_SG_REL_ DACU SG_ 784 FLRObj01_LongExtFront 3000;
BA_REL_ "GenSigTimeoutTime" BU_SG_REL_ DACU SG_ 784 FLRObj01_LongExtFront 100;
BA_REL_ "GenSigFirstTimeoutTime" BU_SG_REL_ DACU SG_ 784 FLRObj01_LatPosVar 3000;
BA_REL_ "GenSigTimeoutTime" BU_SG_REL_ DACU SG_ 784 FLRObj01_LatPosVar 100;
BA_REL_ "GenSigFirstTimeoutTime" BU_SG_REL_ DACU SG_ 784 FLRObj01_TrackStatus 3000;
BA_REL_ "GenSigTimeoutTime" BU_SG_REL_ DACU SG_ 784 FLRObj01_TrackStatus 100;
BA_REL_ "GenSigFirstTimeoutTime" BU_SG_REL_ DACU SG_ 784 FLRObj01_LatExtLeft 3000;
BA_REL_ "GenSigTimeoutTime" BU_SG_REL_ DACU SG_ 784 FLRObj01_LatExtLeft 100;
BA_REL_ "GenSigFirstTimeoutTime" BU_SG_REL_ DACU SG_ 784 FLRObj01_ObstacleConf 3000;
BA_REL_ "GenSigTimeoutTime" BU_SG_REL_ DACU SG_ 784 FLRObj01_ObstacleConf 100;
BA_REL_ "GenSigFirstTimeoutTime" BU_SG_REL_ DACU SG_ 784 FLRObj01_ObjDynClass 3000;
BA_REL_ "GenSigTimeoutTime" BU_SG_REL_ DACU SG_ 784 FLRObj01_ObjDynClass 100;
BA_REL_ "GenSigFirstTimeoutTime" BU_SG_REL_ DACU SG_ 784 FLRObj01_LatVel 3000;
BA_REL_ "GenSigTimeoutTime" BU_SG_REL_ DACU SG_ 784 FLRObj01_LatVel 100;
BA_REL_ "GenSigFirstTimeoutTime" BU_SG_REL_ DACU SG_ 784 FLRObj01_Height 3000;
BA_REL_ "GenSigTimeoutTime" BU_SG_REL_ DACU SG_ 784 FLRObj01_Height 100;
BA_REL_ "GenSigFirstTimeoutTime" BU_SG_REL_ DACU SG_ 784 FLRObj01_LongAccVar 3000;
BA_REL_ "GenSigTimeoutTime" BU_SG_REL_ DACU SG_ 784 FLRObj01_LongAccVar 100;
BA_REL_ "GenSigFirstTimeoutTime" BU_SG_REL_ DACU SG_ 783 FLRObj00_LongVelVar 3000;
BA_REL_ "GenSigTimeoutTime" BU_SG_REL_ DACU SG_ 783 FLRObj00_LongVelVar 100;
BA_REL_ "GenSigFirstTimeoutTime" BU_SG_REL_ DACU SG_ 783 FLRObj00_LongPos 3000;
BA_REL_ "GenSigTimeoutTime" BU_SG_REL_ DACU SG_ 783 FLRObj00_LongPos 100;
BA_REL_ "GenSigFirstTimeoutTime" BU_SG_REL_ DACU SG_ 783 FLRObj00_LongExtBack 3000;
BA_REL_ "GenSigTimeoutTime" BU_SG_REL_ DACU SG_ 783 FLRObj00_LongExtBack 100;
BA_REL_ "GenSigFirstTimeoutTime" BU_SG_REL_ DACU SG_ 783 FLRObj00_LatPosVar 3000;
BA_REL_ "GenSigTimeoutTime" BU_SG_REL_ DACU SG_ 783 FLRObj00_LatPosVar 100;
BA_REL_ "GenSigFirstTimeoutTime" BU_SG_REL_ DACU SG_ 783 FLRObj00_LongExtFront 3000;
BA_REL_ "GenSigTimeoutTime" BU_SG_REL_ DACU SG_ 783 FLRObj00_LongExtFront 100;
BA_REL_ "GenSigFirstTimeoutTime" BU_SG_REL_ DACU SG_ 783 FLRObj00_AsilLvl 3000;
BA_REL_ "GenSigTimeoutTime" BU_SG_REL_ DACU SG_ 783 FLRObj00_AsilLvl 100;
BA_REL_ "GenSigFirstTimeoutTime" BU_SG_REL_ DACU SG_ 783 FLRObj00_LatExtLeft 3000;
BA_REL_ "GenSigTimeoutTime" BU_SG_REL_ DACU SG_ 783 FLRObj00_LatExtLeft 100;
BA_REL_ "GenSigFirstTimeoutTime" BU_SG_REL_ DACU SG_ 783 FLRObj00_LongAccVar 3000;
BA_REL_ "GenSigTimeoutTime" BU_SG_REL_ DACU SG_ 783 FLRObj00_LongAccVar 100;
BA_REL_ "GenSigFirstTimeoutTime" BU_SG_REL_ DACU SG_ 783 FLRObj00_LifeTime 3000;
BA_REL_ "GenSigTimeoutTime" BU_SG_REL_ DACU SG_ 783 FLRObj00_LifeTime 100;
BA_REL_ "GenSigFirstTimeoutTime" BU_SG_REL_ DACU SG_ 783 FLRObj00_LatExtRight 3000;
BA_REL_ "GenSigTimeoutTime" BU_SG_REL_ DACU SG_ 783 FLRObj00_LatExtRight 100;
BA_REL_ "GenSigFirstTimeoutTime" BU_SG_REL_ DACU SG_ 783 FLRObj00_ObjDynClass 3000;
BA_REL_ "GenSigTimeoutTime" BU_SG_REL_ DACU SG_ 783 FLRObj00_ObjDynClass 100;
BA_REL_ "GenSigFirstTimeoutTime" BU_SG_REL_ DACU SG_ 783 FLRObj00_LatAcc 3000;
BA_REL_ "GenSigTimeoutTime" BU_SG_REL_ DACU SG_ 783 FLRObj00_LatAcc 100;
BA_REL_ "GenSigFirstTimeoutTime" BU_SG_REL_ DACU SG_ 783 FLRObj00_Height 3000;
BA_REL_ "GenSigTimeoutTime" BU_SG_REL_ DACU SG_ 783 FLRObj00_Height 100;
BA_REL_ "GenSigFirstTimeoutTime" BU_SG_REL_ DACU SG_ 783 FLRObj00_LongExtFrVar 3000;
BA_REL_ "GenSigTimeoutTime" BU_SG_REL_ DACU SG_ 783 FLRObj00_LongExtFrVar 100;
BA_REL_ "GenSigFirstTimeoutTime" BU_SG_REL_ DACU SG_ 783 FLRObj00_LatPos 3000;
BA_REL_ "GenSigTimeoutTime" BU_SG_REL_ DACU SG_ 783 FLRObj00_LatPos 100;
BA_REL_ "GenSigFirstTimeoutTime" BU_SG_REL_ DACU SG_ 783 FLRObj00_LongVel 3000;
BA_REL_ "GenSigTimeoutTime" BU_SG_REL_ DACU SG_ 783 FLRObj00_LongVel 100;
BA_REL_ "GenSigFirstTimeoutTime" BU_SG_REL_ DACU SG_ 783 FLRObj00_ObjClassConf 3000;
BA_REL_ "GenSigTimeoutTime" BU_SG_REL_ DACU SG_ 783 FLRObj00_ObjClassConf 100;
BA_REL_ "GenSigFirstTimeoutTime" BU_SG_REL_ DACU SG_ 783 FLRObj00_ObjID 3000;
BA_REL_ "GenSigTimeoutTime" BU_SG_REL_ DACU SG_ 783 FLRObj00_ObjID 100;
BA_REL_ "GenSigFirstTimeoutTime" BU_SG_REL_ DACU SG_ 783 FLRObj00_LongPosVar 3000;
BA_REL_ "GenSigTimeoutTime" BU_SG_REL_ DACU SG_ 783 FLRObj00_LongPosVar 100;
BA_REL_ "GenSigFirstTimeoutTime" BU_SG_REL_ DACU SG_ 783 FLRObj00_TimeStamp 3000;
BA_REL_ "GenSigTimeoutTime" BU_SG_REL_ DACU SG_ 783 FLRObj00_TimeStamp 100;
BA_REL_ "GenSigFirstTimeoutTime" BU_SG_REL_ DACU SG_ 783 FLRObj00_ObstacleConf 3000;
BA_REL_ "GenSigTimeoutTime" BU_SG_REL_ DACU SG_ 783 FLRObj00_ObstacleConf 100;
BA_REL_ "GenSigFirstTimeoutTime" BU_SG_REL_ DACU SG_ 783 FLRObj00_ObjClass 3000;
BA_REL_ "GenSigTimeoutTime" BU_SG_REL_ DACU SG_ 783 FLRObj00_ObjClass 100;
BA_REL_ "GenSigFirstTimeoutTime" BU_SG_REL_ DACU SG_ 783 FLRObj00_LongExtBkVar 3000;
BA_REL_ "GenSigTimeoutTime" BU_SG_REL_ DACU SG_ 783 FLRObj00_LongExtBkVar 100;
BA_REL_ "GenSigFirstTimeoutTime" BU_SG_REL_ DACU SG_ 783 FLRObj00_ExistConf 3000;
BA_REL_ "GenSigTimeoutTime" BU_SG_REL_ DACU SG_ 783 FLRObj00_ExistConf 100;
BA_REL_ "GenSigFirstTimeoutTime" BU_SG_REL_ DACU SG_ 783 FLRObj00_LatVelVar 3000;
BA_REL_ "GenSigTimeoutTime" BU_SG_REL_ DACU SG_ 783 FLRObj00_LatVelVar 100;
BA_REL_ "GenSigFirstTimeoutTime" BU_SG_REL_ DACU SG_ 783 FLRObj00_CoastIndex 3000;
BA_REL_ "GenSigTimeoutTime" BU_SG_REL_ DACU SG_ 783 FLRObj00_CoastIndex 100;
BA_REL_ "GenSigFirstTimeoutTime" BU_SG_REL_ DACU SG_ 783 FLRObj00_ObstacleConfRestricted 3000;
BA_REL_ "GenSigTimeoutTime" BU_SG_REL_ DACU SG_ 783 FLRObj00_ObstacleConfRestricted 100;
BA_REL_ "GenSigFirstTimeoutTime" BU_SG_REL_ DACU SG_ 783 FLRObj00_TrackStatus 3000;
BA_REL_ "GenSigTimeoutTime" BU_SG_REL_ DACU SG_ 783 FLRObj00_TrackStatus 100;
BA_REL_ "GenSigFirstTimeoutTime" BU_SG_REL_ DACU SG_ 783 FLRObj00_LatVel 3000;
BA_REL_ "GenSigTimeoutTime" BU_SG_REL_ DACU SG_ 783 FLRObj00_LatVel 100;
BA_REL_ "GenSigFirstTimeoutTime" BU_SG_REL_ DACU SG_ 783 FLRObj00_LongAcc 3000;
BA_REL_ "GenSigTimeoutTime" BU_SG_REL_ DACU SG_ 783 FLRObj00_LongAcc 100;
BA_REL_ "GenSigFirstTimeoutTime" BU_SG_REL_ DACU SG_ 783 FLRObj00_CRC 3000;
BA_REL_ "GenSigTimeoutTime" BU_SG_REL_ DACU SG_ 783 FLRObj00_CRC 100;
BA_REL_ "GenSigFirstTimeoutTime" BU_SG_REL_ DACU SG_ 783 FLRObj00_Heading 3000;
BA_REL_ "GenSigTimeoutTime" BU_SG_REL_ DACU SG_ 783 FLRObj00_Heading 100;
BA_REL_ "GenSigFirstTimeoutTime" BU_SG_REL_ DACU SG_ 783 FLRObj00_ObjDynClassRestricted 3000;
BA_REL_ "GenSigTimeoutTime" BU_SG_REL_ DACU SG_ 783 FLRObj00_ObjDynClassRestricted 100;
BA_REL_ "GenSigFirstTimeoutTime" BU_SG_REL_ DACU SG_ 783 FLRObj00_HeadingVar 3000;
BA_REL_ "GenSigTimeoutTime" BU_SG_REL_ DACU SG_ 783 FLRObj00_HeadingVar 100;
BA_REL_ "GenSigFirstTimeoutTime" BU_SG_REL_ DACU SG_ 783 FLRObj00_LatAccVar 3000;
BA_REL_ "GenSigTimeoutTime" BU_SG_REL_ DACU SG_ 783 FLRObj00_LatAccVar 100;
BA_REL_ "GenSigFirstTimeoutTime" BU_SG_REL_ DACU SG_ 783 FLRObj00_LatExtRtVar 3000;
BA_REL_ "GenSigTimeoutTime" BU_SG_REL_ DACU SG_ 783 FLRObj00_LatExtRtVar 100;
BA_REL_ "GenSigFirstTimeoutTime" BU_SG_REL_ DACU SG_ 783 FLRObj00_LatExtLeftVar 3000;
BA_REL_ "GenSigTimeoutTime" BU_SG_REL_ DACU SG_ 783 FLRObj00_LatExtLeftVar 100;
BA_REL_ "GenSigFirstTimeoutTime" BU_SG_REL_ DACU SG_ 783 FLRObj00_Counter 3000;
BA_REL_ "GenSigTimeoutTime" BU_SG_REL_ DACU SG_ 783 FLRObj00_Counter 100;
BA_REL_ "GenSigFirstTimeoutTime" BU_SG_REL_ DACU SG_ 860 LeftRoadBoundary_CoastIndex 3000;
BA_REL_ "GenSigTimeoutTime" BU_SG_REL_ DACU SG_ 860 LeftRoadBoundary_CoastIndex 100;
BA_REL_ "GenSigFirstTimeoutTime" BU_SG_REL_ DACU SG_ 860 LeftRoadBoundary_DxStart 3000;
BA_REL_ "GenSigTimeoutTime" BU_SG_REL_ DACU SG_ 860 LeftRoadBoundary_DxStart 100;
BA_REL_ "GenSigFirstTimeoutTime" BU_SG_REL_ DACU SG_ 860 LeftRoadBoundary_LifeTime 3000;
BA_REL_ "GenSigTimeoutTime" BU_SG_REL_ DACU SG_ 860 LeftRoadBoundary_LifeTime 100;
BA_REL_ "GenSigFirstTimeoutTime" BU_SG_REL_ DACU SG_ 860 LeftRoadBoundary_TimeStamp 3000;
BA_REL_ "GenSigTimeoutTime" BU_SG_REL_ DACU SG_ 860 LeftRoadBoundary_TimeStamp 100;
BA_REL_ "GenSigFirstTimeoutTime" BU_SG_REL_ DACU SG_ 860 LeftRoadBoundary_HeadingAngle 3000;
BA_REL_ "GenSigTimeoutTime" BU_SG_REL_ DACU SG_ 860 LeftRoadBoundary_HeadingAngle 100;
BA_REL_ "GenSigFirstTimeoutTime" BU_SG_REL_ DACU SG_ 860 LeftRoadBoundary_Curvature 3000;
BA_REL_ "GenSigTimeoutTime" BU_SG_REL_ DACU SG_ 860 LeftRoadBoundary_Curvature 100;
BA_REL_ "GenSigFirstTimeoutTime" BU_SG_REL_ DACU SG_ 860 LeftRoadBoundary_CRC 3000;
BA_REL_ "GenSigTimeoutTime" BU_SG_REL_ DACU SG_ 860 LeftRoadBoundary_CRC 100;
BA_REL_ "GenSigFirstTimeoutTime" BU_SG_REL_ DACU SG_ 860 LeftRoadBoundary_CurvatureRate 3000;
BA_REL_ "GenSigTimeoutTime" BU_SG_REL_ DACU SG_ 860 LeftRoadBoundary_CurvatureRate 100;
BA_REL_ "GenSigFirstTimeoutTime" BU_SG_REL_ DACU SG_ 860 LeftRoadBoundary_Type 3000;
BA_REL_ "GenSigTimeoutTime" BU_SG_REL_ DACU SG_ 860 LeftRoadBoundary_Type 100;
BA_REL_ "GenSigFirstTimeoutTime" BU_SG_REL_ DACU SG_ 860 LeftRoadBoundary_LatDistVar 3000;
BA_REL_ "GenSigTimeoutTime" BU_SG_REL_ DACU SG_ 860 LeftRoadBoundary_LatDistVar 100;
BA_REL_ "GenSigFirstTimeoutTime" BU_SG_REL_ DACU SG_ 860 LeftRoadBoundary_TrackStatus 3000;
BA_REL_ "GenSigTimeoutTime" BU_SG_REL_ DACU SG_ 860 LeftRoadBoundary_TrackStatus 100;
BA_REL_ "GenSigFirstTimeoutTime" BU_SG_REL_ DACU SG_ 860 LeftRoadBoundary_Counter 3000;
BA_REL_ "GenSigTimeoutTime" BU_SG_REL_ DACU SG_ 860 LeftRoadBoundary_Counter 100;
BA_REL_ "GenSigFirstTimeoutTime" BU_SG_REL_ DACU SG_ 860 LeftRoadBoundary_LatDist 3000;
BA_REL_ "GenSigTimeoutTime" BU_SG_REL_ DACU SG_ 860 LeftRoadBoundary_LatDist 100;
BA_REL_ "GenSigFirstTimeoutTime" BU_SG_REL_ DACU SG_ 860 LeftRoadBoundary_Confidence 3000;
BA_REL_ "GenSigTimeoutTime" BU_SG_REL_ DACU SG_ 860 LeftRoadBoundary_Confidence 100;
BA_REL_ "GenSigFirstTimeoutTime" BU_SG_REL_ DACU SG_ 860 LeftRoadBoundary_DxEnd 3000;
BA_REL_ "GenSigTimeoutTime" BU_SG_REL_ DACU SG_ 860 LeftRoadBoundary_DxEnd 100;
BA_REL_ "GenSigFirstTimeoutTime" BU_SG_REL_ DACU SG_ 858 FLREgoAssumpt_EgoRoadEnd 3000;
BA_REL_ "GenSigTimeoutTime" BU_SG_REL_ DACU SG_ 858 FLREgoAssumpt_EgoRoadEnd 300;
BA_REL_ "GenSigFirstTimeoutTime" BU_SG_REL_ DACU SG_ 858 FLREgoAssumpt_EgoLongAcc 3000;
BA_REL_ "GenSigTimeoutTime" BU_SG_REL_ DACU SG_ 858 FLREgoAssumpt_EgoLongAcc 300;
BA_REL_ "GenSigFirstTimeoutTime" BU_SG_REL_ DACU SG_ 858 FLREgoAssumpt_VelCorrFactor 3000;
BA_REL_ "GenSigTimeoutTime" BU_SG_REL_ DACU SG_ 858 FLREgoAssumpt_VelCorrFactor 300;
BA_REL_ "GenSigFirstTimeoutTime" BU_SG_REL_ DACU SG_ 858 FLREgoAssumpt_EgoRoadCurvRate 3000;
BA_REL_ "GenSigTimeoutTime" BU_SG_REL_ DACU SG_ 858 FLREgoAssumpt_EgoRoadCurvRate 300;
BA_REL_ "GenSigFirstTimeoutTime" BU_SG_REL_ DACU SG_ 858 FLREgoAssumpt_TimeStamp 3000;
BA_REL_ "GenSigTimeoutTime" BU_SG_REL_ DACU SG_ 858 FLREgoAssumpt_TimeStamp 300;
BA_REL_ "GenSigFirstTimeoutTime" BU_SG_REL_ DACU SG_ 858 FLREgoAssumpt_EgoYawRate 3000;
BA_REL_ "GenSigTimeoutTime" BU_SG_REL_ DACU SG_ 858 FLREgoAssumpt_EgoYawRate 300;
BA_REL_ "GenSigFirstTimeoutTime" BU_SG_REL_ DACU SG_ 858 FLREgoAssumpt_EgoRoadHeading 3000;
BA_REL_ "GenSigTimeoutTime" BU_SG_REL_ DACU SG_ 858 FLREgoAssumpt_EgoRoadHeading 300;
BA_REL_ "GenSigFirstTimeoutTime" BU_SG_REL_ DACU SG_ 858 FLREgoAssumpt_EgoRoadCurvature 3000;
BA_REL_ "GenSigTimeoutTime" BU_SG_REL_ DACU SG_ 858 FLREgoAssumpt_EgoRoadCurvature 300;
BA_REL_ "GenSigFirstTimeoutTime" BU_SG_REL_ DACU SG_ 858 FLREgoAssumpt_EgoLongVel 3000;
BA_REL_ "GenSigTimeoutTime" BU_SG_REL_ DACU SG_ 858 FLREgoAssumpt_EgoLongVel 300;
BA_REL_ "GenSigFirstTimeoutTime" BU_SG_REL_ DACU SG_ 512 FwdSensingRadarStat_CRC 4800;
BA_REL_ "GenSigTimeoutTime" BU_SG_REL_ DACU SG_ 512 FwdSensingRadarStat_CRC 1200;
BA_REL_ "GenSigFirstTimeoutTime" BU_SG_REL_ DACU SG_ 512 FwdSensingRadarStat_TimeSynch 4800;
BA_REL_ "GenSigTimeoutTime" BU_SG_REL_ DACU SG_ 512 FwdSensingRadarStat_TimeSynch 1200;
BA_REL_ "GenSigFirstTimeoutTime" BU_SG_REL_ DACU SG_ 512 FwdRdr_CalibPausedYaw 4800;
BA_REL_ "GenSigTimeoutTime" BU_SG_REL_ DACU SG_ 512 FwdRdr_CalibPausedYaw 1200;
BA_REL_ "GenSigFirstTimeoutTime" BU_SG_REL_ DACU SG_ 512 FwdRadarStatus 4800;
BA_REL_ "GenSigTimeoutTime" BU_SG_REL_ DACU SG_ 512 FwdRadarStatus 1200;
BA_REL_ "GenSigFirstTimeoutTime" BU_SG_REL_ DACU SG_ 512 FwdRdr_CalibState 4800;
BA_REL_ "GenSigTimeoutTime" BU_SG_REL_ DACU SG_ 512 FwdRdr_CalibState 1200;
BA_REL_ "GenSigFirstTimeoutTime" BU_SG_REL_ DACU SG_ 512 FwdRdr_CalibPausedAcc 4800;
BA_REL_ "GenSigTimeoutTime" BU_SG_REL_ DACU SG_ 512 FwdRdr_CalibPausedAcc 1200;
BA_REL_ "GenSigFirstTimeoutTime" BU_SG_REL_ DACU SG_ 512 FwdSensingRadarStat_Counter 4800;
BA_REL_ "GenSigTimeoutTime" BU_SG_REL_ DACU SG_ 512 FwdSensingRadarStat_Counter 1200;
BA_REL_ "GenSigFirstTimeoutTime" BU_SG_REL_ DACU SG_ 512 FwdRadarStatus2_CRC 4800;
BA_REL_ "GenSigTimeoutTime" BU_SG_REL_ DACU SG_ 512 FwdRadarStatus2_CRC 1200;
BA_REL_ "GenSigFirstTimeoutTime" BU_SG_REL_ DACU SG_ 512 FwdRdr_CalibPausedSpeed 4800;
BA_REL_ "GenSigTimeoutTime" BU_SG_REL_ DACU SG_ 512 FwdRdr_CalibPausedSpeed 1200;
BA_REL_ "GenSigFirstTimeoutTime" BU_SG_REL_ DACU SG_ 512 FwdRadarStatus2_Status 4800;
BA_REL_ "GenSigTimeoutTime" BU_SG_REL_ DACU SG_ 512 FwdRadarStatus2_Status 1200;
BA_REL_ "GenSigFirstTimeoutTime" BU_SG_REL_ DACU SG_ 512 FwdSensingRadarStat_DecalDetect 4800;
BA_REL_ "GenSigTimeoutTime" BU_SG_REL_ DACU SG_ 512 FwdSensingRadarStat_DecalDetect 1200;
BA_REL_ "GenSigFirstTimeoutTime" BU_SG_REL_ DACU SG_ 512 FwdRdr_CalibProgress 4800;
BA_REL_ "GenSigTimeoutTime" BU_SG_REL_ DACU SG_ 512 FwdRdr_CalibProgress 1200;
BA_REL_ "GenSigFirstTimeoutTime" BU_SG_REL_ DACU SG_ 512 FwdRadarStatus2_SqC 4800;
BA_REL_ "GenSigTimeoutTime" BU_SG_REL_ DACU SG_ 512 FwdRadarStatus2_SqC 1200;
BA_REL_ "GenSigFirstTimeoutTime" BU_SG_REL_ DACU SG_ 512 FwdSensingRadarStat_TargetDetect 4800;
BA_REL_ "GenSigTimeoutTime" BU_SG_REL_ DACU SG_ 512 FwdSensingRadarStat_TargetDetect 1200;
BA_REL_ "GenSigFirstTimeoutTime" BU_SG_REL_ DACU SG_ 512 FwdSensingRadarStat_BarrierDetec 4800;
BA_REL_ "GenSigTimeoutTime" BU_SG_REL_ DACU SG_ 512 FwdSensingRadarStat_BarrierDetec 1200;
BA_REL_ "GenSigFirstTimeoutTime" BU_SG_REL_ DACU SG_ 1527 DiagFaultStat_FLR_DtcIdB 24000;
BA_REL_ "GenSigTimeoutTime" BU_SG_REL_ DACU SG_ 1527 DiagFaultStat_FLR_DtcIdB 6000;
BA_REL_ "GenSigFirstTimeoutTime" BU_SG_REL_ DACU SG_ 1527 DiagFaultStat_FLR_FailTA 24000;
BA_REL_ "GenSigTimeoutTime" BU_SG_REL_ DACU SG_ 1527 DiagFaultStat_FLR_FailTA 6000;
BA_REL_ "GenSigFirstTimeoutTime" BU_SG_REL_ DACU SG_ 1527 DiagFaultStat_FLR_EcuAdr 24000;
BA_REL_ "GenSigTimeoutTime" BU_SG_REL_ DACU SG_ 1527 DiagFaultStat_FLR_EcuAdr 6000;
BA_REL_ "GenSigFirstTimeoutTime" BU_SG_REL_ DACU SG_ 1527 DiagFaultStat_FLR_DtcIdA 24000;
BA_REL_ "GenSigTimeoutTime" BU_SG_REL_ DACU SG_ 1527 DiagFaultStat_FLR_DtcIdA 6000;
BA_REL_ "GenSigFirstTimeoutTime" BU_SG_REL_ DACU SG_ 1527 DiagFaultStat_FLR_FailTB 24000;
BA_REL_ "GenSigTimeoutTime" BU_SG_REL_ DACU SG_ 1527 DiagFaultStat_FLR_FailTB 6000;
BA_REL_ "GenSigFirstTimeoutTime" BU_SG_REL_ FLR2 SG_ 279 EgoPathPrediction_Curvature 3000;
BA_REL_ "GenSigTimeoutTime" BU_SG_REL_ FLR2 SG_ 279 EgoPathPrediction_Curvature 600;
BA_REL_ "GenSigFirstTimeoutTime" BU_SG_REL_ FLR2 SG_ 279 EgoPathPrediction_HeadingAngle 3000;
BA_REL_ "GenSigTimeoutTime" BU_SG_REL_ FLR2 SG_ 279 EgoPathPrediction_HeadingAngle 600;
BA_REL_ "GenSigFirstTimeoutTime" BU_SG_REL_ FLR2 SG_ 279 EgoPathPrediction_CurvatureRate 3000;
BA_REL_ "GenSigTimeoutTime" BU_SG_REL_ FLR2 SG_ 279 EgoPathPrediction_CurvatureRate 600;
BA_REL_ "GenSigFirstTimeoutTime" BU_SG_REL_ FLR2 SG_ 279 EgoPathPrediction_ConfCoeffA1 3000;
BA_REL_ "GenSigTimeoutTime" BU_SG_REL_ FLR2 SG_ 279 EgoPathPrediction_ConfCoeffA1 600;
BA_REL_ "GenSigFirstTimeoutTime" BU_SG_REL_ FLR2 SG_ 279 EgoPathPrediction_DxEnd 3000;
BA_REL_ "GenSigTimeoutTime" BU_SG_REL_ FLR2 SG_ 279 EgoPathPrediction_DxEnd 600;
BA_REL_ "GenSigFirstTimeoutTime" BU_SG_REL_ FLR2 SG_ 279 EgoPathPrediction_ConfCoeffA3 3000;
BA_REL_ "GenSigTimeoutTime" BU_SG_REL_ FLR2 SG_ 279 EgoPathPrediction_ConfCoeffA3 600;
BA_REL_ "GenSigFirstTimeoutTime" BU_SG_REL_ FLR2 SG_ 279 EgoPathPrediction_ConfCoeffA0 3000;
BA_REL_ "GenSigTimeoutTime" BU_SG_REL_ FLR2 SG_ 279 EgoPathPrediction_ConfCoeffA0 600;
BA_REL_ "GenSigFirstTimeoutTime" BU_SG_REL_ FLR2 SG_ 279 EgoPathPrediction_ConfCoeffA2 3000;
BA_REL_ "GenSigTimeoutTime" BU_SG_REL_ FLR2 SG_ 279 EgoPathPrediction_ConfCoeffA2 600;
BA_REL_ "GenSigFirstTimeoutTime" BU_SG_REL_ FLR2 SG_ 275 EgoMotionXYplane_LongMotDirConf 3000;
BA_REL_ "GenSigTimeoutTime" BU_SG_REL_ FLR2 SG_ 275 EgoMotionXYplane_LongMotDirConf 100;
BA_REL_ "GenSigFirstTimeoutTime" BU_SG_REL_ FLR2 SG_ 275 EgoMotionXYplane_LongSpeed 3000;
BA_REL_ "GenSigTimeoutTime" BU_SG_REL_ FLR2 SG_ 275 EgoMotionXYplane_LongSpeed 100;
BA_REL_ "GenSigFirstTimeoutTime" BU_SG_REL_ FLR2 SG_ 275 EgoMotionXYplane_EffectiveWheelB 3000;
BA_REL_ "GenSigTimeoutTime" BU_SG_REL_ FLR2 SG_ 275 EgoMotionXYplane_EffectiveWheelB 100;
BA_REL_ "GenSigFirstTimeoutTime" BU_SG_REL_ FLR2 SG_ 275 EgoMotionXYplane_LatAccVariance 3000;
BA_REL_ "GenSigTimeoutTime" BU_SG_REL_ FLR2 SG_ 275 EgoMotionXYplane_LatAccVariance 100;
BA_REL_ "GenSigFirstTimeoutTime" BU_SG_REL_ FLR2 SG_ 275 EgoMotionXYplane_YawRateVariance 3000;
BA_REL_ "GenSigTimeoutTime" BU_SG_REL_ FLR2 SG_ 275 EgoMotionXYplane_YawRateVariance 100;
BA_REL_ "GenSigFirstTimeoutTime" BU_SG_REL_ FLR2 SG_ 275 EgoMotionXYplane_LateralSpeed 3000;
BA_REL_ "GenSigTimeoutTime" BU_SG_REL_ FLR2 SG_ 275 EgoMotionXYplane_LateralSpeed 100;
BA_REL_ "GenSigFirstTimeoutTime" BU_SG_REL_ FLR2 SG_ 275 EgoMotionXYplane_LongSpeedVar 3000;
BA_REL_ "GenSigTimeoutTime" BU_SG_REL_ FLR2 SG_ 275 EgoMotionXYplane_LongSpeedVar 100;
BA_REL_ "GenSigFirstTimeoutTime" BU_SG_REL_ FLR2 SG_ 275 EgoMotionXYplane_LateralAcc 3000;
BA_REL_ "GenSigTimeoutTime" BU_SG_REL_ FLR2 SG_ 275 EgoMotionXYplane_LateralAcc 100;
BA_REL_ "GenSigFirstTimeoutTime" BU_SG_REL_ FLR2 SG_ 275 EgoMotionXYplane_LongMotionDir 3000;
BA_REL_ "GenSigTimeoutTime" BU_SG_REL_ FLR2 SG_ 275 EgoMotionXYplane_LongMotionDir 100;
BA_REL_ "GenSigFirstTimeoutTime" BU_SG_REL_ FLR2 SG_ 275 EgoMotionXYplane_LatencyEst 3000;
BA_REL_ "GenSigTimeoutTime" BU_SG_REL_ FLR2 SG_ 275 EgoMotionXYplane_LatencyEst 100;
BA_REL_ "GenSigFirstTimeoutTime" BU_SG_REL_ FLR2 SG_ 275 EgoMotionXYplane_LongAcc 3000;
BA_REL_ "GenSigTimeoutTime" BU_SG_REL_ FLR2 SG_ 275 EgoMotionXYplane_LongAcc 100;
BA_REL_ "GenSigFirstTimeoutTime" BU_SG_REL_ FLR2 SG_ 275 EgoMotionXYplane_Counter 3000;
BA_REL_ "GenSigTimeoutTime" BU_SG_REL_ FLR2 SG_ 275 EgoMotionXYplane_Counter 100;
BA_REL_ "GenSigFirstTimeoutTime" BU_SG_REL_ FLR2 SG_ 275 EgoMotionXYplane_Curvature 3000;
BA_REL_ "GenSigTimeoutTime" BU_SG_REL_ FLR2 SG_ 275 EgoMotionXYplane_Curvature 100;
BA_REL_ "GenSigFirstTimeoutTime" BU_SG_REL_ FLR2 SG_ 275 EgoMotionXYplane_CRC 3000;
BA_REL_ "GenSigTimeoutTime" BU_SG_REL_ FLR2 SG_ 275 EgoMotionXYplane_CRC 100;
BA_REL_ "GenSigFirstTimeoutTime" BU_SG_REL_ FLR2 SG_ 275 EgoMotionXYplane_ReferencePointX 3000;
BA_REL_ "GenSigTimeoutTime" BU_SG_REL_ FLR2 SG_ 275 EgoMotionXYplane_ReferencePointX 100;
BA_REL_ "GenSigFirstTimeoutTime" BU_SG_REL_ FLR2 SG_ 275 EgoMotionXYplane_LongAccVariance 3000;
BA_REL_ "GenSigTimeoutTime" BU_SG_REL_ FLR2 SG_ 275 EgoMotionXYplane_LongAccVariance 100;
BA_REL_ "GenSigFirstTimeoutTime" BU_SG_REL_ FLR2 SG_ 275 EgoMotionXYplane_YawRateComp 3000;
BA_REL_ "GenSigTimeoutTime" BU_SG_REL_ FLR2 SG_ 275 EgoMotionXYplane_YawRateComp 100;
BA_REL_ "GenSigFirstTimeoutTime" BU_SG_REL_ FLR2 SG_ 275 EgoMotionXYplane_ChassisDynPitch 3000;
BA_REL_ "GenSigTimeoutTime" BU_SG_REL_ FLR2 SG_ 275 EgoMotionXYplane_ChassisDynPitch 100;
BA_REL_ "GenSigFirstTimeoutTime" BU_SG_REL_ FLR2 SG_ 275 EgoMotionXYplane_LatSpeedVar 3000;
BA_REL_ "GenSigTimeoutTime" BU_SG_REL_ FLR2 SG_ 275 EgoMotionXYplane_LatSpeedVar 100;
BA_REL_ "GenSigFirstTimeoutTime" BU_SG_REL_ FLR2 SG_ 277 EgoMotionRaw_YCEngineActive 3000;
BA_REL_ "GenSigTimeoutTime" BU_SG_REL_ FLR2 SG_ 277 EgoMotionRaw_YCEngineActive 100;
BA_REL_ "GenSigFirstTimeoutTime" BU_SG_REL_ FLR2 SG_ 277 EgoMotionRaw_ASREngineA 3000;
BA_REL_ "GenSigTimeoutTime" BU_SG_REL_ FLR2 SG_ 277 EgoMotionRaw_ASREngineA 100;
BA_REL_ "GenSigFirstTimeoutTime" BU_SG_REL_ FLR2 SG_ 277 EgoMotionRaw_ASRBrakeA 3000;
BA_REL_ "GenSigTimeoutTime" BU_SG_REL_ FLR2 SG_ 277 EgoMotionRaw_ASRBrakeA 100;
BA_REL_ "GenSigFirstTimeoutTime" BU_SG_REL_ FLR2 SG_ 277 EgoMotionRaw_RelLvlRrAxleRight 3000;
BA_REL_ "GenSigTimeoutTime" BU_SG_REL_ FLR2 SG_ 277 EgoMotionRaw_RelLvlRrAxleRight 100;
BA_REL_ "GenSigFirstTimeoutTime" BU_SG_REL_ FLR2 SG_ 277 EgoMotionRaw_ROPBrakeActive 3000;
BA_REL_ "GenSigTimeoutTime" BU_SG_REL_ FLR2 SG_ 277 EgoMotionRaw_ROPBrakeActive 100;
BA_REL_ "GenSigFirstTimeoutTime" BU_SG_REL_ FLR2 SG_ 277 EgoMotionRaw_Counter 3000;
BA_REL_ "GenSigTimeoutTime" BU_SG_REL_ FLR2 SG_ 277 EgoMotionRaw_Counter 100;
BA_REL_ "GenSigFirstTimeoutTime" BU_SG_REL_ FLR2 SG_ 277 EgoMotionRaw_RelLvlRrAxleLeft 3000;
BA_REL_ "GenSigTimeoutTime" BU_SG_REL_ FLR2 SG_ 277 EgoMotionRaw_RelLvlRrAxleLeft 100;
BA_REL_ "GenSigFirstTimeoutTime" BU_SG_REL_ FLR2 SG_ 277 EgoMotionRaw_AccKckDwn 3000;
BA_REL_ "GenSigTimeoutTime" BU_SG_REL_ FLR2 SG_ 277 EgoMotionRaw_AccKckDwn 100;
BA_REL_ "GenSigFirstTimeoutTime" BU_SG_REL_ FLR2 SG_ 277 EgoMotionRaw_VDCFullyOperational 3000;
BA_REL_ "GenSigTimeoutTime" BU_SG_REL_ FLR2 SG_ 277 EgoMotionRaw_VDCFullyOperational 100;
BA_REL_ "GenSigFirstTimeoutTime" BU_SG_REL_ FLR2 SG_ 277 EgoMotionRaw_FrontWheelAngle 3000;
BA_REL_ "GenSigTimeoutTime" BU_SG_REL_ FLR2 SG_ 277 EgoMotionRaw_FrontWheelAngle 100;
BA_REL_ "GenSigFirstTimeoutTime" BU_SG_REL_ FLR2 SG_ 277 EgoMotionRaw_BrakePedalPosition 3000;
BA_REL_ "GenSigTimeoutTime" BU_SG_REL_ FLR2 SG_ 277 EgoMotionRaw_BrakePedalPosition 100;
BA_REL_ "GenSigFirstTimeoutTime" BU_SG_REL_ FLR2 SG_ 277 EgoMotionRaw_ABSOp 3000;
BA_REL_ "GenSigTimeoutTime" BU_SG_REL_ FLR2 SG_ 277 EgoMotionRaw_ABSOp 100;
BA_REL_ "GenSigFirstTimeoutTime" BU_SG_REL_ FLR2 SG_ 277 EgoMotionRaw_RAxleRightWSpeed 3000;
BA_REL_ "GenSigTimeoutTime" BU_SG_REL_ FLR2 SG_ 277 EgoMotionRaw_RAxleRightWSpeed 100;
BA_REL_ "GenSigFirstTimeoutTime" BU_SG_REL_ FLR2 SG_ 277 EgoMotionRaw_GrossCombVehWeight 3000;
BA_REL_ "GenSigTimeoutTime" BU_SG_REL_ FLR2 SG_ 277 EgoMotionRaw_GrossCombVehWeight 100;
BA_REL_ "GenSigFirstTimeoutTime" BU_SG_REL_ FLR2 SG_ 277 EgoMotionRaw_CRC 3000;
BA_REL_ "GenSigTimeoutTime" BU_SG_REL_ FLR2 SG_ 277 EgoMotionRaw_CRC 100;
BA_REL_ "GenSigFirstTimeoutTime" BU_SG_REL_ FLR2 SG_ 277 EgoMotionRaw_FrAxleRightWSpeed 3000;
BA_REL_ "GenSigTimeoutTime" BU_SG_REL_ FLR2 SG_ 277 EgoMotionRaw_FrAxleRightWSpeed 100;
BA_REL_ "GenSigFirstTimeoutTime" BU_SG_REL_ FLR2 SG_ 277 EgoMotionRaw_ABSActive 3000;
BA_REL_ "GenSigTimeoutTime" BU_SG_REL_ FLR2 SG_ 277 EgoMotionRaw_ABSActive 100;
BA_REL_ "GenSigFirstTimeoutTime" BU_SG_REL_ FLR2 SG_ 277 EgoMotionRaw_SteeringWheelAngle 3000;
BA_REL_ "GenSigTimeoutTime" BU_SG_REL_ FLR2 SG_ 277 EgoMotionRaw_SteeringWheelAngle 100;
BA_REL_ "GenSigFirstTimeoutTime" BU_SG_REL_ FLR2 SG_ 277 EgoMotionRaw_RelLvlFrAxleLeft 3000;
BA_REL_ "GenSigTimeoutTime" BU_SG_REL_ FLR2 SG_ 277 EgoMotionRaw_RelLvlFrAxleLeft 100;
BA_REL_ "GenSigFirstTimeoutTime" BU_SG_REL_ FLR2 SG_ 277 EgoMotionRaw_ROPEngineActive 3000;
BA_REL_ "GenSigTimeoutTime" BU_SG_REL_ FLR2 SG_ 277 EgoMotionRaw_ROPEngineActive 100;
BA_REL_ "GenSigFirstTimeoutTime" BU_SG_REL_ FLR2 SG_ 277 EgoMotionRaw_FrAxleLeftWSpeed 3000;
BA_REL_ "GenSigTimeoutTime" BU_SG_REL_ FLR2 SG_ 277 EgoMotionRaw_FrAxleLeftWSpeed 100;
BA_REL_ "GenSigFirstTimeoutTime" BU_SG_REL_ FLR2 SG_ 277 EgoMotionRaw_YCBrakeActive 3000;
BA_REL_ "GenSigTimeoutTime" BU_SG_REL_ FLR2 SG_ 277 EgoMotionRaw_YCBrakeActive 100;
BA_REL_ "GenSigFirstTimeoutTime" BU_SG_REL_ FLR2 SG_ 277 EgoMotionRaw_SteeringWheelRatio 3000;
BA_REL_ "GenSigTimeoutTime" BU_SG_REL_ FLR2 SG_ 277 EgoMotionRaw_SteeringWheelRatio 100;
BA_REL_ "GenSigFirstTimeoutTime" BU_SG_REL_ FLR2 SG_ 277 EgoMotionRaw_AccPedalPos 3000;
BA_REL_ "GenSigTimeoutTime" BU_SG_REL_ FLR2 SG_ 277 EgoMotionRaw_AccPedalPos 100;
BA_REL_ "GenSigFirstTimeoutTime" BU_SG_REL_ FLR2 SG_ 277 EgoMotionRaw_RelLvlFrAxleRight 3000;
BA_REL_ "GenSigTimeoutTime" BU_SG_REL_ FLR2 SG_ 277 EgoMotionRaw_RelLvlFrAxleRight 100;
BA_REL_ "GenSigFirstTimeoutTime" BU_SG_REL_ FLR2 SG_ 277 EgoMotionRaw_RAxleLeftWSpeed 3000;
BA_REL_ "GenSigTimeoutTime" BU_SG_REL_ FLR2 SG_ 277 EgoMotionRaw_RAxleLeftWSpeed 100;
BA_REL_ "GenSigFirstTimeoutTime" BU_SG_REL_ FLR2 SG_ 277 EgoMotionRaw_TrailerConStatus 3000;
BA_REL_ "GenSigTimeoutTime" BU_SG_REL_ FLR2 SG_ 277 EgoMotionRaw_TrailerConStatus 100;
BA_REL_ "GenSigFirstTimeoutTime" BU_SG_REL_ HUA SG_ 333 HUALEDCtrl06_Orange 3000;
BA_REL_ "GenSigTimeoutTime" BU_SG_REL_ HUA SG_ 333 HUALEDCtrl06_Orange 100;
BA_REL_ "GenSigFirstTimeoutTime" BU_SG_REL_ HUA SG_ 333 HUALEDCtrl04_Orange 3000;
BA_REL_ "GenSigTimeoutTime" BU_SG_REL_ HUA SG_ 333 HUALEDCtrl04_Orange 100;
BA_REL_ "GenSigFirstTimeoutTime" BU_SG_REL_ HUA SG_ 333 HUALEDCtrl04_Red 3000;
BA_REL_ "GenSigTimeoutTime" BU_SG_REL_ HUA SG_ 333 HUALEDCtrl04_Red 100;
BA_REL_ "GenSigFirstTimeoutTime" BU_SG_REL_ HUA SG_ 333 HUALEDCtrl03_Orange 3000;
BA_REL_ "GenSigTimeoutTime" BU_SG_REL_ HUA SG_ 333 HUALEDCtrl03_Orange 100;
BA_REL_ "GenSigFirstTimeoutTime" BU_SG_REL_ HUA SG_ 333 HUASelfTestCtrl 3000;
BA_REL_ "GenSigTimeoutTime" BU_SG_REL_ HUA SG_ 333 HUASelfTestCtrl 100;
BA_REL_ "GenSigFirstTimeoutTime" BU_SG_REL_ HUA SG_ 333 HUALEDCtrl03_Red 3000;
BA_REL_ "GenSigTimeoutTime" BU_SG_REL_ HUA SG_ 333 HUALEDCtrl03_Red 100;
BA_REL_ "GenSigFirstTimeoutTime" BU_SG_REL_ HUA SG_ 333 HUALEDCtrl02_Orange 3000;
BA_REL_ "GenSigTimeoutTime" BU_SG_REL_ HUA SG_ 333 HUALEDCtrl02_Orange 100;
BA_REL_ "GenSigFirstTimeoutTime" BU_SG_REL_ HUA SG_ 333 HUALEDCtrl02_Red 3000;
BA_REL_ "GenSigTimeoutTime" BU_SG_REL_ HUA SG_ 333 HUALEDCtrl02_Red 100;
BA_REL_ "GenSigFirstTimeoutTime" BU_SG_REL_ HUA SG_ 333 HUALEDCtrl01_Orange 3000;
BA_REL_ "GenSigTimeoutTime" BU_SG_REL_ HUA SG_ 333 HUALEDCtrl01_Orange 100;
BA_REL_ "GenSigFirstTimeoutTime" BU_SG_REL_ HUA SG_ 333 HUALEDCtrl00_Red 3000;
BA_REL_ "GenSigTimeoutTime" BU_SG_REL_ HUA SG_ 333 HUALEDCtrl00_Red 100;
BA_REL_ "GenSigFirstTimeoutTime" BU_SG_REL_ HUA SG_ 333 HUALEDCtrl00_Orange 3000;
BA_REL_ "GenSigTimeoutTime" BU_SG_REL_ HUA SG_ 333 HUALEDCtrl00_Orange 100;
BA_REL_ "GenSigFirstTimeoutTime" BU_SG_REL_ HUA SG_ 333 HUALEDCtrl01_Red 3000;
BA_REL_ "GenSigTimeoutTime" BU_SG_REL_ HUA SG_ 333 HUALEDCtrl01_Red 100;
BA_REL_ "GenSigFirstTimeoutTime" BU_SG_REL_ HUA SG_ 333 HUAFading_Fadingtime 3000;
BA_REL_ "GenSigTimeoutTime" BU_SG_REL_ HUA SG_ 333 HUAFading_Fadingtime 100;
BA_REL_ "GenSigFirstTimeoutTime" BU_SG_REL_ HUA SG_ 333 HUAFlashingFrequency 3000;
BA_REL_ "GenSigTimeoutTime" BU_SG_REL_ HUA SG_ 333 HUAFlashingFrequency 100;
BA_REL_ "GenSigFirstTimeoutTime" BU_SG_REL_ HUA SG_ 333 HUABrightnessMode 3000;
BA_REL_ "GenSigTimeoutTime" BU_SG_REL_ HUA SG_ 333 HUABrightnessMode 100;
BA_REL_ "GenSigFirstTimeoutTime" BU_SG_REL_ HUA SG_ 333 HUAFading_FadingCtrl 3000;
BA_REL_ "GenSigTimeoutTime" BU_SG_REL_ HUA SG_ 333 HUAFading_FadingCtrl 100;
BA_REL_ "GenSigFirstTimeoutTime" BU_SG_REL_ HUA SG_ 333 HUALEDCtrl05_Red 3000;
BA_REL_ "GenSigTimeoutTime" BU_SG_REL_ HUA SG_ 333 HUALEDCtrl05_Red 100;
BA_REL_ "GenSigFirstTimeoutTime" BU_SG_REL_ HUA SG_ 333 HUALEDCtrl05_Orange 3000;
BA_REL_ "GenSigTimeoutTime" BU_SG_REL_ HUA SG_ 333 HUALEDCtrl05_Orange 100;
BA_REL_ "GenSigFirstTimeoutTime" BU_SG_REL_ HUA SG_ 333 HUALEDCtrl06_Red 3000;
BA_REL_ "GenSigTimeoutTime" BU_SG_REL_ HUA SG_ 333 HUALEDCtrl06_Red 100;
BA_REL_ "GenSigFirstTimeoutTime" BU_SG_REL_ HUA SG_ 1077 HUAPowerDemand 3000;
BA_REL_ "GenSigTimeoutTime" BU_SG_REL_ HUA SG_ 1077 HUAPowerDemand 300;
BA_REL_ "GenSigFirstTimeoutTime" BU_SG_REL_ FLR2 SG_ 1077 TimeSynchStat_DACU 3000;
BA_REL_ "GenSigTimeoutTime" BU_SG_REL_ FLR2 SG_ 1077 TimeSynchStat_DACU 300;
BA_REL_ "GenSigFirstTimeoutTime" BU_SG_REL_ FLR2 SG_ 1077 FrontCameraDynPitch 3000;
BA_REL_ "GenSigTimeoutTime" BU_SG_REL_ FLR2 SG_ 1077 FrontCameraDynPitch 300;
BA_REL_ "GenSigFirstTimeoutTime" BU_SG_REL_ FLR2 SG_ 1077 FrontCameraDynRoll 3000;
BA_REL_ "GenSigTimeoutTime" BU_SG_REL_ FLR2 SG_ 1077 FrontCameraDynRoll 300;
BA_REL_ "GenSigFirstTimeoutTime" BU_SG_REL_ FLR2 SG_ 1077 FRadarLoggingTrigger 3000;
BA_REL_ "GenSigTimeoutTime" BU_SG_REL_ FLR2 SG_ 1077 FRadarLoggingTrigger 300;
BA_REL_ "GenSigFirstTimeoutTime" BU_SG_REL_ FLR2 SG_ 1543 VIN_DACU_Byte02 60000;
BA_REL_ "GenSigTimeoutTime" BU_SG_REL_ FLR2 SG_ 1543 VIN_DACU_Byte02 30000;
BA_REL_ "GenSigFirstTimeoutTime" BU_SG_REL_ FLR2 SG_ 1543 VIN_DACU_Byte09 60000;
BA_REL_ "GenSigTimeoutTime" BU_SG_REL_ FLR2 SG_ 1543 VIN_DACU_Byte09 30000;
BA_REL_ "GenSigFirstTimeoutTime" BU_SG_REL_ FLR2 SG_ 1543 VIN_DACU_Byte04 60000;
BA_REL_ "GenSigTimeoutTime" BU_SG_REL_ FLR2 SG_ 1543 VIN_DACU_Byte04 30000;
BA_REL_ "GenSigFirstTimeoutTime" BU_SG_REL_ FLR2 SG_ 1543 VIN_DACU_Byte07 60000;
BA_REL_ "GenSigTimeoutTime" BU_SG_REL_ FLR2 SG_ 1543 VIN_DACU_Byte07 30000;
BA_REL_ "GenSigFirstTimeoutTime" BU_SG_REL_ FLR2 SG_ 1543 VIN_DACU_Byte11 60000;
BA_REL_ "GenSigTimeoutTime" BU_SG_REL_ FLR2 SG_ 1543 VIN_DACU_Byte11 30000;
BA_REL_ "GenSigFirstTimeoutTime" BU_SG_REL_ FLR2 SG_ 1543 VIN_DACU_Byte06 60000;
BA_REL_ "GenSigTimeoutTime" BU_SG_REL_ FLR2 SG_ 1543 VIN_DACU_Byte06 30000;
BA_REL_ "GenSigFirstTimeoutTime" BU_SG_REL_ FLR2 SG_ 1543 VIN_DACU_Byte08 60000;
BA_REL_ "GenSigTimeoutTime" BU_SG_REL_ FLR2 SG_ 1543 VIN_DACU_Byte08 30000;
BA_REL_ "GenSigFirstTimeoutTime" BU_SG_REL_ FLR2 SG_ 1543 VIN_DACU_Byte15 60000;
BA_REL_ "GenSigTimeoutTime" BU_SG_REL_ FLR2 SG_ 1543 VIN_DACU_Byte15 30000;
BA_REL_ "GenSigFirstTimeoutTime" BU_SG_REL_ FLR2 SG_ 1543 VIN_DACU_Byte14 60000;
BA_REL_ "GenSigTimeoutTime" BU_SG_REL_ FLR2 SG_ 1543 VIN_DACU_Byte14 30000;
BA_REL_ "GenSigFirstTimeoutTime" BU_SG_REL_ FLR2 SG_ 1543 VIN_DACU_Byte16 60000;
BA_REL_ "GenSigTimeoutTime" BU_SG_REL_ FLR2 SG_ 1543 VIN_DACU_Byte16 30000;
BA_REL_ "GenSigFirstTimeoutTime" BU_SG_REL_ FLR2 SG_ 1543 VIN_DACU_Byte12 60000;
BA_REL_ "GenSigTimeoutTime" BU_SG_REL_ FLR2 SG_ 1543 VIN_DACU_Byte12 30000;
BA_REL_ "GenSigFirstTimeoutTime" BU_SG_REL_ FLR2 SG_ 1543 VIN_DACU_Byte01 60000;
BA_REL_ "GenSigTimeoutTime" BU_SG_REL_ FLR2 SG_ 1543 VIN_DACU_Byte01 30000;
BA_REL_ "GenSigFirstTimeoutTime" BU_SG_REL_ FLR2 SG_ 1543 VIN_DACU_Byte10 60000;
BA_REL_ "GenSigTimeoutTime" BU_SG_REL_ FLR2 SG_ 1543 VIN_DACU_Byte10 30000;
BA_REL_ "GenSigFirstTimeoutTime" BU_SG_REL_ FLR2 SG_ 1543 VIN_DACU_Byte03 60000;
BA_REL_ "GenSigTimeoutTime" BU_SG_REL_ FLR2 SG_ 1543 VIN_DACU_Byte03 30000;
BA_REL_ "GenSigFirstTimeoutTime" BU_SG_REL_ FLR2 SG_ 1543 VIN_DACU_Byte00 60000;
BA_REL_ "GenSigTimeoutTime" BU_SG_REL_ FLR2 SG_ 1543 VIN_DACU_Byte00 30000;
BA_REL_ "GenSigFirstTimeoutTime" BU_SG_REL_ FLR2 SG_ 1543 VIN_DACU_Byte05 60000;
BA_REL_ "GenSigTimeoutTime" BU_SG_REL_ FLR2 SG_ 1543 VIN_DACU_Byte05 30000;
BA_REL_ "GenSigFirstTimeoutTime" BU_SG_REL_ FLR2 SG_ 1543 VIN_DACU_Byte13 60000;
BA_REL_ "GenSigTimeoutTime" BU_SG_REL_ FLR2 SG_ 1543 VIN_DACU_Byte13 30000;
BA_REL_ "GenSigFirstTimeoutTime" BU_SG_REL_ FLR2 SG_ 1265 TachographLocalHourOffset 6000;
BA_REL_ "GenSigTimeoutTime" BU_SG_REL_ FLR2 SG_ 1265 TachographLocalHourOffset 1500;
BA_REL_ "GenSigFirstTimeoutTime" BU_SG_REL_ HUA SG_ 1265 VehicleMode 3000;
BA_REL_ "GenSigTimeoutTime" BU_SG_REL_ HUA SG_ 1265 VehicleMode 500;
BA_REL_ "GenSigFirstTimeoutTime" BU_SG_REL_ FLR2 SG_ 1265 VehicleMode 6000;
BA_REL_ "GenSigTimeoutTime" BU_SG_REL_ FLR2 SG_ 1265 VehicleMode 1500;
BA_REL_ "GenSigFirstTimeoutTime" BU_SG_REL_ FLR2 SG_ 1265 AmbientAirTemperature 6000;
BA_REL_ "GenSigTimeoutTime" BU_SG_REL_ FLR2 SG_ 1265 AmbientAirTemperature 1500;
BA_REL_ "GenSigFirstTimeoutTime" BU_SG_REL_ FLR2 SG_ 1265 DayUTC 6000;
BA_REL_ "GenSigTimeoutTime" BU_SG_REL_ FLR2 SG_ 1265 DayUTC 1500;
BA_REL_ "GenSigFirstTimeoutTime" BU_SG_REL_ FLR2 SG_ 1265 TotalVehicleDistanceHighRes 6000;
BA_REL_ "GenSigTimeoutTime" BU_SG_REL_ FLR2 SG_ 1265 TotalVehicleDistanceHighRes 1500;
BA_REL_ "GenSigFirstTimeoutTime" BU_SG_REL_ FLR2 SG_ 1265 TachographLocalMinuteOffset 6000;
BA_REL_ "GenSigTimeoutTime" BU_SG_REL_ FLR2 SG_ 1265 TachographLocalMinuteOffset 1500;
BA_REL_ "GenSigFirstTimeoutTime" BU_SG_REL_ FLR2 SG_ 1265 SecondsUTC 6000;
BA_REL_ "GenSigTimeoutTime" BU_SG_REL_ FLR2 SG_ 1265 SecondsUTC 1500;
BA_REL_ "GenSigFirstTimeoutTime" BU_SG_REL_ FLR2 SG_ 1265 YearUTC 6000;
BA_REL_ "GenSigTimeoutTime" BU_SG_REL_ FLR2 SG_ 1265 YearUTC 1500;
BA_REL_ "GenSigFirstTimeoutTime" BU_SG_REL_ FLR2 SG_ 1265 TrailerConnected 6000;
BA_REL_ "GenSigTimeoutTime" BU_SG_REL_ FLR2 SG_ 1265 TrailerConnected 1500;
BA_REL_ "GenSigFirstTimeoutTime" BU_SG_REL_ FLR2 SG_ 1265 MonthUTC 6000;
BA_REL_ "GenSigTimeoutTime" BU_SG_REL_ FLR2 SG_ 1265 MonthUTC 1500;
BA_REL_ "GenSigFirstTimeoutTime" BU_SG_REL_ FLR2 SG_ 1265 HoursUTC 6000;
BA_REL_ "GenSigTimeoutTime" BU_SG_REL_ FLR2 SG_ 1265 HoursUTC 1500;
BA_REL_ "GenSigFirstTimeoutTime" BU_SG_REL_ FLR2 SG_ 1265 PloughLampModeStatus 6000;
BA_REL_ "GenSigTimeoutTime" BU_SG_REL_ FLR2 SG_ 1265 PloughLampModeStatus 1500;
BA_REL_ "GenSigFirstTimeoutTime" BU_SG_REL_ FLR2 SG_ 1265 LaneChangeStatus 6000;
BA_REL_ "GenSigTimeoutTime" BU_SG_REL_ FLR2 SG_ 1265 LaneChangeStatus 1500;
BA_REL_ "GenSigFirstTimeoutTime" BU_SG_REL_ FLR2 SG_ 1265 WiperModeStatus 6000;
BA_REL_ "GenSigTimeoutTime" BU_SG_REL_ FLR2 SG_ 1265 WiperModeStatus 1500;
BA_REL_ "GenSigFirstTimeoutTime" BU_SG_REL_ FLR2 SG_ 1265 MinutesUTC 6000;
BA_REL_ "GenSigTimeoutTime" BU_SG_REL_ FLR2 SG_ 1265 MinutesUTC 1500;
BA_REL_ "GenSigFirstTimeoutTime" BU_SG_REL_ FLR2 SG_ 1265 FLRPowerDemand 6000;
BA_REL_ "GenSigTimeoutTime" BU_SG_REL_ FLR2 SG_ 1265 FLRPowerDemand 1500;
BA_REL_ "GenSigFirstTimeoutTime" BU_SG_REL_ FLR2 SG_ 1552 DACUSwVersion_Substring0 60000;
BA_REL_ "GenSigTimeoutTime" BU_SG_REL_ FLR2 SG_ 1552 DACUSwVersion_Substring0 60000;
BA_REL_ "GenSigFirstTimeoutTime" BU_SG_REL_ FLR2 SG_ 1552 DACUSwVersion_Substring6 60000;
BA_REL_ "GenSigTimeoutTime" BU_SG_REL_ FLR2 SG_ 1552 DACUSwVersion_Substring6 60000;
BA_REL_ "GenSigFirstTimeoutTime" BU_SG_REL_ FLR2 SG_ 1552 DACUSwVersion_Substring2 60000;
BA_REL_ "GenSigTimeoutTime" BU_SG_REL_ FLR2 SG_ 1552 DACUSwVersion_Substring2 60000;
BA_REL_ "GenSigFirstTimeoutTime" BU_SG_REL_ FLR2 SG_ 1552 DACUSwVersion_Substring5 60000;
BA_REL_ "GenSigTimeoutTime" BU_SG_REL_ FLR2 SG_ 1552 DACUSwVersion_Substring5 60000;
BA_REL_ "GenSigFirstTimeoutTime" BU_SG_REL_ FLR2 SG_ 1552 DACUSwVersion_Substring7 60000;
BA_REL_ "GenSigTimeoutTime" BU_SG_REL_ FLR2 SG_ 1552 DACUSwVersion_Substring7 60000;
BA_REL_ "GenSigFirstTimeoutTime" BU_SG_REL_ FLR2 SG_ 1552 DACUSwVersion_Substring1 60000;
BA_REL_ "GenSigTimeoutTime" BU_SG_REL_ FLR2 SG_ 1552 DACUSwVersion_Substring1 60000;
BA_REL_ "GenSigFirstTimeoutTime" BU_SG_REL_ FLR2 SG_ 1552 DACUSwVersion_Substring3 60000;
BA_REL_ "GenSigTimeoutTime" BU_SG_REL_ FLR2 SG_ 1552 DACUSwVersion_Substring3 60000;
BA_REL_ "GenSigFirstTimeoutTime" BU_SG_REL_ FLR2 SG_ 1552 DACUSwVersion_Substring4 60000;
BA_REL_ "GenSigTimeoutTime" BU_SG_REL_ FLR2 SG_ 1552 DACUSwVersion_Substring4 60000;
VAL_ 786 FLRObj03_ObjClass 15 "ObjClassFLR_NotAvailable" 14 "ObjClassFLR_Error" 13 "ObjClassFLR_Spare4" 12 "ObjClassFLR_MoisObject" 11 "ObjClassFLR_Motorcycle" 10 "ObjClassFLR_Bicycle" 9 "ObjClassFLR_UnidentifiedMovableObject" 8 "ObjClassFLR_UnidentifiedVRU" 7 "ObjClassFLR_UnidentifiedVehicle" 6 "ObjClassFLR_StaticObject" 5 "ObjClassFLR_Pedestrian" 4 "ObjClassFLR_2Wheeler" 3 "ObjClassFLR_HeavyVehicle" 2 "ObjClassFLR_Car" 1 "ObjClassFLR_Obstacle" 0 "ObjClassFLR_Undetermined" ;
VAL_ 786 FLRObj03_ObjDynClass 3 "ObjDynClass_Error" 2 "ObjDynClass_Movable" 1 "ObjDynClass_Stationary" 0 "ObjDynClass_Reserved" ;
VAL_ 786 FLRObj03_AsilLvl 3 "AsilLvl_NotAvailable" 2 "AsilLvl_Spare" 1 "AsilLvl_Asil" 0 "AsilLvl_QM" ;
VAL_ 786 FLRObj03_ObjDynClassRestricted 3 "ObjDynClass_Error" 2 "ObjDynClass_Movable" 1 "ObjDynClass_Stationary" 0 "ObjDynClass_Reserved" ;
VAL_ 786 FLRObj03_TrackStatus 7 "TrackStatus_NotAvailable" 6 "TrackStatus_Error" 5 "TrackStatus_Spare3" 4 "TrackStatus_Spare2" 3 "TrackStatus_Spare1" 2 "TrackStatus_Invalid" 1 "TrackStatus_Predicted" 0 "TrackStatus_Tracked" ;
VAL_ 785 FLRObj02_AsilLvl 3 "AsilLvl_NotAvailable" 2 "AsilLvl_Spare" 1 "AsilLvl_Asil" 0 "AsilLvl_QM" ;
VAL_ 785 FLRObj02_ObjDynClassRestricted 3 "ObjDynClass_Error" 2 "ObjDynClass_Movable" 1 "ObjDynClass_Stationary" 0 "ObjDynClass_Reserved" ;
VAL_ 785 FLRObj02_ObjClass 15 "ObjClassFLR_NotAvailable" 14 "ObjClassFLR_Error" 13 "ObjClassFLR_Spare4" 12 "ObjClassFLR_MoisObject" 11 "ObjClassFLR_Motorcycle" 10 "ObjClassFLR_Bicycle" 9 "ObjClassFLR_UnidentifiedMovableObject" 8 "ObjClassFLR_UnidentifiedVRU" 7 "ObjClassFLR_UnidentifiedVehicle" 6 "ObjClassFLR_StaticObject" 5 "ObjClassFLR_Pedestrian" 4 "ObjClassFLR_2Wheeler" 3 "ObjClassFLR_HeavyVehicle" 2 "ObjClassFLR_Car" 1 "ObjClassFLR_Obstacle" 0 "ObjClassFLR_Undetermined" ;
VAL_ 785 FLRObj02_TrackStatus 7 "TrackStatus_NotAvailable" 6 "TrackStatus_Error" 5 "TrackStatus_Spare3" 4 "TrackStatus_Spare2" 3 "TrackStatus_Spare1" 2 "TrackStatus_Invalid" 1 "TrackStatus_Predicted" 0 "TrackStatus_Tracked" ;
VAL_ 785 FLRObj02_ObjDynClass 3 "ObjDynClass_Error" 2 "ObjDynClass_Movable" 1 "ObjDynClass_Stationary" 0 "ObjDynClass_Reserved" ;
VAL_ 784 FLRObj01_AsilLvl 3 "AsilLvl_NotAvailable" 2 "AsilLvl_Spare" 1 "AsilLvl_Asil" 0 "AsilLvl_QM" ;
VAL_ 784 FLRObj01_ObjClass 15 "ObjClassFLR_NotAvailable" 14 "ObjClassFLR_Error" 13 "ObjClassFLR_Spare4" 12 "ObjClassFLR_MoisObject" 11 "ObjClassFLR_Motorcycle" 10 "ObjClassFLR_Bicycle" 9 "ObjClassFLR_UnidentifiedMovableObject" 8 "ObjClassFLR_UnidentifiedVRU" 7 "ObjClassFLR_UnidentifiedVehicle" 6 "ObjClassFLR_StaticObject" 5 "ObjClassFLR_Pedestrian" 4 "ObjClassFLR_2Wheeler" 3 "ObjClassFLR_HeavyVehicle" 2 "ObjClassFLR_Car" 1 "ObjClassFLR_Obstacle" 0 "ObjClassFLR_Undetermined" ;
VAL_ 784 FLRObj01_ObjDynClassRestricted 3 "ObjDynClass_Error" 2 "ObjDynClass_Movable" 1 "ObjDynClass_Stationary" 0 "ObjDynClass_Reserved" ;
VAL_ 784 FLRObj01_TrackStatus 7 "TrackStatus_NotAvailable" 6 "TrackStatus_Error" 5 "TrackStatus_Spare3" 4 "TrackStatus_Spare2" 3 "TrackStatus_Spare1" 2 "TrackStatus_Invalid" 1 "TrackStatus_Predicted" 0 "TrackStatus_Tracked" ;
VAL_ 784 FLRObj01_ObjDynClass 3 "ObjDynClass_Error" 2 "ObjDynClass_Movable" 1 "ObjDynClass_Stationary" 0 "ObjDynClass_Reserved" ;
VAL_ 783 FLRObj00_AsilLvl 3 "AsilLvl_NotAvailable" 2 "AsilLvl_Spare" 1 "AsilLvl_Asil" 0 "AsilLvl_QM" ;
VAL_ 783 FLRObj00_ObjDynClass 3 "ObjDynClass_Error" 2 "ObjDynClass_Movable" 1 "ObjDynClass_Stationary" 0 "ObjDynClass_Reserved" ;
VAL_ 783 FLRObj00_ObjClass 15 "ObjClassFLR_NotAvailable" 14 "ObjClassFLR_Error" 13 "ObjClassFLR_Spare4" 12 "ObjClassFLR_MoisObject" 11 "ObjClassFLR_Motorcycle" 10 "ObjClassFLR_Bicycle" 9 "ObjClassFLR_UnidentifiedMovableObject" 8 "ObjClassFLR_UnidentifiedVRU" 7 "ObjClassFLR_UnidentifiedVehicle" 6 "ObjClassFLR_StaticObject" 5 "ObjClassFLR_Pedestrian" 4 "ObjClassFLR_2Wheeler" 3 "ObjClassFLR_HeavyVehicle" 2 "ObjClassFLR_Car" 1 "ObjClassFLR_Obstacle" 0 "ObjClassFLR_Undetermined" ;
VAL_ 783 FLRObj00_TrackStatus 7 "TrackStatus_NotAvailable" 6 "TrackStatus_Error" 5 "TrackStatus_Spare3" 4 "TrackStatus_Spare2" 3 "TrackStatus_Spare1" 2 "TrackStatus_Invalid" 1 "TrackStatus_Predicted" 0 "TrackStatus_Tracked" ;
VAL_ 783 FLRObj00_ObjDynClassRestricted 3 "ObjDynClass_Error" 2 "ObjDynClass_Movable" 1 "ObjDynClass_Stationary" 0 "ObjDynClass_Reserved" ;
VAL_ 860 LeftRoadBoundary_Type 7 "RaisedEdgeType_NotAvailable" 6 "RaisedEdgeType_Error" 5 "RaisedEdgeType_Spare2" 4 "RaisedEdgeType_Spare1" 3 "RaisedEdgeType_Barrier" 2 "RaisedEdgeType_NonElevatedBoundary" 1 "RaisedEdgeType_ElevatedBoundary" 0 "RaisedEdgeType_Unknown" ;
VAL_ 860 LeftRoadBoundary_TrackStatus 7 "TrackStatus_NotAvailable" 6 "TrackStatus_Error" 5 "TrackStatus_Spare3" 4 "TrackStatus_Spare2" 3 "TrackStatus_Spare1" 2 "TrackStatus_Invalid" 1 "TrackStatus_Predicted" 0 "TrackStatus_Tracked" ;
VAL_ 512 FwdRdr_CalibPausedYaw 1 "FalseTrue1bit_True" 0 "FalseTrue1bit_False" ;
VAL_ 512 FwdRadarStatus 15 "RadarSensorStatus_NotAvailable" 14 "RadarSensorStatus_Error" 13 "RadarSensorStatus_TemporaryNotAvailable" 12 "RadarSensorStatus_Spare04" 11 "RadarSensorStatus_Spare03" 10 "RadarSensorStatus_Spare02" 9 "RadarSensorStatus_Spare01" 8 "RadarSensorStatus_Blinded" 7 "RadarSensorStatus_ShutDownCompleted" 6 "RadarSensorStatus_ShutDownInitiated" 5 "RadarSensorStatus_CalibrationOngoing" 4 "RadarSensorStatus_NotCalibrated" 3 "RadarSensorStatus_Misaligned" 2 "RadarSensorStatus_Blocked" 1 "RadarSensorStatus_WarmingUp" 0 "RadarSensorStatus_FullyOperational" ;
VAL_ 512 FwdRdr_CalibState 3 "CalibState_NotAvailable" 2 "CalibState_Failure" 1 "CalibState_Running" 0 "CalibState_Success" ;
VAL_ 512 FwdRdr_CalibPausedAcc 1 "FalseTrue1bit_True" 0 "FalseTrue1bit_False" ;
VAL_ 512 FwdRdr_CalibPausedSpeed 1 "FalseTrue1bit_True" 0 "FalseTrue1bit_False" ;
VAL_ 512 FwdRadarStatus2_Status 15 "RadarSensorStatus_NotAvailable" 14 "RadarSensorStatus_Error" 13 "RadarSensorStatus_TemporaryNotAvailable" 12 "RadarSensorStatus_Spare04" 11 "RadarSensorStatus_Spare03" 10 "RadarSensorStatus_Spare02" 9 "RadarSensorStatus_Spare01" 8 "RadarSensorStatus_Blinded" 7 "RadarSensorStatus_ShutDownCompleted" 6 "RadarSensorStatus_ShutDownInitiated" 5 "RadarSensorStatus_CalibrationOngoing" 4 "RadarSensorStatus_NotCalibrated" 3 "RadarSensorStatus_Misaligned" 2 "RadarSensorStatus_Blocked" 1 "RadarSensorStatus_WarmingUp" 0 "RadarSensorStatus_FullyOperational" ;
VAL_ 512 FwdSensingRadarStat_DecalDetect 7 "DecalibrationDetection_NotAvailable" 6 "DecalibrationDetection_Error" 5 "DecalibrationDetection_CalibrationNotVerified" 4 "DecalibrationDetection_Spare3" 3 "DecalibrationDetection_Spare2" 2 "DecalibrationDetection_Spare1" 1 "DecalibrationDetection_NotCalibrated" 0 "DecalibrationDetection_FullyCalibrated" ;
VAL_ 512 FwdSensingRadarStat_TargetDetect 7 "SensorStatus3bit_NotAvailable" 6 "SensorStatus3bit_Error" 5 "SensorStatus3bit_Spare2" 4 "SensorStatus3bit_Spare1" 3 "SensorStatus3bit_NotOperational" 2 "SensorStatus3bit_Initialisation" 1 "SensorStatus3bit_ReducedMode" 0 "SensorStatus3bit_FullyOperational" ;
VAL_ 512 FwdSensingRadarStat_BarrierDetec 7 "SensorStatus3bit_NotAvailable" 6 "SensorStatus3bit_Error" 5 "SensorStatus3bit_Spare2" 4 "SensorStatus3bit_Spare1" 3 "SensorStatus3bit_NotOperational" 2 "SensorStatus3bit_Initialisation" 1 "SensorStatus3bit_ReducedMode" 0 "SensorStatus3bit_FullyOperational" ;
VAL_ 275 EgoMotionXYplane_LongMotDirConf 15 "LongMotionDirConf_NotAvailable" 14 "LongMotionDirConf_Error" 13 "LongMotionDirConf_Spare5" 12 "LongMotionDirConf_Spare4" 11 "LongMotionDirConf_Spare3" 10 "LongMotionDirConf_Spare2" 9 "LongMotionDirConf_Spare1" 8 "LongMotionDirConf_MovingVeryHighConfidence" 7 "LongMotionDirConf_MovingHighConfidence" 6 "LongMotionDirConf_MovingMediumConfidence" 5 "LongMotionDirConf_MovingLowConfidence" 4 "LongMotionDirConf_StationaryLowConfidence" 3 "LongMotionDirConf_StationaryMediumConfidence" 2 "LongMotionDirConf_StationaryHighConfidence" 1 "LongMotionDirConf_StationaryVeryHighConfidence" 0 "LongMotionDirConf_StationaryVeryVeryHighConfidence" ;
VAL_ 275 EgoMotionXYplane_LongMotionDir 7 "LongMotionDirection_NotAvailable" 6 "LongMotionDirection_Error" 5 "LongMotionDirection_Spare3" 4 "LongMotionDirection_Spare2" 3 "LongMotionDirection_Undetermined" 2 "LongMotionDirection_Backward" 1 "LongMotionDirection_Forward" 0 "LongMotionDirection_Stationary" ;
VAL_ 277 EgoMotionRaw_YCEngineActive 3 "PassiveActive2_DontCareTakeNoAction" 2 "PassiveActive2_Reserved" 1 "PassiveActive2_Active" 0 "PassiveActive2_PassiveButInstalled" ;
VAL_ 277 EgoMotionRaw_ASREngineA 3 "PassiveActive2_DontCareTakeNoAction" 2 "PassiveActive2_Reserved" 1 "PassiveActive2_Active" 0 "PassiveActive2_PassiveButInstalled" ;
VAL_ 277 EgoMotionRaw_ASRBrakeA 3 "PassiveActive2_DontCareTakeNoAction" 2 "PassiveActive2_Reserved" 1 "PassiveActive2_Active" 0 "PassiveActive2_PassiveButInstalled" ;
VAL_ 277 EgoMotionRaw_ROPBrakeActive 3 "PassiveActive2_DontCareTakeNoAction" 2 "PassiveActive2_Reserved" 1 "PassiveActive2_Active" 0 "PassiveActive2_PassiveButInstalled" ;
VAL_ 277 EgoMotionRaw_AccKckDwn 3 "PassiveActive_NotAvailable" 2 "PassiveActive_Error" 1 "PassiveActive_Active" 0 "PassiveActive_Passive" ;
VAL_ 277 EgoMotionRaw_VDCFullyOperational 3 "FullyOperational_NotAvailable" 2 "FullyOperational_Reserved" 1 "FullyOperational_FullyOperational" 0 "FullyOperational_NotFullyOperational" ;
VAL_ 277 EgoMotionRaw_ABSOp 3 "FullyOperational_NotAvailable" 2 "FullyOperational_Reserved" 1 "FullyOperational_FullyOperational" 0 "FullyOperational_NotFullyOperational" ;
VAL_ 277 EgoMotionRaw_ABSActive 3 "AntiLockBrakingActive_NotAvailable" 2 "AntiLockBrakingActive_Reserved" 1 "AntiLockBrakingActive_ABSActive" 0 "AntiLockBrakingActive_ABSPassiveButInstalled" ;
VAL_ 277 EgoMotionRaw_ROPEngineActive 3 "PassiveActive2_DontCareTakeNoAction" 2 "PassiveActive2_Reserved" 1 "PassiveActive2_Active" 0 "PassiveActive2_PassiveButInstalled" ;
VAL_ 277 EgoMotionRaw_YCBrakeActive 3 "PassiveActive2_DontCareTakeNoAction" 2 "PassiveActive2_Reserved" 1 "PassiveActive2_Active" 0 "PassiveActive2_PassiveButInstalled" ;
VAL_ 277 EgoMotionRaw_TrailerConStatus 15 "TrailerConStatus_NotAvailableOrNotInstalled" 14 "TrailerConStatus_ErrorIndicator" 13 "TrailerConStatus_Unknown" 12 "TrailerConStatus_AtLeastOneSegmentConnectedNoAbs" 11 "TrailerConStatus_AtLeastOneSegmentConnected" 10 "TrailerConStatus_FiveOrMoreSegmentsConnectedNoAbs" 9 "TrailerConStatus_FourTrailerSegmentsConnectedNoAbs" 8 "TrailerConStatus_ThreeTrailerSegmentsConnectedNoAbs" 7 "TrailerConStatus_TwoTrailerSegmentsConnectedNoAbs" 6 "TrailerConStatus_OneTrailerSegmentConnectedNoAbs" 5 "TrailerConStatus_FiveOrMoreSegmentsConnected" 4 "TrailerConStatus_FourTrailerSegmentsConnected" 3 "TrailerConStatus_ThreeTrailerSegmentsConnected" 2 "TrailerConStatus_TwoTrailerSegmentsConnected" 1 "TrailerConStatus_OneTrailerSegmentConnected" 0 "TrailerConStatus_NoTrailerConnected" ;
VAL_ 333 HUASelfTestCtrl 3 "SelfTestCtrl_NotAvailable" 2 "SelfTestCtrl_Spare" 1 "SelfTestCtrl_RunSelfTest" 0 "SelfTestCtrl_DoNotRunSelfTest" ;
VAL_ 333 HUAFlashingFrequency 15 "HUAFlashingFrequency_NotAvailable" 14 "HUAFlashingFrequency_Error" 13 "HUAFlashingFrequency_Pattern13" 12 "HUAFlashingFrequency_Pattern12" 11 "HUAFlashingFrequency_Pattern11" 10 "HUAFlashingFrequency_Pattern10" 9 "HUAFlashingFrequency_Pattern9" 8 "HUAFlashingFrequency_Pattern8" 7 "HUAFlashingFrequency_Pattern7" 6 "HUAFlashingFrequency_Pattern6" 5 "HUAFlashingFrequency_Pattern5" 4 "HUAFlashingFrequency_Pattern4" 3 "HUAFlashingFrequency_Pattern3" 2 "HUAFlashingFrequency_Pattern2" 1 "HUAFlashingFrequency_Pattern1" 0 "HUAFlashingFrequency_NoFlashing" ;
VAL_ 1077 HUAPowerDemand 3 "OffOn_NotAvailable" 2 "OffOn_Error" 1 "OffOn_On" 0 "OffOn_Off" ;
VAL_ 1077 FRadarLoggingTrigger 7 "SensorLoggingTrigger_NotAvailable" 6 "SensorLoggingTrigger_Error" 5 "SensorLoggingTrigger_Trigger5" 4 "SensorLoggingTrigger_Trigger4" 3 "SensorLoggingTrigger_Trigger3" 2 "SensorLoggingTrigger_Trigger2" 1 "SensorLoggingTrigger_Trigger1" 0 "SensorLoggingTrigger_NoTrigger" ;
VAL_ 1265 VehicleMode 15 "VehicleMode_NotAvailable" 14 "VehicleMode_Error" 13 "VehicleMode_Spare_7" 12 "VehicleMode_Spare_6" 11 "VehicleMode_Spare_5" 10 "VehicleMode_Spare_4" 9 "VehicleMode_Spare_3" 8 "VehicleMode_Spare_2" 7 "VehicleMode_Spare_1" 6 "VehicleMode_Running" 5 "VehicleMode_Cranking" 4 "VehicleMode_PreRunning" 3 "VehicleMode_Accessory" 2 "VehicleMode_Living" 1 "VehicleMode_Parked" 0 "VehicleMode_Hibernate" ;
VAL_ 1265 TrailerConnected 3 "NoYes_NotAvailable" 2 "NoYes_Error" 1 "NoYes_Yes" 0 "NoYes_No" ;
VAL_ 1265 PloughLampModeStatus 3 "InactiveActive_NotAvailable" 2 "InactiveActive_Error" 1 "InactiveActive_Active" 0 "InactiveActive_Inactive" ;
VAL_ 1265 LaneChangeStatus 15 "LaneChangeStatus_NotAvailable" 14 "LaneChangeStatus_Error" 13 "LaneChangeStatus_Spare11" 12 "LaneChangeStatus_Spare10" 11 "LaneChangeStatus_Spare9" 10 "LaneChangeStatus_Spare8" 9 "LaneChangeStatus_Spare7" 8 "LaneChangeStatus_Spare6" 7 "LaneChangeStatus_Spare5" 6 "LaneChangeStatus_Spare4" 5 "LaneChangeStatus_Spare3" 4 "LaneChangeStatus_Spare2" 3 "LaneChangeStatus_Spare1" 2 "LaneChangeStatus_RightLaneChangeIntention" 1 "LaneChangeStatus_LeftLaneChangeIntention" 0 "LaneChangeStatus_NotActive" ;
VAL_ 1265 WiperModeStatus 7 "WiperModeStatus_NotAvailable" 6 "WiperModeStatus_ErrorIndicator" 5 "WiperModeStatus_Spare02" 4 "WiperModeStatus_Spare01" 3 "WiperModeStatus_Spare" 2 "WiperModeStatus_HighSpeedWiping" 1 "WiperModeStatus_LowSpeedWiping" 0 "WiperModeStatus_WiperOff" ;
VAL_ 1265 FLRPowerDemand 3 "Request_NotAvailable" 2 "Request_Error" 1 "Request_RequestActive" 0 "Request_NotRequested" ;
SIG_GROUP_ 786 FLRObj03_sg 1 : FLRObj03_ObjClass FLRObj03_LongAccVar FLRObj03_LifeTime FLRObj03_LatExtLeft FLRObj03_ObjDynClass FLRObj03_LongVel FLRObj03_ObstacleConf FLRObj03_LatExtRight FLRObj03_CRC FLRObj03_Height FLRObj03_LatExtRtVar FLRObj03_AsilLvl FLRObj03_TimeStamp FLRObj03_ExistConf FLRObj03_LatExtLeftVar FLRObj03_ObstacleConfRestricted FLRObj03_Heading FLRObj03_LatPosVar FLRObj03_LatPos FLRObj03_LongExtBkVar FLRObj03_CoastIndex FLRObj03_LatAccVar FLRObj03_LongAcc FLRObj03_ObjDynClassRestricted FLRObj03_ObjClassConf FLRObj03_LatVel FLRObj03_LongExtFront FLRObj03_LongVelVar FLRObj03_LatVelVar FLRObj03_LongExtBack FLRObj03_LongPos FLRObj03_HeadingVar FLRObj03_LongPosVar FLRObj03_ObjID FLRObj03_LongExtFrVar FLRObj03_LatAcc FLRObj03_Counter FLRObj03_TrackStatus;
SIG_GROUP_ 785 FLRObj02_sg 1 : FLRObj02_CoastIndex FLRObj02_LongExtBack FLRObj02_ObstacleConfRestricted FLRObj02_LatVel FLRObj02_ObstacleConf FLRObj02_AsilLvl FLRObj02_LatExtLeft FLRObj02_CRC FLRObj02_LongVelVar FLRObj02_Counter FLRObj02_LongPos FLRObj02_LatExtLeftVar FLRObj02_LongExtBkVar FLRObj02_LongVel FLRObj02_ObjDynClassRestricted FLRObj02_LongExtFront FLRObj02_LongAccVar FLRObj02_LatAccVar FLRObj02_LongPosVar FLRObj02_LatExtRtVar FLRObj02_LatPos FLRObj02_ExistConf FLRObj02_LongExtFrVar FLRObj02_ObjClass FLRObj02_Heading FLRObj02_TimeStamp FLRObj02_ObjClassConf FLRObj02_Height FLRObj02_LifeTime FLRObj02_TrackStatus FLRObj02_LatAcc FLRObj02_LatVelVar FLRObj02_ObjDynClass FLRObj02_ObjID FLRObj02_LatExtRight FLRObj02_LatPosVar FLRObj02_HeadingVar FLRObj02_LongAcc;
SIG_GROUP_ 784 FLRObj01_sg 1 : FLRObj01_LatPos FLRObj01_LifeTime FLRObj01_LongExtBack FLRObj01_TimeStamp FLRObj01_LongVelVar FLRObj01_LatExtRight FLRObj01_ObstacleConfRestricted FLRObj01_ObjID FLRObj01_Counter FLRObj01_LongExtBkVar FLRObj01_CRC FLRObj01_AsilLvl FLRObj01_HeadingVar FLRObj01_Heading FLRObj01_ObjClass FLRObj01_LatVelVar FLRObj01_LongPos FLRObj01_LongAcc FLRObj01_LongPosVar FLRObj01_ObjClassConf FLRObj01_LatExtLeftVar FLRObj01_LatAccVar FLRObj01_ObjDynClassRestricted FLRObj01_ExistConf FLRObj01_LatAcc FLRObj01_LongVel FLRObj01_CoastIndex FLRObj01_LongExtFrVar FLRObj01_LatExtRtVar FLRObj01_LongExtFront FLRObj01_LatPosVar FLRObj01_TrackStatus FLRObj01_LatExtLeft FLRObj01_ObstacleConf FLRObj01_ObjDynClass FLRObj01_LatVel FLRObj01_Height FLRObj01_LongAccVar;
SIG_GROUP_ 783 FLRObj00_sg 1 : FLRObj00_LongVelVar FLRObj00_LongPos FLRObj00_LongExtBack FLRObj00_LatPosVar FLRObj00_LongExtFront FLRObj00_AsilLvl FLRObj00_LatExtLeft FLRObj00_LongAccVar FLRObj00_LifeTime FLRObj00_LatExtRight FLRObj00_ObjDynClass FLRObj00_LatAcc FLRObj00_Height FLRObj00_LongExtFrVar FLRObj00_LatPos FLRObj00_LongVel FLRObj00_ObjClassConf FLRObj00_ObjID FLRObj00_LongPosVar FLRObj00_TimeStamp FLRObj00_ObstacleConf FLRObj00_ObjClass FLRObj00_LongExtBkVar FLRObj00_ExistConf FLRObj00_LatVelVar FLRObj00_CoastIndex FLRObj00_ObstacleConfRestricted FLRObj00_TrackStatus FLRObj00_LatVel FLRObj00_LongAcc FLRObj00_CRC FLRObj00_Heading FLRObj00_ObjDynClassRestricted FLRObj00_HeadingVar FLRObj00_LatAccVar FLRObj00_LatExtRtVar FLRObj00_LatExtLeftVar FLRObj00_Counter;
SIG_GROUP_ 860 LeftRoadBoundary_sg 1 : LeftRoadBoundary_CoastIndex LeftRoadBoundary_DxStart LeftRoadBoundary_LifeTime LeftRoadBoundary_TimeStamp LeftRoadBoundary_HeadingAngle LeftRoadBoundary_Curvature LeftRoadBoundary_CRC LeftRoadBoundary_CurvatureRate LeftRoadBoundary_Type LeftRoadBoundary_LatDistVar LeftRoadBoundary_TrackStatus LeftRoadBoundary_Counter LeftRoadBoundary_LatDist LeftRoadBoundary_Confidence LeftRoadBoundary_DxEnd;
SIG_GROUP_ 858 FLREgoAssumpt_sg 1 : FLREgoAssumpt_EgoRoadEnd FLREgoAssumpt_EgoLongAcc FLREgoAssumpt_VelCorrFactor FLREgoAssumpt_EgoRoadCurvRate FLREgoAssumpt_TimeStamp FLREgoAssumpt_EgoYawRate FLREgoAssumpt_EgoRoadHeading FLREgoAssumpt_EgoRoadCurvature FLREgoAssumpt_EgoLongVel;
SIG_GROUP_ 512 FwdRadarStatus2_sg 1 : FwdRadarStatus2_CRC FwdRadarStatus2_Status FwdRadarStatus2_SqC;
SIG_GROUP_ 512 FwdRdr_sg 1 : FwdRdr_CalibPausedYaw FwdRdr_CalibState FwdRdr_CalibPausedAcc FwdRdr_CalibPausedSpeed FwdRdr_CalibProgress;
SIG_GROUP_ 512 FwdSensingRadarStat_sg 1 : FwdSensingRadarStat_CRC FwdSensingRadarStat_TimeSynch FwdSensingRadarStat_Counter FwdSensingRadarStat_DecalDetect FwdSensingRadarStat_TargetDetect FwdSensingRadarStat_BarrierDetec;
SIG_GROUP_ 1527 DiagFaultStat_FLR_sg 1 : DiagFaultStat_FLR_DtcIdB DiagFaultStat_FLR_FailTA DiagFaultStat_FLR_EcuAdr DiagFaultStat_FLR_DtcIdA DiagFaultStat_FLR_FailTB;
SIG_GROUP_ 257 DACUTimeSync_sg 1 : DACUTimeSync_Time DACUTimeSync_CRC DACUTimeSync_UserByte DACUTimeSync_SeqCnt DACUTimeSync_Type DACUTimeSync_TimeDomain;
SIG_GROUP_ 761 DACUTimeSyncOFS_sg 1 : DACUTimeSyncOFS_TimeDomain DACUTimeSyncOFS_TypeOFS DACUTimeSyncOFS_SeqCnt DACUTimeSyncOFS_UserByte0 DACUTimeSyncOFS_OfsTimeSec DACUTimeSyncOFS_CRCOFS;
SIG_GROUP_ 760 DACUTimeSyncOFNS_sg 1 : DACUTimeSyncOFNS_SeqCnt DACUTimeSyncOFNS_SGW DACUTimeSyncOFNS_OfsTimeNsec DACUTimeSyncOFNS_CRCOFNS DACUTimeSyncOFNS_TimeDomain DACUTimeSyncOFNS_TypeOFNS;
SIG_GROUP_ 279 EgoPathPrediction_sg 1 : EgoPathPrediction_Curvature EgoPathPrediction_HeadingAngle EgoPathPrediction_CurvatureRate EgoPathPrediction_ConfCoeffA1 EgoPathPrediction_DxEnd EgoPathPrediction_ConfCoeffA3 EgoPathPrediction_ConfCoeffA0 EgoPathPrediction_ConfCoeffA2;
SIG_GROUP_ 275 EgoMotionXYplane_sg 1 : EgoMotionXYplane_LongMotDirConf EgoMotionXYplane_LongSpeed EgoMotionXYplane_EffectiveWheelB EgoMotionXYplane_LatAccVariance EgoMotionXYplane_YawRateVariance EgoMotionXYplane_LateralSpeed EgoMotionXYplane_LongSpeedVar EgoMotionXYplane_LateralAcc EgoMotionXYplane_LongMotionDir EgoMotionXYplane_LatencyEst EgoMotionXYplane_LongAcc EgoMotionXYplane_Counter EgoMotionXYplane_Curvature EgoMotionXYplane_CRC EgoMotionXYplane_ReferencePointX EgoMotionXYplane_LongAccVariance EgoMotionXYplane_YawRateComp EgoMotionXYplane_ChassisDynPitch EgoMotionXYplane_LatSpeedVar;
SIG_GROUP_ 277 EgoMotionRaw_sg 1 : EgoMotionRaw_YCEngineActive EgoMotionRaw_ASREngineA EgoMotionRaw_ASRBrakeA EgoMotionRaw_RelLvlRrAxleRight EgoMotionRaw_ROPBrakeActive EgoMotionRaw_Counter EgoMotionRaw_RelLvlRrAxleLeft EgoMotionRaw_AccKckDwn EgoMotionRaw_VDCFullyOperational EgoMotionRaw_FrontWheelAngle EgoMotionRaw_BrakePedalPosition EgoMotionRaw_ABSOp EgoMotionRaw_RAxleRightWSpeed EgoMotionRaw_GrossCombVehWeight EgoMotionRaw_CRC EgoMotionRaw_FrAxleRightWSpeed EgoMotionRaw_ABSActive EgoMotionRaw_SteeringWheelAngle EgoMotionRaw_RelLvlFrAxleLeft EgoMotionRaw_ROPEngineActive EgoMotionRaw_FrAxleLeftWSpeed EgoMotionRaw_YCBrakeActive EgoMotionRaw_SteeringWheelRatio EgoMotionRaw_AccPedalPos EgoMotionRaw_RelLvlFrAxleRight EgoMotionRaw_RAxleLeftWSpeed EgoMotionRaw_TrailerConStatus;
SIG_GROUP_ 333 HUALEDCtrl00_sg 1 : HUALEDCtrl00_Red HUALEDCtrl00_Orange;
SIG_GROUP_ 333 HUALEDCtrl01_sg 1 : HUALEDCtrl01_Orange HUALEDCtrl01_Red;
SIG_GROUP_ 333 HUAFading_sg 1 : HUAFading_Fadingtime HUAFading_FadingCtrl;
SIG_GROUP_ 333 HUALEDCtrl03_sg 1 : HUALEDCtrl03_Orange HUALEDCtrl03_Red;
SIG_GROUP_ 333 HUALEDCtrl05_sg 1 : HUALEDCtrl05_Red HUALEDCtrl05_Orange;
SIG_GROUP_ 333 HUALEDCtrl02_sg 1 : HUALEDCtrl02_Orange HUALEDCtrl02_Red;
SIG_GROUP_ 333 HUALEDCtrl06_sg 1 : HUALEDCtrl06_Orange HUALEDCtrl06_Red;
SIG_GROUP_ 333 HUALEDCtrl04_sg 1 : HUALEDCtrl04_Orange HUALEDCtrl04_Red;
SIG_GROUP_ 1543 VIN_DACU_sg 1 : VIN_DACU_Byte02 VIN_DACU_Byte09 VIN_DACU_Byte04 VIN_DACU_Byte07 VIN_DACU_Byte11 VIN_DACU_Byte06 VIN_DACU_Byte08 VIN_DACU_Byte15 VIN_DACU_Byte14 VIN_DACU_Byte16 VIN_DACU_Byte12 VIN_DACU_Byte01 VIN_DACU_Byte10 VIN_DACU_Byte03 VIN_DACU_Byte00 VIN_DACU_Byte05 VIN_DACU_Byte13;
SIG_GROUP_ 1552 DACUSwVersion_sg 1 : DACUSwVersion_Substring0 DACUSwVersion_Substring6 DACUSwVersion_Substring2 DACUSwVersion_Substring5 DACUSwVersion_Substring7 DACUSwVersion_Substring1 DACUSwVersion_Substring3 DACUSwVersion_Substring4;
